VERSION "HNNBNNNYNNNNNNNNNNNNNNNNNNNNNNNNNNNNNNNNNN/4/%%%/4/'%**4NNN///"

NS_ :

BS_:

BU_: AFS Airbag Allrad BAP_Tester BMS_Hybrid Bremse_MK60EC Bremse_MK70MABS Bremse_TRW_EBC450M Bremse_TRW_ESP Daempfer EPB_TRW EPB_TRW_VW411CS FLA Gateway_PQ35 Gateway_Zusatz_EGolf Getriebe_AG6 Getriebe_DQ Getriebe_DQ_Hyb Getriebe_Sele Gurtmikro_PQ35 HCA Ladegeraet_EGolf LEH_Hybrid LH_EPS_APA LH_EPS_ZF_2G LH_EPS_ZF_3G LPG_Interface_Box LWR LWS Magne_Ride Motor_Diesel Motor_EGolf Motor_Hybrid Motor_Otto PDC_PLA Quersperre_VAQ RKA_Plus SAK Waehlhebel Waehlhebel_Sele

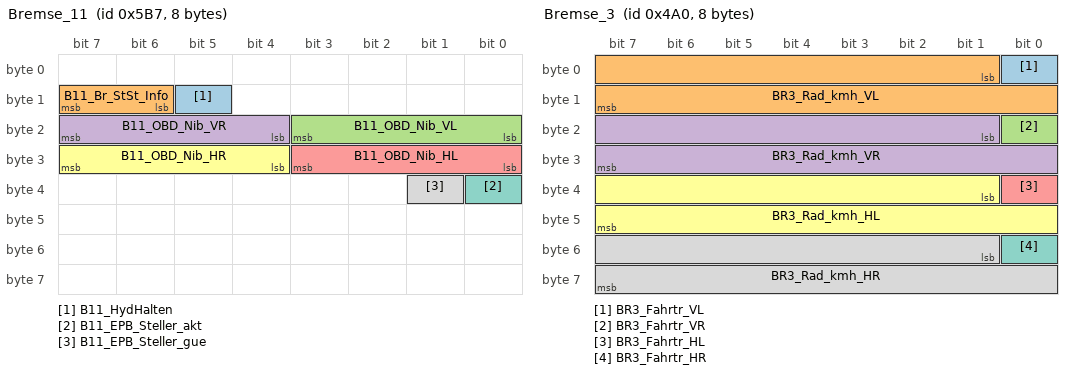
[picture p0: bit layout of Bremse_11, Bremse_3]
BO_ 1463 Bremse_11: 8 Bremse_MK60EC
 SG_ B11_HydHalten : 13|1@1+ (1,0) [0|1] ""  EPB_TRW_VW411CS,Getriebe_DQ,Getriebe_DQ_Hyb,Motor_Diesel,Motor_Otto,PDC_PLA
 SG_ B11_Br_StSt_Info : 14|2@1+ (1,0) [0|3] ""  EPB_TRW_VW411CS,Motor_Diesel,Motor_Otto
 SG_ B11_OBD_Nib_VL : 16|4@1+ (1,0) [0|15] ""  Motor_Diesel,Motor_Otto
 SG_ B11_OBD_Nib_VR : 20|4@1+ (1,0) [0|15] ""  Motor_Diesel,Motor_Otto
 SG_ B11_OBD_Nib_HL : 24|4@1+ (1,0) [0|15] ""  Motor_Diesel,Motor_Otto
 SG_ B11_OBD_Nib_HR : 28|4@1+ (1,0) [0|15] ""  Motor_Diesel,Motor_Otto
 SG_ B11_EPB_Steller_akt : 32|1@1+ (1,0) [0|1] ""  Motor_Diesel,Motor_Otto
 SG_ B11_EPB_Steller_gue : 33|1@1+ (1,0) [0|1] ""  Motor_Diesel,Motor_Otto

BO_ 1440 Bremse_2: 8 Bremse_MK60EC
 SG_ BR2_Querbeschl m0 : 0|8@1+ (0.01,-1.27) [-1.27|1.27] "Unit_ForceOfGravi"  AFS,Allrad,Daempfer,Gateway_PQ35,Getriebe_DQ,Getriebe_DQ_Hyb,Getriebe_Sele,HCA,LWR,Magne_Ride,Motor_Diesel,Motor_Otto,RKA_Plus
 SG_ BR2_Zahnzahl m1 : 0|6@1+ (1,0) [0|63] ""  Gateway_PQ35,Getriebe_DQ,Getriebe_DQ_Hyb,PDC_PLA,RKA_Plus
 SG_ BR2_Querb_Zahn M : 8|1@1+ (1,0) [0|1] ""  AFS,Allrad,Daempfer,Gateway_PQ35,Getriebe_DQ,Getriebe_DQ_Hyb,Getriebe_Sele,HCA,LWR,Magne_Ride,Motor_Diesel,Motor_Otto,PDC_PLA,RKA_Plus
 SG_ BR2_mi_Radgeschw : 9|15@1+ (0.002,0) [0|65.278] "Unit_Hertz"  Gateway_PQ35,Getriebe_DQ,Getriebe_DQ_Hyb
 SG_ BR2_Lampe_ABS : 24|1@1+ (1,0) [0|1] ""  Airbag,Gateway_PQ35
 SG_ BR2_Lampe_ASR : 25|1@1+ (1,0) [0|1] ""  Gateway_PQ35,PDC_PLA
 SG_ BR2_Lampe_BK : 26|1@1+ (1,0) [0|1] ""  Gateway_PQ35
 SG_ BR2_Lampe_RKA : 27|1@1+ (1,0) [0|1] ""  Gateway_PQ35
 SG_ BR2_Zaehler : 28|4@1+ (1,0) [0|15] ""  Daempfer,Gateway_PQ35,HCA,Magne_Ride
 SG_ BR2_Text : 32|4@1+ (1,0) [0|15] ""  Gateway_PQ35
 SG_ BR2_Aku_Warn : 36|2@1+ (1,0) [0|3] ""  Gateway_PQ35
 SG_ BR2_HDC_aktiv : 38|1@1+ (1,0) [0|1] ""  Gateway_PQ35,Getriebe_DQ,Getriebe_DQ_Hyb,Motor_Diesel,Motor_Hybrid,Motor_Otto
 SG_ BR2_Blinkmode : 39|1@1+ (1,0) [0|1] ""  Gateway_PQ35
 SG_ BR2_Wegimpulse : 40|11@1+ (1,0) [0|2047] ""  Gateway_PQ35,Getriebe_DQ,Getriebe_DQ_Hyb
 SG_ BR2_Ueberl_Imp : 51|1@1+ (1,0) [0|1] ""  Gateway_PQ35
 SG_ BR2_Fehlereintr : 52|1@1+ (1,0) [0|1] ""  Gateway_PQ35
 SG_ BR2_LampeHDC : 53|1@1+ (1,0) [0|1] ""  Gateway_PQ35,Getriebe_DQ,Getriebe_DQ_Hyb
 SG_ BR2_QB_Querbeschl m0 : 54|1@1+ (1,0) [0|1] ""  AFS,Allrad,Gateway_PQ35,HCA,LWR,Magne_Ride,Motor_Diesel,Motor_Otto,RKA_Plus
 SG_ BR2_Sta_Imp : 55|1@1+ (1,0) [0|1] ""  Gateway_PQ35
 SG_ BR2_Impulszahl : 56|6@1+ (1,0) [0|63] ""  Gateway_PQ35,Getriebe_DQ,Getriebe_DQ_Hyb
 SG_ BR2_SleepInd : 62|1@1+ (1,0) [0|1] ""  Gateway_PQ35
 SG_ BR2_Sta_Quer : 63|1@1+ (1,0) [0|1] ""  Gateway_PQ35,Getriebe_DQ,Getriebe_DQ_Hyb

BO_ 1184 Bremse_3: 8 Bremse_MK60EC
 SG_ BR3_Fahrtr_VL : 0|1@1+ (1,0) [0|1] ""  AFS,EPB_TRW_VW411CS,Gateway_PQ35,LWR,Magne_Ride
 SG_ BR3_Rad_kmh_VL : 1|15@1+ (0.01,0) [0|326.39] "Unit_KiloMeterPerHour"  AFS,Allrad,EPB_TRW,EPB_TRW_VW411CS,Gateway_PQ35,Getriebe_AG6,Getriebe_DQ,Getriebe_DQ_Hyb,Getriebe_Sele,LH_EPS_APA,LH_EPS_ZF_2G,LH_EPS_ZF_3G,LWR,LWS,Magne_Ride,Motor_Diesel,Motor_EGolf,Motor_Hybrid,Motor_Otto,PDC_PLA
 SG_ BR3_Fahrtr_VR : 16|1@1+ (1,0) [0|1] ""  AFS,EPB_TRW_VW411CS,Gateway_PQ35,LWR,Magne_Ride
 SG_ BR3_Rad_kmh_VR : 17|15@1+ (0.01,0) [0|326.39] "Unit_KiloMeterPerHour"  AFS,Allrad,EPB_TRW,EPB_TRW_VW411CS,Gateway_PQ35,Getriebe_AG6,Getriebe_DQ,Getriebe_DQ_Hyb,Getriebe_Sele,LH_EPS_APA,LH_EPS_ZF_2G,LH_EPS_ZF_3G,LWR,LWS,Magne_Ride,Motor_Diesel,Motor_EGolf,Motor_Hybrid,Motor_Otto,PDC_PLA
 SG_ BR3_Fahrtr_HL : 32|1@1+ (1,0) [0|1] ""  EPB_TRW_VW411CS,Gateway_PQ35,Magne_Ride
 SG_ BR3_Rad_kmh_HL : 33|15@1+ (0.01,0) [0|326.39] "Unit_KiloMeterPerHour"  AFS,Allrad,EPB_TRW,EPB_TRW_VW411CS,Gateway_PQ35,Getriebe_AG6,Getriebe_DQ,Getriebe_DQ_Hyb,Getriebe_Sele,LH_EPS_APA,LH_EPS_ZF_2G,LH_EPS_ZF_3G,LWR,LWS,Magne_Ride,Motor_Diesel,Motor_EGolf,Motor_Hybrid,Motor_Otto,PDC_PLA
 SG_ BR3_Fahrtr_HR : 48|1@1+ (1,0) [0|1] ""  EPB_TRW_VW411CS,Gateway_PQ35,Magne_Ride
 SG_ BR3_Rad_kmh_HR : 49|15@1+ (0.01,0) [0|326.39] "Unit_KiloMeterPerHour"  AFS,Allrad,EPB_TRW,EPB_TRW_VW411CS,Gateway_PQ35,Getriebe_AG6,Getriebe_DQ,Getriebe_DQ_Hyb,Getriebe_Sele,LH_EPS_APA,LH_EPS_ZF_2G,LH_EPS_ZF_3G,LWR,LWS,Magne_Ride,Motor_Diesel,Motor_EGolf,Motor_Hybrid,Motor_Otto,PDC_PLA

BO_ 672 Bremse_4: 8 Bremse_MK60EC
 SG_ BR4_Vorgabe_Mi_ m0 : 0|8@1+ (7,-896) [-896|882] "Unit_NewtoMeter"  Allrad,Gateway_PQ35
 SG_ BR4_Vorgabe_Mi m1 : 0|8@1+ (0.78740157480315,-100) [0|100] "Unit_PerCent"  Gateway_PQ35
 SG_ BR4_Vorgabe_Max m2 : 0|8@1+ (10,0) [0|2540] "Unit_NewtoMeter"  Gateway_PQ35,Quersperre_VAQ
 SG_ BR4_Vorgabe_Hi m1 : 8|8@1+ (0.78740157480315,-100) [0|100] "Unit_PerCent"  Gateway_PQ35
 SG_ BR4_Vorgabe_Min m2 : 8|8@1+ (10,0) [0|2540] "Unit_NewtoMeter"  Gateway_PQ35,Quersperre_VAQ
 SG_ BR4_Einheit M : 16|2@1+ (1,0) [0|3] ""  Allrad,Gateway_PQ35,Quersperre_VAQ
 SG_ BR4_Schwelle : 18|2@1+ (1,0) [0|3] ""  Gateway_PQ35,Getriebe_AG6,Motor_Hybrid,Motor_Otto
 SG_ BR4_Abschaltung_VL : 20|1@1+ (1,0) [0|1] ""  Gateway_PQ35
 SG_ BR4_Abschaltung_VR : 21|1@1+ (1,0) [0|1] ""  Gateway_PQ35
 SG_ BR4_Abschaltung_HL : 22|1@1+ (1,0) [0|1] ""  Gateway_PQ35
 SG_ BR4_Abschaltung_HR : 23|1@1+ (1,0) [0|1] ""  Gateway_PQ35
 SG_ BR4_Lampe_RKA : 24|1@1+ (1,0) [0|1] ""  Gateway_PQ35
 SG_ BR4_Summer_RKA : 25|1@1+ (1,0) [0|1] ""  Gateway_PQ35
 SG_ BR4_Lampentrennung_gue : 26|1@1+ (1,0) [0|1] ""  Gateway_PQ35
 SG_ BR4_Lampe_ASRESP : 27|1@1+ (1,0) [0|1] ""  Gateway_PQ35
 SG_ BR4_ESP_Off : 28|1@1+ (1,0) [0|1] ""  Gateway_PQ35
 SG_ BR1_ASR_ESP : 29|1@1+ (1,0) [0|1] ""  Gateway_PQ35
 SG_ BR4_RKA_Verbau : 30|2@1+ (1,0) [0|3] ""  Gateway_PQ35
 SG_ BR4_Unterdruck : 32|8@1+ (4,0) [0|1016] "Unit_MilliBar"  Gateway_PQ35,Getriebe_AG6,Motor_Hybrid,Motor_Otto
 SG_ BR4_Status_ESP : 40|4@1+ (1,0) [0|15] ""  Gateway_PQ35,Quersperre_VAQ
 SG_ BR4_Zaehler : 52|4@1+ (1,0) [0|15] ""  Gateway_PQ35,Quersperre_VAQ
 SG_ BR4_Checksum : 56|8@1+ (1,0) [0|255] ""  Gateway_PQ35,Quersperre_VAQ

BO_ 1192 Bremse_5: 8 Bremse_MK60EC
 SG_ BR5_Giergeschw : 0|14@1+ (0.01,0) [0|100] "Unit_DegreOfArcPerSecond"  AFS,Allrad,Daempfer,FLA,Gateway_PQ35,HCA,LWR,Magne_Ride,PDC_PLA,RKA_Plus
 SG_ BR5_Sta_Gierrate : 14|1@1+ (1,0) [0|1] ""  AFS,Allrad,Daempfer,FLA,Gateway_PQ35,HCA,LWR,Magne_Ride,PDC_PLA,RKA_Plus
 SG_ BR5_Vorzeichen : 15|1@1+ (1,0) [0|1] ""  AFS,Allrad,Daempfer,FLA,Gateway_PQ35,HCA,LWR,Magne_Ride,PDC_PLA,RKA_Plus
 SG_ BR5_Bremsdruck : 16|12@1+ (0.1,0) [0|409.4] "Unit_Bar"  Daempfer,EPB_TRW,EPB_TRW_VW411CS,Gateway_PQ35,Gateway_Zusatz_EGolf,Getriebe_DQ,Getriebe_DQ_Hyb,HCA,Magne_Ride,Motor_Diesel,Motor_Otto,PDC_PLA
 SG_ BR5_Stillstand : 28|1@1+ (1,0) [0|1] ""  Gateway_PQ35,HCA,Magne_Ride,PDC_PLA
 SG_ BR5_Druckgueltig : 29|1@1+ (1,0) [0|1] ""  Daempfer,EPB_TRW,EPB_TRW_VW411CS,Gateway_PQ35,Getriebe_DQ,Getriebe_DQ_Hyb,HCA,Magne_Ride,Motor_Diesel,Motor_Otto,PDC_PLA
 SG_ BR5_Sta_Druck : 30|1@1+ (1,0) [0|1] ""  EPB_TRW_VW411CS,Gateway_PQ35
 SG_ BR5_Sign_Druck : 31|1@1+ (1,0) [0|1] ""  Daempfer,EPB_TRW_VW411CS,Gateway_PQ35,Getriebe_DQ,Getriebe_DQ_Hyb,HCA,Magne_Ride,Motor_Diesel,Motor_Otto
 SG_ ESP_Anforderung_EPB : 36|2@1+ (1,0) [0|3] ""  EPB_TRW_VW411CS,Gateway_PQ35
 SG_ ESP_Autohold_aktiv : 38|1@1+ (1,0) [0|1] ""  EPB_TRW_VW411CS,Gateway_PQ35
 SG_ ESP_Autohold_Standby : 39|1@1+ (1,0) [0|1] ""  EPB_TRW_VW411CS,Gateway_PQ35
 SG_ BR5_Anhi_Sta : 40|1@1+ (1,0) [0|1] ""  Gateway_PQ35,Getriebe_DQ,Getriebe_DQ_Hyb
 SG_ BR5_Anhi_akt : 41|1@1+ (1,0) [0|1] ""  Gateway_PQ35,Getriebe_DQ,Getriebe_DQ_Hyb
 SG_ BR5_v_Ueberw : 42|1@1+ (1,0) [0|1] ""  Gateway_PQ35
 SG_ BR5_AnhStabAktiv : 43|1@1+ (1,0) [0|1] ""  Gateway_PQ35
 SG_ BR5_Notbremsung : 44|1@1+ (1,0) [0|1] ""  Gateway_PQ35
 SG_ BR5_Fahrer_tritt_ZBR_Schw : 45|1@1+ (1,0) [0|1] ""  Gateway_PQ35
 SG_ BR5_AWV2_Bremsruck : 46|1@1+ (1,0) [0|1] ""  Gateway_PQ35
 SG_ BR5_AWV2_Fehler : 47|1@1+ (1,0) [0|1] ""  Gateway_PQ35
 SG_ BR5_ZT_Rueckk_Umsetz : 48|1@1+ (1,0) [0|1] ""  Gateway_PQ35
 SG_ BR5_ANB_CM_Rueckk_Umsetz : 49|1@1+ (1,0) [0|1] ""  Gateway_PQ35
 SG_ BR5_ECD_Lampe : 51|1@1+ (1,0) [0|1] ""  Gateway_PQ35
 SG_ BR5_Zaehler : 52|4@1+ (1,0) [0|15] ""  Daempfer,EPB_TRW,EPB_TRW_VW411CS,Gateway_PQ35,HCA,Magne_Ride,Motor_Diesel,Motor_Otto,PDC_PLA
 SG_ BR5_Checksumme : 56|8@1+ (1,0) [0|255] ""  Daempfer,EPB_TRW,EPB_TRW_VW411CS,Gateway_PQ35,HCA,Magne_Ride,Motor_Diesel,Motor_Otto

BO_ 428 Bremse_8: 8 Bremse_MK60EC
 SG_ BR8_Checksumme : 0|8@1+ (1,0) [0|255] ""  EPB_TRW,EPB_TRW_VW411CS,Gateway_PQ35,Getriebe_AG6,Getriebe_DQ,Getriebe_DQ_Hyb,Motor_Diesel,Motor_Otto,PDC_PLA
 SG_ BR8_Zaehler : 8|4@1+ (1,0) [0|15] ""  EPB_TRW,EPB_TRW_VW411CS,Gateway_PQ35,Getriebe_AG6,Motor_Diesel,Motor_Otto,PDC_PLA
 SG_ BR8_Sta_ACC_Anf : 12|1@1+ (1,0) [0|1] ""  Gateway_PQ35,Getriebe_DQ,Motor_Diesel,Motor_Otto
 SG_ BR8_Verz_EPB_akt : 13|1@1+ (1,0) [0|1] ""  EPB_TRW,EPB_TRW_VW411CS,Gateway_PQ35,Motor_Diesel,Motor_Otto
 SG_ BR8_Sta_Br_temp : 14|1@1+ (1,0) [0|1] ""  Gateway_PQ35,Motor_Diesel,Motor_Otto
 SG_ BR8_Sta_Br_Druck : 15|1@1+ (1,0) [0|1] ""  Gateway_PQ35,Motor_Diesel,Motor_Otto
 SG_ BR8_Istbeschl : 32|9@1+ (0.02,-7.22) [-7.22|2.98] "Unit_MeterPerSeconSquar"  Gateway_PQ35,Motor_Diesel,Motor_Otto
 SG_ BR8_Sta_HW_BLS : 41|1@1+ (1,0) [0|1] ""  Gateway_PQ35
 SG_ BR8_QB_LBeschl : 42|1@1+ (1,0) [0|1] ""  EPB_TRW_VW411CS,Gateway_PQ35,Getriebe_DQ,Getriebe_DQ_Hyb,Motor_Diesel,Motor_Otto,PDC_PLA
 SG_ BR8_ESC_Mode : 43|2@1+ (1,0) [0|3] ""  Gateway_PQ35
 SG_ BR8_aktBrSyst : 45|1@1+ (1,0) [0|1] ""  Gateway_PQ35,Motor_Diesel,Motor_Otto
 SG_ BR8_Fa_bremst : 46|1@1+ (1,0) [0|1] ""  Gateway_PQ35,Motor_Diesel,Motor_Otto
 SG_ BR8_StaBrSyst : 47|1@1+ (1,0) [0|1] ""  Gateway_PQ35,Motor_Diesel,Motor_Otto
 SG_ BR8_Laengsbeschl : 48|10@1+ (0.03125,-16) [-15.96875|15.9375] "Unit_MeterPerSeconSquar"  EPB_TRW_VW411CS,Gateway_PQ35,Getriebe_AG6,Getriebe_DQ,Getriebe_DQ_Hyb,Motor_Diesel,Motor_Otto,PDC_PLA
 SG_ BR8_Sta_ADR_BR : 58|1@1+ (1,0) [0|1] ""  Gateway_PQ35,Motor_Diesel,Motor_Otto
 SG_ BR8_Quattro : 59|1@1+ (1,0) [0|1] ""  Gateway_PQ35
 SG_ BR8_Sta_VerzReg : 60|1@1+ (1,0) [0|1] ""  Gateway_PQ35,Motor_Diesel,Motor_Otto
 SG_ BR8_Sta_BLS : 61|1@1+ (1,0) [0|1] ""  Gateway_PQ35,Motor_Diesel,Motor_Otto
 SG_ BR8_Verz_EPB : 62|1@1+ (1,0) [0|1] ""  EPB_TRW,EPB_TRW_VW411CS,Gateway_PQ35
 SG_ BR8_Check_EPB : 63|1@1+ (1,0) [0|1] ""  EPB_TRW_VW411CS,Gateway_PQ35

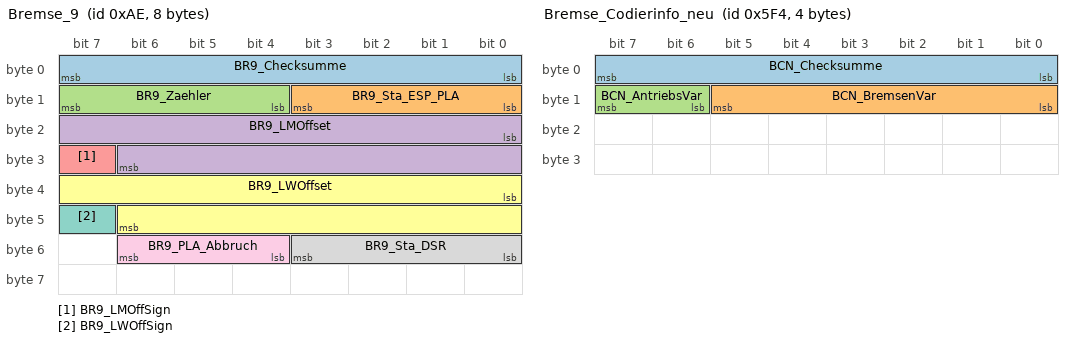
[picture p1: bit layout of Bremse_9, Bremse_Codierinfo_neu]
BO_ 174 Bremse_9: 8 Bremse_MK60EC
 SG_ BR9_Checksumme : 0|8@1+ (1,0) [0|255] ""  LH_EPS_APA,LH_EPS_ZF_2G,LH_EPS_ZF_3G
 SG_ BR9_Sta_ESP_PLA : 8|4@1+ (1,0) [0|15] ""  Getriebe_DQ,Getriebe_DQ_Hyb,PDC_PLA
 SG_ BR9_Zaehler : 12|4@1+ (1,0) [0|15] ""  LH_EPS_APA,LH_EPS_ZF_2G,LH_EPS_ZF_3G
 SG_ BR9_LMOffset : 16|15@1+ (0.0003052,0) [0|10.0004884] "Unit_NewtoMeter"  LH_EPS_APA,LH_EPS_ZF_2G,LH_EPS_ZF_3G
 SG_ BR9_LMOffSign : 31|1@1+ (1,0) [0|1] ""  LH_EPS_APA,LH_EPS_ZF_2G,LH_EPS_ZF_3G
 SG_ BR9_LWOffset : 32|15@1+ (0.04375,0) [0|1433.55625] "Unit_DegreOfArc"  LH_EPS_APA,LH_EPS_ZF_2G,LH_EPS_ZF_3G
 SG_ BR9_LWOffSign : 47|1@1+ (1,0) [0|1] ""  LH_EPS_APA,LH_EPS_ZF_2G,LH_EPS_ZF_3G
 SG_ BR9_Sta_DSR : 48|4@1+ (1,0) [0|15] ""  LH_EPS_APA,LH_EPS_ZF_2G,LH_EPS_ZF_3G
 SG_ BR9_PLA_Abbruch : 52|3@1+ (1,0) [0|7] ""  PDC_PLA

BO_ 1524 Bremse_Codierinfo_neu: 4 Airbag
 SG_ BCN_Checksumme : 0|8@1+ (1,0) [0|255] ""  Bremse_MK60EC
 SG_ BCN_BremsenVar : 8|6@1+ (1,0) [0|63] ""  Bremse_MK60EC
 SG_ BCN_AntriebsVar : 14|2@1+ (1,0) [0|3] ""  Bremse_MK60EC

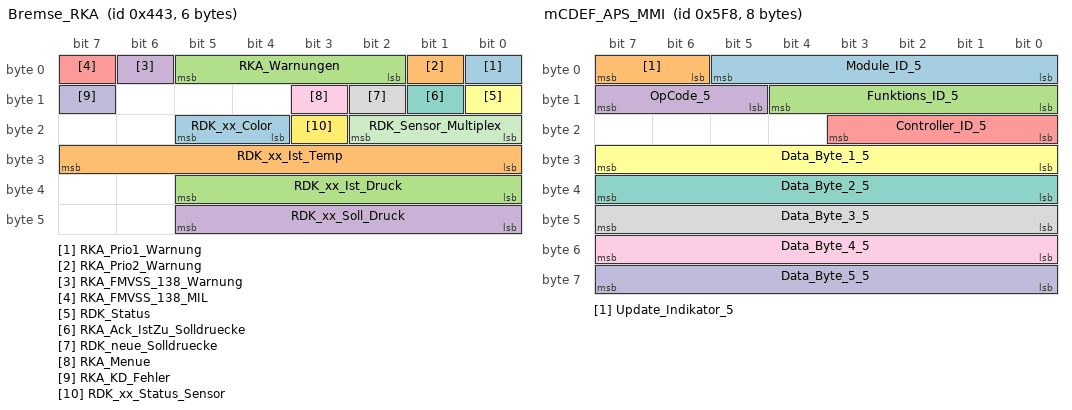
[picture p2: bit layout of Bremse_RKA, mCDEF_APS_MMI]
BO_ 1091 Bremse_RKA: 6 Bremse_MK60EC
 SG_ RKA_Prio1_Warnung : 0|1@1+ (1,0) [0|1] ""  Gateway_PQ35
 SG_ RKA_Prio2_Warnung : 1|1@1+ (1,0) [0|1] ""  Gateway_PQ35
 SG_ RKA_Warnungen : 2|4@1+ (1,0) [0|15] ""  Gateway_PQ35
 SG_ RKA_FMVSS_138_Warnung : 6|1@1+ (1,0) [0|1] ""  Gateway_PQ35
 SG_ RKA_FMVSS_138_MIL : 7|1@1+ (1,0) [0|1] ""  Gateway_PQ35
 SG_ RDK_Status : 8|1@1+ (1,0) [0|1] ""  Gateway_PQ35
 SG_ RKA_Ack_IstZu_Solldruecke : 9|1@1+ (1,0) [0|1] ""  Gateway_PQ35
 SG_ RDK_neue_Solldruecke : 10|1@1+ (1,0) [0|1] ""  Gateway_PQ35
 SG_ RKA_Menue : 11|1@1+ (1,0) [0|1] ""  Gateway_PQ35
 SG_ RKA_KD_Fehler : 15|1@1+ (1,0) [0|1] ""  Gateway_PQ35
 SG_ RDK_Sensor_Multiplex : 16|3@1+ (1,0) [0|7] ""  Gateway_PQ35
 SG_ RDK_xx_Status_Sensor : 19|1@1+ (1,0) [0|1] ""  Gateway_PQ35
 SG_ RDK_xx_Color : 20|2@1+ (1,0) [0|3] ""  Gateway_PQ35
 SG_ RDK_xx_Ist_Temp : 24|8@1+ (1,-60) [-60|194] "Unit_DegreCelsi"  Gateway_PQ35
 SG_ RDK_xx_Ist_Druck : 32|6@1+ (0.1,0) [0|6.3] "Unit_Bar"  Gateway_PQ35
 SG_ RDK_xx_Soll_Druck : 40|6@1+ (0.1,0) [0|6.3] "Unit_Bar"  Gateway_PQ35

BO_ 1392 BSG_Last: 5 Gateway_PQ35
 SG_ BSL_ZAS_Kl_S : 0|1@1+ (1,0) [0|1] ""  EPB_TRW,EPB_TRW_VW411CS,Gurtmikro_PQ35,Ladegeraet_EGolf
 SG_ BSL_ZAS_Kl_15 : 1|1@1+ (1,0) [0|1] ""  BMS_Hybrid,Bremse_MK60EC,Bremse_TRW_EBC450M,Bremse_TRW_ESP,EPB_TRW,EPB_TRW_VW411CS,FLA,Gurtmikro_PQ35,Ladegeraet_EGolf,Motor_EGolf,PDC_PLA
 SG_ BSL_ZAS_Kl_X : 2|1@1+ (1,0) [0|1] ""  AFS,EPB_TRW,EPB_TRW_VW411CS,FLA,HCA,LWR,Motor_Diesel,PDC_PLA
 SG_ BSL_ZAS_Kl_50 : 3|1@1+ (1,0) [0|1] ""  AFS,Bremse_TRW_EBC450M,EPB_TRW,EPB_TRW_VW411CS,LH_EPS_APA,LWR,Magne_Ride,Motor_Diesel,Motor_EGolf
 SG_ BSL_Parklicht : 4|1@1+ (1,0) [0|1] "" Vector__XXX
 SG_ BSL_LL_Anheb2 : 5|1@1+ (1,0) [0|1] ""  Motor_Diesel,Motor_EGolf,Motor_Hybrid,Motor_Otto
 SG_ BSL_Kl_15_Motor : 6|1@1+ (1,0) [0|1] "" Vector__XXX
 SG_ BSL_Kl_L : 7|1@1+ (1,0) [0|1] "" Vector__XXX
 SG_ BSL_LL_Anheb : 8|1@1+ (1,0) [0|1] ""  Motor_Diesel,Motor_EGolf,Motor_Hybrid,Motor_Otto
 SG_ BSL_Sta_UBat : 9|2@1+ (1,0) [0|3] ""  EPB_TRW
 SG_ BSL_Sta_StBat : 11|2@1+ (1,0) [0|3] "" Vector__XXX
 SG_ BSL_Fehlereintr : 13|1@1+ (1,0) [0|1] "" Vector__XXX
 SG_ BSL_Sta_LWR : 14|1@1+ (1,0) [0|1] "" Vector__XXX
 SG_ BSL_Motor_Haube : 15|1@1+ (1,0) [0|1] ""  Motor_Diesel,Motor_EGolf,Motor_Hybrid,Motor_Otto
 SG_ BSL_UBat : 16|8@1+ (0.05,5) [5|17.7] "Unit_Volt"  EPB_TRW
 SG_ BSL_Hecksch : 24|1@1+ (1,0) [0|1] "" Vector__XXX
 SG_ BSL_Frontsch : 25|1@1+ (1,0) [0|1] "" Vector__XXX
 SG_ BSL_Aussensp : 26|1@1+ (1,0) [0|1] "" Vector__XXX
 SG_ BSL_Sitzheiz : 27|1@1+ (1,0) [0|1] "" Vector__XXX
 SG_ BSL_Lenkradheiz : 28|1@1+ (1,0) [0|1] "" Vector__XXX
 SG_ BSL_Wasserheiz : 29|1@1+ (1,0) [0|1] "" Vector__XXX
 SG_ BSL_Sitzbelueft : 30|1@1+ (1,0) [0|1] "" Vector__XXX
 SG_ BSL_Clima : 31|1@1+ (1,0) [0|1] ""  Motor_Diesel,Motor_EGolf,Motor_Hybrid,Motor_Otto
 SG_ BSL_BSG_2_alt : 32|1@1+ (1,0) [0|1] ""  Motor_Diesel,Motor_EGolf,Motor_Hybrid,Motor_Otto
 SG_ BSL_BSG_3_alt : 33|1@1+ (1,0) [0|1] ""  BMS_Hybrid,Bremse_MK60EC,Bremse_TRW_EBC450M,Bremse_TRW_ESP,EPB_TRW_VW411CS,FLA,Gurtmikro_PQ35,HCA,Ladegeraet_EGolf,LH_EPS_APA,Motor_Diesel,Motor_EGolf,Motor_Hybrid,Motor_Otto,PDC_PLA
 SG_ BSL_Kuehlerlueft : 34|1@1+ (1,0) [0|1] ""  LH_EPS_ZF_2G,LH_EPS_ZF_3G,Motor_Diesel,Motor_EGolf,Motor_Hybrid,Motor_Otto
 SG_ BSL_Ab_Batterie : 35|1@1+ (1,0) [0|1] ""  LH_EPS_APA,LH_EPS_ZF_2G,LH_EPS_ZF_3G,Motor_Diesel,Motor_EGolf,Motor_Hybrid,Motor_Otto
 SG_ BSL_Weckursache_ACAN : 36|2@1+ (1,0) [0|3] ""  Motor_EGolf,Motor_Hybrid,Motor_Otto
 SG_ BSL_Wake_Up_ACAN : 38|1@1+ (1,0) [0|1] ""  Motor_EGolf,Motor_Hybrid,Motor_Otto
 SG_ BSL_Starterlaubnis : 39|1@1+ (1,0) [0|1] ""  Bremse_MK60EC,Bremse_TRW_EBC450M,Bremse_TRW_ESP,Motor_Diesel,Motor_Otto

BO_ 1528 mCDEF_APS_MMI: 8 PDC_PLA
 SG_ Module_ID_5 : 0|6@1+ (1,0) [0|63] ""  Gateway_PQ35
 SG_ Update_Indikator_5 : 6|2@1+ (1,0) [0|3] ""  Gateway_PQ35
 SG_ Funktions_ID_5 : 8|5@1+ (1,0) [0|31] ""  Gateway_PQ35
 SG_ OpCode_5 : 13|3@1+ (1,0) [0|7] ""  Gateway_PQ35
 SG_ Controller_ID_5 : 16|4@1+ (1,0) [0|15] ""  Gateway_PQ35
 SG_ Data_Byte_1_5 : 24|8@1+ (1,0) [0|255] ""  Gateway_PQ35
 SG_ Data_Byte_2_5 : 32|8@1+ (1,0) [0|255] ""  Gateway_PQ35
 SG_ Data_Byte_3_5 : 40|8@1+ (1,0) [0|255] ""  Gateway_PQ35
 SG_ Data_Byte_4_5 : 48|8@1+ (1,0) [0|255] ""  Gateway_PQ35
 SG_ Data_Byte_5_5 : 56|8@1+ (1,0) [0|255] ""  Gateway_PQ35

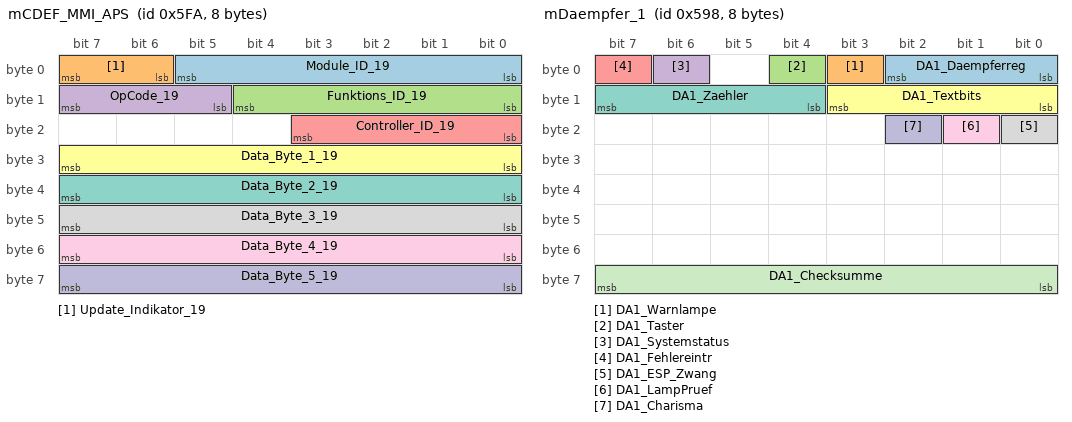
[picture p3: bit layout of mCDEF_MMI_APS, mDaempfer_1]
BO_ 1530 mCDEF_MMI_APS: 8 Gateway_PQ35
 SG_ Module_ID_19 : 0|6@1+ (1,0) [0|63] ""  PDC_PLA
 SG_ Update_Indikator_19 : 6|2@1+ (1,0) [0|3] ""  PDC_PLA
 SG_ Funktions_ID_19 : 8|5@1+ (1,0) [0|31] ""  PDC_PLA
 SG_ OpCode_19 : 13|3@1+ (1,0) [0|7] ""  PDC_PLA
 SG_ Controller_ID_19 : 16|4@1+ (1,0) [0|15] ""  PDC_PLA
 SG_ Data_Byte_1_19 : 24|8@1+ (1,0) [0|255] ""  PDC_PLA
 SG_ Data_Byte_2_19 : 32|8@1+ (1,0) [0|255] ""  PDC_PLA
 SG_ Data_Byte_3_19 : 40|8@1+ (1,0) [0|255] ""  PDC_PLA
 SG_ Data_Byte_4_19 : 48|8@1+ (1,0) [0|255] ""  PDC_PLA
 SG_ Data_Byte_5_19 : 56|8@1+ (1,0) [0|255] ""  PDC_PLA

BO_ 1504 Clima_1: 8 Gateway_PQ35
 SG_ CL1_LL_Dz : 0|1@1+ (1,0) [0|1] ""  Motor_Diesel,Motor_EGolf,Motor_Hybrid,Motor_Otto
 SG_ CL1_Fa_Zuheiz : 1|1@1+ (1,0) [0|1] ""  Motor_Diesel,Motor_EGolf,Motor_Hybrid
 SG_ CL1_Hecksch : 2|1@1+ (1,0) [0|1] "" Vector__XXX
 SG_ CL1_Frontsch : 3|1@1+ (1,0) [0|1] "" Vector__XXX
 SG_ CL1_Kompressor : 4|1@1+ (1,0) [0|1] ""  Motor_Diesel,Motor_EGolf,Motor_Hybrid,Motor_Otto
 SG_ CL1_Heizleist : 5|1@1+ (1,0) [0|1] ""  Motor_Diesel
 SG_ CL1_Sta_Moment : 6|1@1+ (1,0) [0|1] ""  Motor_EGolf,Motor_Hybrid,Motor_Otto
 SG_ CL1_Sta_Druck : 7|1@1+ (1,0) [0|1] ""  Motor_EGolf,Motor_Hybrid,Motor_Otto
 SG_ CL1_Aussentemp : 8|8@1+ (0.5,-50) [-50|77] "Unit_DegreCelsi" Vector__XXX
 SG_ CL1_Druck : 16|8@1+ (0.2,0) [0|50.8] "Unit_Bar"  Motor_Diesel,Motor_EGolf,Motor_Hybrid,Motor_Otto
 SG_ CL1_Kompr_Last : 24|8@1+ (0.25,0) [0|63.5] "Unit_NewtoMeter"  Motor_Diesel,Motor_EGolf,Motor_Hybrid,Motor_Otto
 SG_ CL1_Gebl_last : 32|8@1+ (0.4,0) [0|100] "Unit_PerCent"  BMS_Hybrid,Motor_Otto
 SG_ CL1_Luefter : 40|8@1+ (0.4,0) [0|100] "Unit_PerCent"  Motor_Diesel,Motor_EGolf,Motor_Hybrid,Motor_Otto
 SG_ CL1_Einheit_Temp : 48|1@1+ (1,0) [0|1] "" Vector__XXX
 SG_ CL1_AC_Schalter : 49|1@1+ (1,0) [0|1] ""  Motor_Diesel,Motor_EGolf,Motor_Hybrid,Motor_Otto
 SG_ CL1_WAPU_Zuschaltung : 50|1@1+ (1,0) [0|1] "" Vector__XXX
 SG_ CL1_Restwaerme : 51|1@1+ (1,0) [0|1] "" Vector__XXX
 SG_ CL1_PTC_Hzg : 52|3@1+ (25,0) [0|100] "Unit_PerCent"  Ladegeraet_EGolf
 SG_ CL1_Fehlereintr : 55|1@1+ (1,0) [0|1] "" Vector__XXX
 SG_ KL_Thermomanagement : 56|2@1+ (1,0) [0|3] ""  Motor_Diesel,Motor_EGolf,Motor_Hybrid,Motor_Otto

BO_ 1432 mDaempfer_1: 8 Daempfer
 SG_ DA1_Daempferreg : 0|3@1+ (1,0) [0|7] ""  Gateway_PQ35
 SG_ DA1_Warnlampe : 3|1@1+ (1,0) [0|1] ""  Gateway_PQ35
 SG_ DA1_Taster : 4|1@1+ (1,0) [0|1] ""  Gateway_PQ35
 SG_ DA1_Systemstatus : 6|1@1+ (1,0) [0|1] ""  Gateway_PQ35
 SG_ DA1_Fehlereintr : 7|1@1+ (1,0) [0|1] ""  Gateway_PQ35
 SG_ DA1_Textbits : 8|4@1+ (1,0) [0|15] ""  Gateway_PQ35
 SG_ DA1_Zaehler : 12|4@1+ (1,0) [0|15] ""  Bremse_MK60EC,Gateway_PQ35
 SG_ DA1_ESP_Zwang : 16|1@1+ (1,0) [0|1] ""  Bremse_MK60EC,Gateway_PQ35
 SG_ DA1_LampPruef : 17|1@1+ (1,0) [0|1] ""  Gateway_PQ35
 SG_ DA1_Charisma : 18|1@1+ (1,0) [0|1] ""  Gateway_PQ35
 SG_ DA1_Checksumme : 56|8@1+ (1,0) [0|255] ""  Bremse_MK60EC,Gateway_PQ35

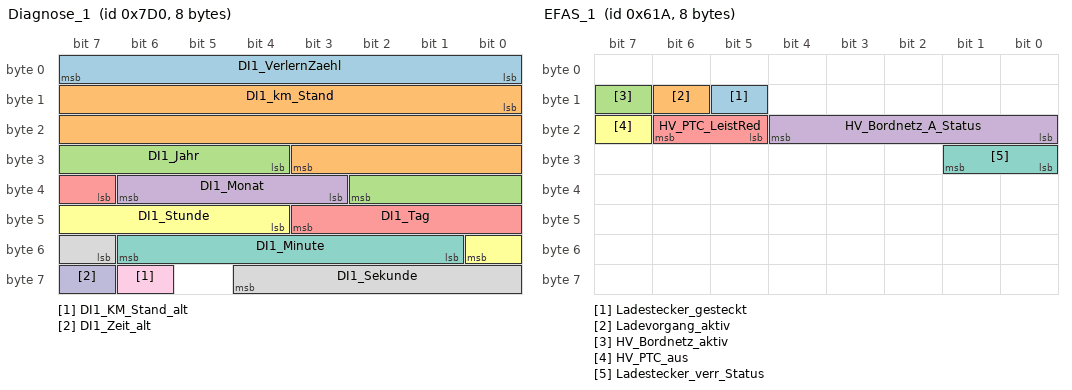
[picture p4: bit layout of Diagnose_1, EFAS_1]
BO_ 2000 Diagnose_1: 8 Gateway_PQ35
 SG_ DI1_VerlernZaehl : 0|8@1+ (1,0) [0|254] ""  AFS,Airbag,Allrad,BMS_Hybrid,Bremse_MK60EC,Bremse_TRW_EBC450M,Bremse_TRW_ESP,Daempfer,EPB_TRW,EPB_TRW_VW411CS,FLA,Getriebe_DQ,Getriebe_DQ_Hyb,Gurtmikro_PQ35,HCA,LEH_Hybrid,LH_EPS_APA,LWR,Magne_Ride,Motor_Diesel,Motor_EGolf,Motor_Hybrid,Motor_Otto,PDC_PLA,Quersperre_VAQ,RKA_Plus
 SG_ DI1_km_Stand : 8|20@1+ (1,0) [0|1048575] "Unit_KiloMeter"  AFS,Airbag,Allrad,BMS_Hybrid,Bremse_TRW_EBC450M,Bremse_TRW_ESP,Daempfer,EPB_TRW,EPB_TRW_VW411CS,FLA,Getriebe_DQ,Getriebe_DQ_Hyb,Gurtmikro_PQ35,HCA,LEH_Hybrid,LH_EPS_APA,LWR,Magne_Ride,Motor_Diesel,Motor_EGolf,Motor_Hybrid,Motor_Otto,PDC_PLA,Quersperre_VAQ,RKA_Plus
 SG_ DI1_Jahr : 28|7@1+ (1,2000) [2000|2127] "Unit_Year"  AFS,Airbag,Allrad,BMS_Hybrid,Bremse_MK60EC,Bremse_MK70MABS,Bremse_TRW_EBC450M,Bremse_TRW_ESP,Daempfer,EPB_TRW,EPB_TRW_VW411CS,FLA,Getriebe_DQ,Getriebe_DQ_Hyb,Gurtmikro_PQ35,HCA,LEH_Hybrid,LH_EPS_APA,LH_EPS_ZF_2G,LH_EPS_ZF_3G,LWR,Magne_Ride,Motor_Diesel,Motor_EGolf,Motor_Hybrid,Motor_Otto,PDC_PLA,Quersperre_VAQ,RKA_Plus
 SG_ DI1_Monat : 35|4@1+ (1,0) [1|12] "Unit_Month"  AFS,Airbag,Allrad,BMS_Hybrid,Bremse_MK60EC,Bremse_MK70MABS,Bremse_TRW_EBC450M,Bremse_TRW_ESP,Daempfer,EPB_TRW,EPB_TRW_VW411CS,FLA,Getriebe_DQ,Getriebe_DQ_Hyb,Gurtmikro_PQ35,HCA,LEH_Hybrid,LH_EPS_APA,LH_EPS_ZF_2G,LH_EPS_ZF_3G,LWR,Magne_Ride,Motor_Diesel,Motor_EGolf,Motor_Hybrid,Motor_Otto,PDC_PLA,Quersperre_VAQ,RKA_Plus
 SG_ DI1_Tag : 39|5@1+ (1,0) [0|31] "Unit_Day"  AFS,Airbag,Allrad,BMS_Hybrid,Bremse_MK60EC,Bremse_MK70MABS,Bremse_TRW_EBC450M,Bremse_TRW_ESP,Daempfer,EPB_TRW,EPB_TRW_VW411CS,FLA,Getriebe_DQ,Getriebe_DQ_Hyb,Gurtmikro_PQ35,HCA,LEH_Hybrid,LH_EPS_APA,LH_EPS_ZF_2G,LH_EPS_ZF_3G,LWR,Magne_Ride,Motor_Diesel,Motor_EGolf,Motor_Hybrid,Motor_Otto,PDC_PLA,Quersperre_VAQ,RKA_Plus
 SG_ DI1_Stunde : 44|5@1+ (1,0) [0|23] "Unit_Hours"  AFS,Airbag,Allrad,BMS_Hybrid,Bremse_MK60EC,Bremse_TRW_EBC450M,Bremse_TRW_ESP,Daempfer,EPB_TRW,EPB_TRW_VW411CS,FLA,Getriebe_DQ,Getriebe_DQ_Hyb,Gurtmikro_PQ35,HCA,LEH_Hybrid,LH_EPS_APA,LH_EPS_ZF_2G,LH_EPS_ZF_3G,LWR,Magne_Ride,Motor_Diesel,Motor_EGolf,Motor_Hybrid,Motor_Otto,PDC_PLA,Quersperre_VAQ,RKA_Plus
 SG_ DI1_Minute : 49|6@1+ (1,0) [0|59] "Unit_Minut"  AFS,Airbag,Allrad,BMS_Hybrid,Bremse_MK60EC,Bremse_TRW_EBC450M,Bremse_TRW_ESP,Daempfer,EPB_TRW,EPB_TRW_VW411CS,FLA,Getriebe_DQ,Getriebe_DQ_Hyb,Gurtmikro_PQ35,HCA,LEH_Hybrid,LH_EPS_APA,LH_EPS_ZF_2G,LH_EPS_ZF_3G,LWR,Magne_Ride,Motor_Diesel,Motor_EGolf,Motor_Hybrid,Motor_Otto,PDC_PLA,Quersperre_VAQ,RKA_Plus
 SG_ DI1_Sekunde : 55|6@1+ (1,0) [0|59] "Unit_Secon"  AFS,Airbag,Allrad,BMS_Hybrid,Bremse_MK60EC,Bremse_TRW_EBC450M,Bremse_TRW_ESP,Daempfer,EPB_TRW,EPB_TRW_VW411CS,FLA,Getriebe_DQ,Getriebe_DQ_Hyb,Gurtmikro_PQ35,HCA,LEH_Hybrid,LH_EPS_APA,LH_EPS_ZF_2G,LH_EPS_ZF_3G,LWR,Magne_Ride,Motor_Diesel,Motor_EGolf,Motor_Hybrid,Motor_Otto,PDC_PLA,Quersperre_VAQ,RKA_Plus
 SG_ DI1_KM_Stand_alt : 62|1@1+ (1,0) [0|1] ""  AFS,Airbag,Allrad,BMS_Hybrid,Daempfer,EPB_TRW_VW411CS,FLA,Gurtmikro_PQ35,HCA,LEH_Hybrid,LH_EPS_APA,LWR,Magne_Ride,Motor_Diesel,Motor_Hybrid,Motor_Otto,PDC_PLA,Quersperre_VAQ,RKA_Plus
 SG_ DI1_Zeit_alt : 63|1@1+ (1,0) [0|1] ""  AFS,Airbag,Allrad,BMS_Hybrid,Bremse_MK60EC,Daempfer,EPB_TRW_VW411CS,FLA,Gurtmikro_PQ35,HCA,LEH_Hybrid,LH_EPS_APA,LH_EPS_ZF_2G,LH_EPS_ZF_3G,LWR,Magne_Ride,Motor_Diesel,Motor_Hybrid,Motor_Otto,PDC_PLA,RKA_Plus

BO_ 1562 EFAS_1: 8 Motor_EGolf
 SG_ Ladestecker_gesteckt : 13|1@1+ (1,0) [0|1] ""  Gateway_Zusatz_EGolf,Ladegeraet_EGolf
 SG_ Ladevorgang_aktiv : 14|1@1+ (1,0) [0|1] ""  Gateway_PQ35,Gateway_Zusatz_EGolf
 SG_ HV_Bordnetz_aktiv : 15|1@1+ (1,0) [0|1] ""  Gateway_Zusatz_EGolf,Ladegeraet_EGolf
 SG_ HV_Bordnetz_A_Status : 16|5@1+ (1,0) [0|31] ""  Gateway_Zusatz_EGolf,Ladegeraet_EGolf
 SG_ HV_PTC_LeistRed : 21|2@1+ (1,0) [0|3] ""  Gateway_Zusatz_EGolf
 SG_ HV_PTC_aus : 23|1@1+ (1,0) [0|1] ""  Gateway_Zusatz_EGolf
 SG_ Ladestecker_verr_Status : 24|2@1+ (1,0) [0|3] ""  Gateway_Zusatz_EGolf,Ladegeraet_EGolf

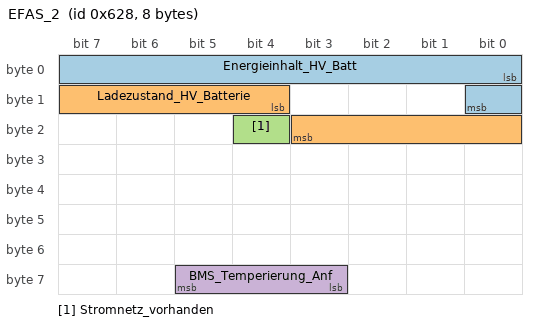
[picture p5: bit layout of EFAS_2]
BO_ 1576 EFAS_2: 8 Motor_EGolf
 SG_ Energieinhalt_HV_Batt : 0|9@1+ (0.1,0) [0|50.9] "Unit_KiloWattHour"  Gateway_Zusatz_EGolf
 SG_ Ladezustand_HV_Batterie : 12|8@1+ (0.5,0) [0|100] "Unit_PerCent"  Gateway_Zusatz_EGolf,Ladegeraet_EGolf
 SG_ Stromnetz_vorhanden : 20|1@1+ (1,0) [0|1] ""  Gateway_Zusatz_EGolf
 SG_ BMS_Temperierung_Anf : 59|3@1+ (1,0) [0|7] ""  Gateway_Zusatz_EGolf

BO_TX_BU_ 1463 : Bremse_MK60EC,Bremse_MK70MABS,Bremse_TRW_EBC450M,Bremse_TRW_ESP;
BO_TX_BU_ 1440 : Bremse_MK60EC,Bremse_MK70MABS,Bremse_TRW_EBC450M,Bremse_TRW_ESP;
BO_TX_BU_ 1184 : Bremse_MK60EC,Bremse_MK70MABS,Bremse_TRW_EBC450M,Bremse_TRW_ESP;
BO_TX_BU_ 672 : Bremse_MK60EC,Bremse_MK70MABS,Bremse_TRW_EBC450M,Bremse_TRW_ESP;
BO_TX_BU_ 1192 : Bremse_MK60EC,Bremse_MK70MABS,Bremse_TRW_EBC450M,Bremse_TRW_ESP;
BO_TX_BU_ 428 : Bremse_MK60EC,Bremse_TRW_EBC450M,Bremse_TRW_ESP;
BO_TX_BU_ 174 : Bremse_MK60EC,Bremse_MK70MABS,Bremse_TRW_EBC450M,Bremse_TRW_ESP;
BO_TX_BU_ 1091 : Bremse_MK60EC,Bremse_TRW_EBC450M,RKA_Plus;
BO_TX_BU_ 1432 : Daempfer,Ladegeraet_EGolf,Magne_Ride;
CM_ SG_ 1463 B11_HydHalten "Das Bit wird gesetzt, wenn das Fahrzeug durch den Berganfahrassistenten (Hill-Hold) oder PLA gehalten wird.
Hydraulisches Halten aktiv (nur in Verbindung mit Autohold)";
CM_ SG_ 1463 B11_Br_StSt_Info "Stopp-Freigabe/Start-Anforderung für den Start-Stopp-Koordinator
(Nicht Start/Stopp-fähige Bremsen-SGs senden die Bremse 11-Botschaft nicht oder konstant den Wert 3 Systemfehler -> Start/Stopp wird durch den Koordinator gesperrt.)";
CM_ SG_ 1463 B11_OBD_Nib_VL "Fehlerstatus des Radsensors vorne links
Da im MSG v-Fhz eine OBD-relevante Größe ist, müssen im Fehlerfall erweiterte Diagnoseinformationen zur Signalquelle mittels GST (Generic Scan Tool) abrufbar sein.
Je nach Schnittstelle Radsensor/Bremsen-SG könne";
CM_ SG_ 1463 B11_OBD_Nib_VR "Fehlerstatus des Radsensors vorne rechts
Da im MSG v-Fhz eine OBD-relevante Größe ist, müssen im Fehlerfall erweiterte Diagnoseinformationen zur Signalquelle mittels GST (Generic Scan Tool) abrufbar sein.
Je nach Schnittstelle Radsensor/Bremsen-SG könn";
CM_ SG_ 1463 B11_OBD_Nib_HL "Fehlerstatus des Radsensors hinten links
Da im MSG v-Fhz eine OBD-relevante Größe ist, müssen im Fehlerfall erweiterte Diagnoseinformationen zur Signalquelle mittels GST (Generic Scan Tool) abrufbar sein.
Je nach Schnittstelle Radsensor/Bremsen-SG könn";
CM_ SG_ 1463 B11_OBD_Nib_HR "Fehlerstatus des Radsensors hinten rechts
Da im MSG v-Fhz eine OBD-relevante Größe ist, müssen im Fehlerfall erweiterte Diagnoseinformationen zur Signalquelle mittels GST (Generic Scan Tool) abrufbar sein.
Je nach Schnittstelle Radsensor/Bremsen-SG kön";
CM_ SG_ 1463 B11_EPB_Steller_akt "Reserviert für Information für Start-Stopp-Koordinator.
Für zukünftige EPB (nach PQ46/VW416) nicht mehr notwendig.
EPB-Steller verfährt";
CM_ SG_ 1463 B11_EPB_Steller_gue "Reserviert für Information für Start-Stopp-Koordinator.
Für zukünftige EPB (nach PQ46/VW416) nicht mehr notwendig.
EPB-Steller-Info gültig";
CM_ SG_ 1440 BR2_Querbeschl "Wenn Byte 2, Bit 0 = 0: errechnete Größe (bei ABS-Systemen) zur Kurvenfahrterkennung für das Getriebe, oder gemessener Sensorwert (siehe Byte 8, Bit 7) (im PQ35 kein Rohwert). Bei Linkskurve positives Vorzeichen.
Achtung: Die Güte bei errechneten Größen ";
CM_ SG_ 1440 BR2_Zahnzahl "Wenn Byte 2, Bit 0 = 1: Zähnezahl des verwendeten Impulsrades";
CM_ SG_ 1440 BR2_Querb_Zahn "Byte 1 hat in der Hochlaufphase (Boschsystem: ca. 2s, Contisystem: ca. 1,7s) eine alternative Bedeutung: Zähnezahl der Impulsräder werden übertragen
Querbeschl./Zähnezahl";
CM_ SG_ 1440 BR2_mi_Radgeschw "Radumdrehungen / Sekunde sind Eingangsgröße für die Geschwindigkeitsberechnung im Kombi; es wird der Mittelwert der permanent angetriebenen Räder (alle außer Audi B6/D3) ausgegeben oder bei Audi B6/D3 die Geschwindigkeit des linken Vorderrades; im Kombi w";
CM_ SG_ 1440 BR2_Lampe_ABS "Sicherheitswarnlampe, siehe Bremse_1 Byte 2, Bit 0 (nicht D1GP/BY61x/MK70 alt)";
CM_ SG_ 1440 BR2_Lampe_ASR "Zustand der Lampe wird auf dem CAN-Bus ausgegeben (auch Blinkinformation)
Fahrzeuge mit ASR/ESP/MABS-Funktionalität bedienen die Sicherheitswarnlampe
Init: 0 (ABS)/1 (ASR/ESP SILA), siehe Bremse_1 Byte 2, Bit 1 (nicht D1GP/BY61x/MK70 alt)";
CM_ SG_ 1440 BR2_Lampe_BK "(Blinktakt wird nur bei Audi wie bisher vom Kombi generiert)
Separate Bremskontroll-Lampe (Audi ab D3/C6) wird als Sicherheitswarnlampe aufgeprüft (Initwert 1)
Kombinierte Bremskontroll-Lampe (VW) wird aufgeprüft, siehe Bremse_1 Byte 2, Bit 2 Zustand de";
CM_ SG_ 1440 BR2_Lampe_RKA "Reifen-Kontroll-Anzeige (indirekt messende Reifendrucküberwachung): siehe Bremse_4 Byte 4, Bit 0 Zustand der Lampe wird auf dem CAN-Bus ausgegeben (auch Blinkinformation)
Fahrzeuge mit ASR/ESP/MABS-Funktionalität bedienen die Sicherheitswarnlampe
Init: ";
CM_ SG_ 1440 BR2_Zaehler "Überlaufender Zähler (nicht D1GP/BY61x/MK70 alt)";
CM_ SG_ 1440 BR2_Text "0 Kein Text
1 'ESP Störung'
2 'ABS Störung'
3 'ESP/ABS Störung'
4 'Werkstatt Bremse'
5 'ASR Störung'
6 'ESP Deaktiviert'
7 'ASR Deaktiviert'
8 'ESP Aktiviert'
9 'Störung Hillholder' (PQ46) 'Anfahrhilfe Fehler Werkstatt' (T5GP)
10 'Keine Bremskra";
CM_ SG_ 1440 BR2_Aku_Warn "1: Bremse steuert den Gong im Kombi ein Mal an (keine Akustik bei VW)
2: Bremse steuert den Gong (Summer bei VW) im Kombi drei Mal an, z. Zt. nur in Kombination mit Text 'Werkstatt Bremse' (Ausfall der EBV)
3: Summeransteuerung ist durch Kombi auf 1 Sek";
CM_ SG_ 1440 BR2_HDC_aktiv "Die Funktion Bergabfahrassistent ist bei gesetztem Bit aktiv oder standby. Das Motor SG nutzt Info zum Umschalten der GRA Funktion. (nur im VW416 und RPU). Das DQ-Getriebe nutzt die Info zur Kupplungsansteuerung.
(nicht D1GP/BY61x/MK70 alt)";
CM_ SG_ 1440 BR2_Blinkmode "Bremskontroll-Lampe soll im Warnfall mit 1Hz blinken, wenn das Bit gesetzt ist (z. Zt. nur bei VW) (nicht D1GP/BY61x/MK70 alt)";
CM_ SG_ 1440 BR2_Wegimpulse "Anzahl der Raddrehzahlimpulse (steigende und fallende Flanke) der Vorderachse (gemittelt) zur Wegstreckenzählung
bei Ausfall eines Drehzahlfühlers wird der funktionsfähige Sensor zur Ausgabe verwendet
Wegimpulse Vorderachse

Im RPU wird die Hinterachs";
CM_ SG_ 1440 BR2_Ueberl_Imp "der Wegimpuls-Zähler ist mindestens einmal übergelaufen (Reset des ABS-Steuergerätes) kann damit erkannt werden
Wegimpulszählerstatus";
CM_ SG_ 1440 BR2_Fehlereintr "Bei gesetztem Bit ist mindestens ein Kundendienstfehler eingetragen";
CM_ SG_ 1440 BR2_LampeHDC "VW416: Funktionslampe Bergabfahrassistent (HDC)
Lampe ist an bei HDC im standby und blinkt mit 3,3 Hz bei aktiver Funktion.
Das DQ-Getriebe nutzt die Info zur Kupplungsansteuerung.

RPU: Funktionslampe Bergabfahrassistent und Offroad-ABS
MK25A-ESP: L";
CM_ SG_ 1440 BR2_QB_Querbeschl "Definition nach CAN-Lastenheft
Hinweis zu CT-ESP: Bit wird auch gesetzt, wenn Querbeschl. bei ESP errechnet statt gemessen wird (nicht Colorado/Colorado GP, nicht D1GP/BY61x)
(ACHTUNG: war Summer Reifendruckwarnung RB im PQ24)";
CM_ SG_ 1440 BR2_Sta_Imp "Fehler wird gesetzt, wenn beide ABS-Drehzahlfühler an der Vorderachse defekt sind
Fehlerstatus Wegimpulse

Im RPU wird die Hinterachse zur Ermittlung der Wegimpulse verwendet!";
CM_ SG_ 1440 BR2_Impulszahl "Zähnezahl des verwendeten Impulsrades
Bei Neuentwicklungen muss die Impulszahl aus Byte 1 (Ausgabe während der Hochlaufphase) verwendet werden";
CM_ SG_ 1440 BR2_SleepInd "Die Sleep-Bereitschaft wird nach Klemme 15 aus durch Setzen dieses Bits signalisiert (nicht VW D1/Colorado, nicht D1GP/BY61x, nicht RB PQ25)
NMHigh-Teilnehmer der PQ35/46 müssen das Signal nach Kl.-15 aus weiterhin bedienen oder dauerhaft auf 1 = 'Sleep ";
CM_ SG_ 1440 BR2_Sta_Quer "Querbeschleunigung in Byte 1 wird errechnet oder beim ESP gemessen";
CM_ SG_ 1184 BR3_Fahrtr_VL "Fahrtrichtungserkennung (im Audi D3/C6 und Colorado)";
CM_ SG_ 1184 BR3_Rad_kmh_VL "Low Byte 1, High Byte 2 (Auflösung 1,28 km/h)
Radgeschwindigkeit bezieht sich auf den 'Kombi 3'  Reifenumfang

Konstanten:
V_INIT = 7FC4H (bzw. FF88H oder FF89H = 1111 1111 1000 100x B in 2-Byte-Schreibweise) (entspricht 327,08 km/h) (nicht Colorado, ";
CM_ SG_ 1184 BR3_Fahrtr_VR "Fahrtrichtungserkennung (im Audi D3/C6 und Colorado)";
CM_ SG_ 1184 BR3_Rad_kmh_VR "Low Byte 3, High Byte 4 (Auflösung 1,28 km/h)
Radgeschwindigkeit bezieht sich auf den 'Kombi 3` Reifenumfang
Konstanten:
V_INIT = 7FC4H (bzw. FF88H oder FF89H = 1111 1111 1000 100x B in 2-Byte-Schreibweise) (entspricht 327,08 km/h) (nicht Colorado, D1G";
CM_ SG_ 1184 BR3_Fahrtr_HL "Fahrtrichtungserkennung (im Audi D3/C6 und Colorado)";
CM_ SG_ 1184 BR3_Rad_kmh_HL "Low Byte 5, High Byte 6 (Auflösung 1,28 km/h)
Radgeschwindigkeit bezieht sich auf den 'Kombi 3` Reifenumfang
Konstanten:
V_INIT = 7FC4H (bzw. FF88H oder FF89H = 1111 1111 1000 100x B in 2-Byte-Schreibweise) (entspricht 327,08 km/h) (nicht Colorado, D1G";
CM_ SG_ 1184 BR3_Fahrtr_HR "Fahrtrichtungserkennung (im Audi D3/C6 und Colorado)";
CM_ SG_ 1184 BR3_Rad_kmh_HR "Low Byte 7, High Byte 8 (Auflösung 1,28 km/h)
Radgeschwindigkeit bezieht sich auf den 'Kombi 3` Reifenumfang
Konstanten:
V_INIT = 7FC4H (bzw. FF88H oder FF89H = 1111 1111 1000 100x B in 2-Byte-Schreibweise) (entspricht 327,08 km/h) (nicht Colorado, D1G";
CM_ SG_ 672 BR4_Vorgabe_Mi_ "Einheit Kupplungswert ist 0.
Vorgabe für das Kupplungsmoment vom Bremsen Steuergerät an die Allradkupplung, 'Kupplung schnell offen` heißt, daß der Befehl ohne Rampe sofort ausgeführt werden muß; der Arbeitsbereich geht von 0 (=80H) Nm (Kupplung gesteuer";
CM_ SG_ 672 BR4_Vorgabe_Mi "Einheit der Kupplungssteifigkeit ist 1 (Prozente) ; nicht PQ35/46
ABS-Vorgabewert für Kupplungssteifigkeit Mitte";
CM_ SG_ 672 BR4_Vorgabe_Max "Einheit Kupplungswert ist 2.
Max. Vorgabegrenzwert des Arbeitsbereiches der Kupplung durch das ESP (nur im PQ35 mit VAQ)
Vorgabewert für Kupplung Max";
CM_ SG_ 672 BR4_Vorgabe_Hi "Einheit der Kupplungssteifigkeit ist 1 (Prozente) ; nur im Colorado/Touareg GP
ABS-Vorgabewert für Kupplungssteifigkeit hinten";
CM_ SG_ 672 BR4_Vorgabe_Min "Einheit Kupplungswert ist 2.
Min. Vorgabegrenzwert des Arbeitsbereiches der Kupplung durch das ESP (nur im PQ35 mit VAQ)
Vorgabewert für Kupplung Min";
CM_ SG_ 672 BR4_Einheit "Die Einheit und der Wertebereich in Byte 1 und 2 wird mit diesem Bit gekennzeichnet (z.B. zur Verbaukontrolle nutzbar):
0: Nm (Haldex)
1: Normierung auf 0..100%
2: Nm (VAQ)
Einheit Kupplungswert (Bremse 4)";
CM_ SG_ 672 BR4_Schwelle "Byte 5 (BKV-Unterdruck) wird nur von speziellem HBV-Regler ausgegeben
Unterdruckschwellwert";
CM_ SG_ 672 BR4_Abschaltung_VL "Temperaturabschaltung ; nicht VW
EDS-Abschaltung VL";
CM_ SG_ 672 BR4_Abschaltung_VR "Temperaturabschaltung ; nicht VW
EDS-Abschaltung VR";
CM_ SG_ 672 BR4_Abschaltung_HL "Temperaturabschaltung ; nicht VW
EDS-Abschaltung HL";
CM_ SG_ 672 BR4_Abschaltung_HR "Temperaturabschaltung ; nicht VW
EDS-Abschaltung HR";
CM_ SG_ 672 BR4_Lampe_RKA "Warnlampe Reifen-Kontroll-Anzeige (Software im Bremsensteuergerät)
z.Zt. nur bei Contiteves PQ35
(zukünftig in Bremse_2)";
CM_ SG_ 672 BR4_Summer_RKA "Summer zur Reifen-Kontroll-Anzeige wird nach Setzen des Bits für eine Sekunde angesteuert
z. Zt. nur bei Contiteves PQ35
(zukünftig in Bremse_2)";
CM_ SG_ 672 BR4_Lampentrennung_gue "Bei gesetztem Bit sind die Informationen in mBremse_4, Byte 4, Bit 3,4,5 gültig. Das Kombiinstrument erkennt daran, ob die Bremse die Bits ESP-Off-Lampe und ESP/ASR-Funktionslampe unterstützt. Falls ungültig, verwendet das Kombi weiterhin das Lampenbit in";
CM_ SG_ 672 BR4_Lampe_ASRESP "Zustand der Fahrdynamikregelungslampe (ASR und/oder ESP)";
CM_ SG_ 672 BR4_ESP_Off "Bit zur Ansteuerung der separaten ESP-Off-Lampe im Kombi (Gesetzesforderung USA)";
CM_ SG_ 672 BR1_ASR_ESP "Kombi kann ggfs. die Lampe ansteuern
ASR/ESP-Steuergerät";
CM_ SG_ 672 BR4_RKA_Verbau "0x0: kein RKA verbaut bzw. Verbauzustand RKA in der Bremse unbekannt (RKA-Signale aus mBremse_2 werden im Kombi ausgegeben, aber keine Timeoutreaktion des Roadmap-Kombis bzgl. RKA)
0x1: RKA-Signale über mBremse_2 mit Timeout-Reaktion des Kombis auf mBrem";
CM_ SG_ 672 BR4_Unterdruck "der maximale Wert wird auf 1016 mbar begrenzt
Es ist der Initwert zu senden, wenn der Unterdruckschwellwert (Byte 3, Bit 3,2) auf 00 (kein Signal) steht, weil das ESP nicht über einen Unterdrucksensor verfügt.
(Nur für HBV-Regler PQ35 und TRW-HBV-Regler";
CM_ SG_ 672 BR4_Status_ESP "Statusmaschine (für VAQ im PQ35)";
CM_ SG_ 672 BR4_Zaehler "Überlaufender Botschaftszähler, zur Lebenderkennung";
CM_ SG_ 672 BR4_Checksum "Prüfsumme mit Endwert 0x0, Definition im CAN Lastenheft (HS-CAN V4.2a, LS-CAN V1.42)";
CM_ SG_ 1192 BR5_Giergeschw "Low Byte 1, High Byte 2
nicht offsetkorrigierte, gemessene Giergeschwindigkeit
tatsächliche Auflösung Bosch ESP: 0,27 Grad/s
Nur bei ABS-Systemen: Die Werte 3FFDH und 3FFEH zur Systemidentifikation kommen nur, wenn Gierrate ungültig (Byte 2, Bit 6) ges";
CM_ SG_ 1192 BR5_Sta_Gierrate "keine Filterung
ungültiger Wert kann z.B. aufgrund einer Unterspannung oder in der Initialisierungsphase ausgegeben werden
Gierrate ungültig";
CM_ SG_ 1192 BR5_Vorzeichen "Linkskurve positiv, Rechtskurve negativ!
Vorzeichen der Giergeschwindigkeit";
CM_ SG_ 1192 BR5_Bremsdruck "Realer Meßbereich 0...170 bar
Low Byte 1, High Byte 2, aktueller nicht offsetkorrigierter Bremsdruck im Hauptbremszylinder (ungefiltert)
Bremsdruck (Bremse 5)";
CM_ SG_ 1192 BR5_Stillstand "Fahrzeug steht (Algorithmus im Bremsensteuergerät)
im PQ35/46 alle 4 Radgeschwindigkeiten 0
Stillstand-Flag";
CM_ SG_ 1192 BR5_Druckgueltig "Bremsdruck ungültig";
CM_ SG_ 1192 BR5_Sta_Druck "Zur Plausibilisierung: Bremsdruck wird vom ESP aufgebaut (z.B. Vorladepumpe). Nachlauf muß vom Empfänger berücksichtigt werden.
Bei RB ESP 5.7, ESP 8, CT Mk60, MK25A XT und TRW EBC440 wird immer 0 ausgegeben, weil Drucksignal am Hauptbremszylinder nicht ";
CM_ SG_ 1192 BR5_Sign_Druck "Vorzeichen Bremsdruck";
CM_ SG_ 1192 ESP_Anforderung_EPB "ESP fordert von der EPB Öffnen bzw. Schliessen an. Notwendig wegen Autohold-Funktion.
Bedienung nur im VW411CS.";
CM_ SG_ 1192 ESP_Autohold_aktiv "Rückmeldung an EPB, dass Autohold aktiv ist.
Bedienung nur im VW411CS.";
CM_ SG_ 1192 ESP_Autohold_Standby "Rückmeldung an EPB, dass der Fahrer die Funktion Autohold mindestens einmal angefordert hat. Im Fall eines ESP-Ausfalles oder einer Übernahmeaufforderung erfolgt die EPB-Zuschaltung nur nach Setzen dieses Bits. Bit wird gesetzt nach Betätigung des Autohol";
CM_ SG_ 1192 BR5_Anhi_Sta "Bei gesetztem Fehler steht die Anfahrhilfe nicht zur Verfügung
(bisher nur Colorado/ Colorado GP/ T5/ T5GP/ RPU/ TTNF/ MK60EC/ RB ESP8.2i)";
CM_ SG_ 1192 BR5_Anhi_akt "Anfahrhilfe wird angesteuert
(bisher nur Colorado/ Colorado GP/ T5/ T5GP/ RPU/ TTNF/ MK60EC/ RB ESP8.2i)";
CM_ SG_ 1192 BR5_v_Ueberw "Funktion Geschwindigkeitsüberwachung ist aktuell verfügbar (Getriebe_1-Bits werden beachtet) (nur im Colorado)";
CM_ SG_ 1192 BR5_AnhStabAktiv "wenn Gespannstabilisierungs-Regelung zu einer Verzögerung führt, wird das Bit gesetzt: im Colorado zusätzlich zum Hardware-ausgang, in PQ35 / PQ46 ohne Hardware-Ausgang (nicht D1GP/BY61x)
Wird im T5GP und RPU umgesetzt für Bremslicht-Ansteuerung.
Gespan";
CM_ SG_ 1192 BR5_Notbremsung "Automatische Aktivierung des Warnblinkers und Bremsflächenvergrößerung bei Notbremsung. Funktion im ESP8 & ILM-Hinten ab Audi C6 erstmalig implementiert. (nicht PQ46) (nicht D1GP/BY61x)
Notbremsanzeige";
CM_ SG_ 1192 BR5_Fahrer_tritt_ZBR_Schw "Signal für AWV
0 = Fahrer übertritt aktuell gültige ZBR-Schwelle nicht
1 = Fahrer übertritt aktuell gültige ZBR-Schwelle";
CM_ SG_ 1192 BR5_AWV2_Bremsruck "Rückmeldung Bremse ans AWV: Von AWV2 angefordeter Bremsruck wird aktuell durchgeführt. (im AU716 und Touareg GP, PQ46 ab 45/08, MK60EC mit Einsatz LidarKamera, nicht D1GP/BY61x)";
CM_ SG_ 1192 BR5_AWV2_Fehler "Meldung an die Funktion AWV2 (z. Z. auf ACC-SG) wenn das ESP-SG einen Kommunikationsfehler oder unplausible Daten feststellt (Touareg GP und PQ46 ab 45/08, MK60EC mit Einsatz LidarKamera, nicht D1GP/BY61x)";
CM_ SG_ 1192 BR5_ZT_Rueckk_Umsetz "Signal für AWV
Das Signal dient als Rückmeldung zum ACC, dass eine angeforderte Zielbremsung/Teilbremsung durchgeführt wird. Die positive Rückmeldung löst u.a. eine entsprechende Fahrerinformation im Kombiinstrument aus";
CM_ SG_ 1192 BR5_ANB_CM_Rueckk_Umsetz "Signal für AWV
Das Signal dient als Rückmeldung zum ACC, dass eine angeforderte ANB-CM durchgeführt wird. Die positive Rückmeldung löst u.a. eine entsprechende Fahrerinformation im Kombiinstrument aus";
CM_ SG_ 1192 BR5_ECD_Lampe "Bremslichtansteuerung durch ECD-Funktion (nicht PQ35/46)";
CM_ SG_ 1192 BR5_Zaehler "Überlaufender Botschaftszähler, zur Lebenderkennung";
CM_ SG_ 1192 BR5_Checksumme "Prüfsumme mit Endwert 0x0, Definition im CAN Lastenheft (HS-CAN V4.2a, LS-CAN V1.42)";
CM_ SG_ 428 BR8_Checksumme "Prüfsumme mit Endwert 0x0, Definition im CAN Lastenheft (HS-CAN V4.2a, LS-CAN V1.42)";
CM_ SG_ 428 BR8_Zaehler "Überlaufender Botschaftszähler, zur Lebenderkennung";
CM_ SG_ 428 BR8_Sta_ACC_Anf "gültige ACC-Anforderung zur Verzögerungsrege-lung ECD / Bremsenregelung wird ausgeführt: Druckaufbau über Standby hinaus (im PQ46 aus Motor_Bremse) (nur bei Audi auch GRA+-Anforderung möglich)
Status Bremse ACC-Anforderung";
CM_ SG_ 428 BR8_Verz_EPB_akt "Bei gesetzten Bit wird Verzögerungswunsch von EPB umgesetzt.
Verzögerung durch EPB aktiviert";
CM_ SG_ 428 BR8_Sta_Br_temp "ECD-Bremsscheibentemperaturmodell ;Reaktion durch ACC, GRA od. EPB
Status Bremse Bremstemperatur";
CM_ SG_ 428 BR8_Sta_Br_Druck "bei gesetztem Bit liegt p > ca. 2 bar an, hervorgerufen durch Fahrer, ASR, FZR, ECD, Bremsenregler...bei Abfall des Bits ist p < X bar, bei aktivem ECD-Eingriff Ende des Eingriffs (für den PQ46 noch in Klärung)
Status Bremsdruck";
CM_ SG_ 428 BR8_Istbeschl "Fahrzeugbeschleunigung als Referenzwert für ACC (abgeleitet aus der Geschwindigkeit, die in Bremse 1 übertragen wird) (nur für Überwachungszwecke)";
CM_ SG_ 428 BR8_Sta_HW_BLS "Endstufe Bremslichtschalter-Ausgang defekt
Status Hardware BLS-Ausgang";
CM_ SG_ 428 BR8_QB_LBeschl "Definition nach CAN-Lastenheft
Qualifizierungsbit Längsbeschleunigung";
CM_ SG_ 428 BR8_ESC_Mode "Anzeige 'ESC Mode' (ESP-Modus) nur im MY10 Bentley-Kombi
(war 'AWV1 Basisparametersatz HBA' Rückmeldung des aktuell codierten Parametersatzes ans ACC nur Audi C6/AU716)";
CM_ SG_ 428 BR8_aktBrSyst "Bremssystem kann aufgrund einer externen Anforderung (z.B. Motor_Bremse) aktiv bremsen
Aktives Bremssystem";
CM_ SG_ 428 BR8_Fa_bremst "Fahrer bremst bzw. bremst stärker als aktives Bremssystem (nur benötigt für aktive Bremssysteme)
Nur im Porsche Cayenne wird das Bit auch bei Gespannstabilisierungseingriff gesetzt.";
CM_ SG_ 428 BR8_StaBrSyst "Aktives Bremssystem setzt Anforderungen von externem System (Andocken/ Standby oder Verzögerung) um
Status aktives Bremssystem";
CM_ SG_ 428 BR8_Laengsbeschl "Längsbeschleunigung (nur im Colorado und PQ35 ausstattungsabhängig (z.B. Allrad)): Sensorwert, im PQ46 Rohwert, im PQ35 kein Rohwert";
CM_ SG_ 428 BR8_Sta_ADR_BR "Rueckmeldung zum ACC bezueglich Pruefung der Checksumme, des Botschaftszaehlers und des langen Timeout der ACC-1 Botschaft. Wird gesetzt bei ACC-Verzoegerungsanforderungen groesser einer applizierbaren Schwelle. (bei Audi GRA+ Rückmeldung zum Motor) (bei ";
CM_ SG_ 428 BR8_Quattro "Information darüber, ob das Fahrzeug Front- oder Allradantrieb (Quattro) hat (nicht bedient im PQ35/46)";
CM_ SG_ 428 BR8_Sta_VerzReg "ESP kann die Verzögerungsregelung / Bremsenregelung nicht ausführen
Status Verzögerungsregler";
CM_ SG_ 428 BR8_Sta_BLS "ESP hat Fehler in der Erfassung des Bremslichtschalters erkannt
Status BLS";
CM_ SG_ 428 BR8_Verz_EPB "Bei gesetzten Bit ist der Verzögerungsregler für EPB verfügbar.";
CM_ SG_ 428 BR8_Check_EPB "Bei nicht gesetztem Bit wird die EPB Botschaft nicht empfangen oder Inhalt ist unplausibel (Checksumme, Botschaftszähler)
EPB Botschaft plausibel";
CM_ SG_ 174 BR9_Checksumme "Prüfsumme mit Endwert 0x0, Definition im CAN Lastenheft (HS-CAN V4.2a, LS-CAN V1.42)";
CM_ SG_ 174 BR9_Sta_ESP_PLA "Zustand der Statusmaschine der Bremse für die korrespondierenden Statusmaschine in dem PLA-SG.";
CM_ SG_ 174 BR9_Zaehler "Freilaufender Botschaftszähler, dient als Quelle des Botschaftsspiegels in Lenkhilfe_3 Botschaft";
CM_ SG_ 174 BR9_LMOffset "reale Auflösung 0,01 Nm
Anforderung Lenkmomenten-Offset";
CM_ SG_ 174 BR9_LMOffSign "Vorzeichen Anforderung Lenkmomenten-Offset";
CM_ SG_ 174 BR9_LWOffset "positiver Lenkradwinkel: nach links
negativer Lenkradwinkel: nach rechts
Anforderung Lenkwinkel-Offset";
CM_ SG_ 174 BR9_LWOffSign "Vorzeichen Anforderung Lenkwinkel-Offset";
CM_ SG_ 174 BR9_Sta_DSR "0 DSR deaktiviert
1 DSR Anforderung nicht ausführbar (ESP Fehlerstatus)
2 Kommunikation zum ESP-SG gestört
3 ESP bzgl. DSR funktionsbereit
4 offen
5 externer Momenteneingriff angefordert
6 externer Lenkwinkeleingriff angefordert
7 externer Momenten";
CM_ SG_ 174 BR9_PLA_Abbruch "Wenn der Bremseingriff abgebrochen wurde, wird in diesem Signal der Grund des Abbruchs dargestellt. Dies ist nur gültig, wenn der Status BR9_Sta_ESP_PLA = '10' ist.";
CM_ SG_ 1524 BCN_Checksumme "Prüfsumme mit Endwert 0x0, Definition im CAN Lastenheft (HS-CAN V4.2a, LS-CAN V1.42)";
CM_ SG_ 1524 BCN_BremsenVar "Bremsenvariante
00H keine Variante hinterlegt";
CM_ SG_ 1524 BCN_AntriebsVar "Ausgegeben wird die Antriebsvariante zur Codierplausibilisierung im ESP-Steuergerät";
CM_ BO_ 1091 "alter Name mRDK_1_D3";
CM_ SG_ 1091 RKA_Prio1_Warnung "1 = Prio 1 Warnung
Prio 1 Warnung fuer Kombi";
CM_ SG_ 1091 RKA_Prio2_Warnung "1 = Prio 2 Warnung
Prio 2 Warnung fuer Kombi";
CM_ SG_ 1091 RKA_Warnungen "Warnmeldungen fuers Kombi";
CM_ SG_ 1091 RKA_FMVSS_138_Warnung "1 = Warnlampe FMVSS 138";
CM_ SG_ 1091 RDK_Status "RDK Status Ein/Aus
0 = System aus
1 = System ein";
CM_ SG_ 1091 RKA_Ack_IstZu_Solldruecke "Bestaetigung fuer MMI/Kombi, dass neue Solldruecke ueberwacht werden
Die aktuellen Istdruecke wurden zu neuen Solldruecken uebernommen";
CM_ SG_ 1091 RDK_neue_Solldruecke "0 = keine neuen Solldruecke
1 = es liegen neue Solldruecke vor
RDK hat neue Solldruecke erkannt";
CM_ SG_ 1091 RKA_Menue "Für den Fall des Verbaus eines RKA-Tasters am ESP kann über dieses Signal das Menue deaktiviert werden.
Z. Zt. unterstützt in TRW-ESP für VW47x und VW416GP";
CM_ SG_ 1091 RKA_KD_Fehler "1 = mindestens ein Kundendienstfehler im Steuergeraet vorhanden";
CM_ SG_ 1091 RDK_Sensor_Multiplex "0x00 = vl
0x01 = vr
0x02 = hl
0x03 = hr
0x04 = RR
Multiplexinformation fuer die Auswahl eines Reifens";
CM_ SG_ 1091 RDK_xx_Status_Sensor "0 = Sensorwert ungueltig
1 = Sensorwert gueltig (xx = vl, vr, hl, hr, RR)
Status des einzelnen Sensors in Abhaengigkeit von Byte 3, Bit 0...2";
CM_ SG_ 1091 RDK_xx_Color "0 = gruen
1 = gelb
2 = rot (xx = vl, vr, hl, hr, RR)
Farbdarstellung der Reifen im Kombi in Abhaengigkeit von Byte 3, Bit 0...2";
CM_ SG_ 1091 RDK_xx_Ist_Temp "Reifentemperatur_xx (xx = vl, vr, hl, hr)
Isttemperatur des Reifens in Abhaengigkeit von Byte 3, Bit 0...2";
CM_ SG_ 1091 RDK_xx_Ist_Druck "Istreifendruck_xx (xx = vl, vr, hl, hr)
Istdruck des Reifens in Abhaengigkeit von Byte 3, Bit 0...2";
CM_ SG_ 1091 RDK_xx_Soll_Druck "Sollreifendruck_xx (xx = vl, vr, hl, hr, RR)
Solldruck des Reifens in Abhaengigkeit von Byte 3, Bit 0...2";
CM_ SG_ 1392 BSL_ZAS_Kl_S "1 = S-Kontakt geschlossen, Schluessel steckt
S-Kontakt (Schluessel steckt)";
CM_ SG_ 1392 BSL_ZAS_Kl_15 "1 = Klemme 15 Innenraum ist eingeschaltet";
CM_ SG_ 1392 BSL_ZAS_Kl_X "1 = Klemme X aktiv
Klemme X öffnet beim Motorstart und ist invers zu Klemme 50.
Bei Fahrzeugen mit Start/Stop-Systemen wird die Klemme X nur beim Erststart ausgeschaltet.";
CM_ SG_ 1392 BSL_ZAS_Kl_50 "1 = Klemme 50 ist eingeschaltet
Klemme 50 geschaltet (Starten)";
CM_ SG_ 1392 BSL_Parklicht "1 = Klemme P ein (Parklicht)";
CM_ SG_ 1392 BSL_LL_Anheb2 "1 = Anforderung der Drehzahlanhebung 2 Stufe
Drehzahlanhebung 2. Stufe (s. BSG_Last)";
CM_ SG_ 1392 BSL_Kl_15_Motor "1 = Klemme 15 Motorraum ist eingeschaltet (Klemme 14)";
CM_ SG_ 1392 BSL_Kl_L "1 = mangelnde Batterieladung
Ladekontrollampe(Klemme L)";
CM_ SG_ 1392 BSL_LL_Anheb "1 = Anforderung der Drehzahlanhebung (bei nur einer Stufe) oder Anhebung auf 1. Stufe (s. Antrieb BSG_Last)";
CM_ SG_ 1392 BSL_Sta_UBat "Zeigt den Zustand der Bordnetzbatterie an (00=i.O., 01=kritisch, 10=entladen, 11=Fehler)";
CM_ SG_ 1392 BSL_Sta_StBat "Zeigt den Zustand der Starterbatterie an (00=i.O., 01=kritisch, 10=entladen, 11=Fehler)";
CM_ SG_ 1392 BSL_Fehlereintr "1 = mindestens ein Fehler ist im Kundendienstfehlerspeicher eingetragen";
CM_ SG_ 1392 BSL_Sta_LWR "1 = Fehler in der Leuchtweitenregulierung
0 = i.O.";
CM_ SG_ 1392 BSL_Motor_Haube "1 = Haube geoeffnet
0 = Haube geschlossen";
CM_ SG_ 1392 BSL_UBat "FF = Fehler
Bordnetz_Batterie_Spannung (s. BSG_Last)";
CM_ SG_ 1392 BSL_Hecksch "1 = Abschalten der Heckscheibenheizung ist gefordert
Heizbare_Heckscheibe abschalten (s. BSG_Last)";
CM_ SG_ 1392 BSL_Frontsch "1 = Abschalten der Frontscheibenheizung ist gefordert
Heizbare_Frontscheibe abschalten (s. BSG_Last)";
CM_ SG_ 1392 BSL_Aussensp "1 = Abschalten der Aussenspiegelheizung ist gefordert
Heizbare_Aussenspiegel abschalten (s. BSG_Last)";
CM_ SG_ 1392 BSL_Sitzheiz "1 = Abschalten der Sitzheizung ist gefordert
Heizbare_Sitze abschalten (s. BSG_Last)";
CM_ SG_ 1392 BSL_Lenkradheiz "1 = Abschalten der Lenkradheizung ist gefordert
Lenkradheizung abschalten (s. BSG_Last)";
CM_ SG_ 1392 BSL_Wasserheiz "1 = Abschalten der Wischwasserheizung ist gefordert
Wischwasserheizung abschalten (s. BSG_Last)";
CM_ SG_ 1392 BSL_Sitzbelueft "1 = Abschalten der Sitzbelueftung ist gefordert";
CM_ SG_ 1392 BSL_Clima "1 = Reduzierung der Klimaleistung ist gefordert
Klimaanlage abschalt. / reduzieren (s. BSG_Last)";
CM_ SG_ 1392 BSL_BSG_2_alt "mBSG_2 Botschaft nicht empfangen (1 Sekunde)
BSG_2 veraltet";
CM_ SG_ 1392 BSL_BSG_3_alt "mBSG_3 Botschaft nicht empfangen (400 msec)
BSG_3 veraltet";
CM_ SG_ 1392 BSL_Kuehlerlueft "1 = Kuehlerluefer einschalten zur Glaettung der Bordnetzspannung bei defekter Batterie
Kuehlerluefter einschalten (s. BSG_Last)";
CM_ SG_ 1392 BSL_Ab_Batterie "1 = Batterie ab erkannt
0 = Batterie am Bordnetz
Batterie ab Erkennung";
CM_ SG_ 1392 BSL_Weckursache_ACAN "00 = kein_EKP_Vorlauf
01 = reserviert
10 = Weckursache Standheizung
11 = Weckursache Türkontakt
abhaengig von der genannten Weckursache wird eine Kraftstoffpumpen-Vorfoerderung angesteuert.
Wake-Up-Anforderung durch das BSG";
CM_ SG_ 1392 BSL_Wake_Up_ACAN "0 = kein Wake-Up (z.B. KL15-Normalbetrieb)
1 = Anforderung zum Wecken des Antriebs-CAN
Das BSG lernt anhand von MO7_Mot_weckfaehig, ob es das Bit setzen muss.
Wake-Up des Antriebs-CAN";
CM_ SG_ 1392 BSL_Starterlaubnis "Bit wird gesetzt, wenn der Start vom Bordnetz-SG bei folgenden Begebenheiten erlaubt wird:
- PN-verriegelt, - Interlock (Kupplung bei Handschalter-Fzg.) betaetigt (Kupplungschalter tief)
Als Reaktion auf deises Bit zeigt das Kessy Texte im Kombi an.
St";
CM_ BO_ 1528 "CAN-Antrieb";
CM_ SG_ 1528 Module_ID_5 "APS";
CM_ SG_ 1528 Data_Byte_1_5 "Festlegung der Datenbytes siehe CAN Data Exchange Function Datenfestlegung
Datenbyte 1";
CM_ SG_ 1528 Data_Byte_2_5 "Festlegung der Datenbytes siehe CAN Data Exchange Function Datenfestlegung
Datenbyte 2";
CM_ SG_ 1528 Data_Byte_3_5 "Festlegung der Datenbytes siehe CAN Data Exchange Function Datenfestlegung
Datenbyte 3";
CM_ SG_ 1528 Data_Byte_4_5 "Festlegung der Datenbytes siehe CAN Data Exchange Function Datenfestlegung
Datenbyte 4";
CM_ SG_ 1528 Data_Byte_5_5 "Festlegung der Datenbytes siehe CAN Data Exchange Function Datenfestlegung
Datenbyte 5";
CM_ BO_ 1530 "CAN-Antrieb";
CM_ SG_ 1530 Module_ID_19 "APS";
CM_ SG_ 1530 Data_Byte_1_19 "Festlegung der Datenbytes siehe CAN Data Exchange Function Datenfestlegung
Datenbyte 1";
CM_ SG_ 1530 Data_Byte_2_19 "Festlegung der Datenbytes siehe CAN Data Exchange Function Datenfestlegung
Datenbyte 2";
CM_ SG_ 1530 Data_Byte_3_19 "Festlegung der Datenbytes siehe CAN Data Exchange Function Datenfestlegung
Datenbyte 3";
CM_ SG_ 1530 Data_Byte_4_19 "Festlegung der Datenbytes siehe CAN Data Exchange Function Datenfestlegung
Datenbyte 4";
CM_ SG_ 1530 Data_Byte_5_19 "Festlegung der Datenbytes siehe CAN Data Exchange Function Datenfestlegung
Datenbyte 5";
CM_ BO_ 1504 "100ms in PQ35/46 CAN-Antrieb";
CM_ SG_ 1504 CL1_LL_Dz "1 = Drehzahlanhebung, Forderung an den Motor bei zu geringer Kälte- / Heizleistung
Signal fuer Drehzahlanhebung";
CM_ SG_ 1504 CL1_Fa_Zuheiz "1 = Zuheizerfreigabe
(im Hybrid Anforderung auf Lauf des VM zur Erhöhung der Abwärme für Heizleistung)
Fahrerwunsch Zuheizer";
CM_ SG_ 1504 CL1_Hecksch "1 = Heckscheibenheizung ein
Hzg Heckscheibe angesteuert (Power)";
CM_ SG_ 1504 CL1_Frontsch "1 = Frontscheibenheizung ein
Hzg Frontscheibe angesteuert (Power)";
CM_ SG_ 1504 CL1_Kompressor "1 = Kompressor ein, Zustand incl. 140ms Vorsteuerung, Info an das MSG: Kompressor EIN, PQ34_lang: Anforderung an das MSG: Kompressor einschalten";
CM_ SG_ 1504 CL1_Heizleist "1, wenn beide Temperaturklappen auf Kaltanschlag stehen, an MSG um hohe Kühlmitteltemp. zu fahren
Keine Heizleistung gewuenscht";
CM_ SG_ 1504 CL1_Sta_Moment "1 = veraltet; Ermittlung des Moments nicht moelich (z.B. keine Drehzahl, kein Kaeltemitteldruck)'
Kompressormoment veraltet";
CM_ SG_ 1504 CL1_Sta_Druck "1 = veraltet; bei Klemme 15 aus
Kaeltemitteldruck veraltet";
CM_ SG_ 1504 CL1_Aussentemp "FF = Fehler
Ansauglufttemperatur fuer die Climaanlage
im PQ25 kein Temperatursensor im Wasserkasten
Aussentemperatur ungefiltert Wasserkasten";
CM_ SG_ 1504 CL1_Druck "FF = Fehler
Kaeltemitteldruck";
CM_ SG_ 1504 CL1_Kompr_Last "Verlustmoment der Klimaanlage in Nm
Lastinfo: Kompressorzustand";
CM_ SG_ 1504 CL1_Gebl_last "Lastinfo: Geblaeseansteuerung";
CM_ SG_ 1504 CL1_Luefter "Ansteuerung des Kuehlerluefters in Prozent";
CM_ SG_ 1504 CL1_Einheit_Temp "1 = Klimaanlage zeigt die Temperatur in Fahrenheit an, Temp auf dem Bus in °C !!";
CM_ SG_ 1504 CL1_AC_Schalter "1 = AC-Schalter gedrueckt
Abbildung des AC-Schalters";
CM_ SG_ 1504 CL1_WAPU_Zuschaltung "1 = Wasserpumpe ist nicht zugeschaltet
Ein/ Ausschalten der Wasserpumpe zwecks CO2 Einsparung";
CM_ SG_ 1504 CL1_Restwaerme "1 = Restwaermefunktion ist aktiviert, Statusinformation, d.h. Geblaeselast ist vorhanden";
CM_ SG_ 1504 CL1_PTC_Hzg "0 = PTC Heizung aus
1 = Leistung PTC Heizung <= 25%
2 = Leistung PTC Heizung <= 50%
3 = Leistung PTC Heizung <= 75%
4 = Leistung PTC Heizung <= 100%
Status der Klima PTC Heizung";
CM_ SG_ 1504 CL1_Fehlereintr "1 = mindestens 1 Kundendienstfehler ist im Fehlerspeicher eingetragen";
CM_ SG_ 1504 KL_Thermomanagement "Stufen des Thermomanagements";
CM_ SG_ 1432 DA1_Daempferreg "Bei Statusänderung wird der Soll-Zustand ausgegeben. Der Status beschreibt einen Parametersatz: Temporäre Änderungen der Dämpfereinstellungen werden hier nicht abgebildet
(nicht Audi D3)
Status Dämpferregelung";
CM_ SG_ 1432 DA1_Warnlampe "Dient der Anzeige von Warnungen im Kombiinstrument
(nicht Colorado)
(nicht Audi D3)
Gelbe Warnlampe";
CM_ SG_ 1432 DA1_Taster "Nach Betätigung des Tasters wird das Fahrwerk-Menü im ZAB (D1) aktiviert
(nicht Audi D3)
Charisma-Taster (PQ35/46)";
CM_ SG_ 1432 DA1_Systemstatus "Bit wird gesetzt, wenn interne Funktionsprüfung i.O. und System generell funktionsfähig ist.
(nicht Audi D3)";
CM_ SG_ 1432 DA1_Fehlereintr "im Fehlerspeicher der Dämpferregelung gibt es einen aktuellen (statischen oder sporadischen) Kundendienst-Fehlerspeichereintrag";
CM_ SG_ 1432 DA1_Textbits "Die Textbits werden verwendet, um im Kombi Texte oder Bilder für die Dämpferregelung darzustellen
(nicht Colorado) (nicht Audi D3)
Text 1: 'CDC Sport 1'
Text 2: 'CDC Sport 2'
Text 3: 'CDC Basis'
Text 4: 'CDC Komfort'";
CM_ SG_ 1432 DA1_Zaehler "Freilaufender Botschaftszähler";
CM_ SG_ 1432 DA1_ESP_Zwang "(nicht Dämpfer PQ35/46)
ESP-Zwangszuschaltung";
CM_ SG_ 1432 DA1_LampPruef "Aufprüfbit Warnlampe";
CM_ SG_ 1432 DA1_Charisma "Gateway erkennt, ob im Dämpfer Charisma aktiv ist und liest ggf. Tasterzustand (Byte 1, Bit 4) ein";
CM_ SG_ 1432 DA1_Checksumme "Prüfsumme mit Endwert 0x0, Definition im CAN Lastenheft (HS-CAN V4.2a, LS-CAN V1.42)";
CM_ BO_ 2000 "CAN-Antrieb";
CM_ SG_ 2000 DI1_VerlernZaehl "FFh = Fehler, ungueltiger Zaehlerstand bzw. kein gueltiger Fahrzyklus
Binaer wrap around";
CM_ SG_ 2000 DI1_km_Stand "Kilometerstand";
CM_ SG_ 2000 DI1_Jahr "0 für Datum unbekannt (z.B. keine Funkuhr)
(bei relativem Datum ist auch der Wert 0 gültig siehe Spezifikation_Tageszähler_Kombi_01.doc)";
CM_ SG_ 2000 DI1_Monat "0 = Monat unbekannt
Dh = ungueltig
Eh = relatives Datum siehe Spezifikation_Tageszähler_Kombi_01.doc
Fh = Keine Funkuhrinformation vorhanden und 12 h Anzeige (Monat, Tag, Jahr fehlen)";
CM_ SG_ 2000 DI1_Tag "0 für Datum unbekannt (z.B. keine Funkuhr)
(bei relativem Datum ist auch der Wert 0 gültig siehe Spezifikation_Tageszähler_Kombi_01.doc)";
CM_ SG_ 2000 DI1_Stunde "18h - 1Fh ungueltig";
CM_ SG_ 2000 DI1_Minute "3Ch - 3Fh ungueltig";
CM_ SG_ 2000 DI1_Sekunde "3Ch - 3Fh ungueltig";
CM_ SG_ 2000 DI1_KM_Stand_alt "0 = Kilometerstand aktuell (vor < als 2 Sec vom Kombi empfangen)
1 = Kilometerstand veraltet";
CM_ SG_ 2000 DI1_Zeit_alt "0 = Zeit aktuell vom Kombi empfangen (< 2 sec)
1 = Zeit veraltet";
CM_ SG_ 1562 Ladestecker_gesteckt "Signalisiert ein gestecktes Ladekabel.";
CM_ SG_ 1562 Ladevorgang_aktiv "Signalisiert einen aktiven Ladevorgang. Ladegeräte und DC/DC-Wandler aktiv.";
CM_ SG_ 1562 HV_Bordnetz_aktiv "Signalisiert ein aktives Hochvoltbordnetz. HV-Schütze geschlossen. Im Fehlerfall wird das Bit nicht gesetzt.(Klemmende Schütze)";
CM_ SG_ 1562 HV_Bordnetz_A_Status "Status Aktivierung HV_Bordnetz. Abbruchursache HV-Bordnetz bei Kl.15 aus.
0 = Kl.15 aus. HV-Bordnetz kann aktiviert werden
1 = Kl.15 ein. Aktivierung nur für Sofortladung oder bei Fahrbereitschaft
2 = Keine Aktivierung: Schlüssel erkannt
3 = Keine Akt";
CM_ SG_ 1562 HV_PTC_LeistRed "Anforderung an die Klimasteuerung, die Leistungsaufnahme des HV-PTC bei schlechtem SOC und in bestimmten Fahrsituationen zu begrenzen.
(Das bereits bestehende Signal 'Klimakompressor aus' Motor5, Byte2, Bit5 als stets umzusetzende Anforderung bleib)";
CM_ SG_ 1562 HV_PTC_aus "MSG schaltet HV-PTC aus";
CM_ SG_ 1562 Ladestecker_verr_Status "Signalisiert einen verriegelten Ladestecker";
CM_ SG_ 1576 Energieinhalt_HV_Batt "Effektiv nutzbarer Energieinhalt der Hochvoltbatterie";
CM_ SG_ 1576 Ladezustand_HV_Batterie "Aktueller Ladezustand der HV-Batterie in %. (SOC)";
CM_ SG_ 1576 Stromnetz_vorhanden "Signalisiert, ob eine Aktivierung des Ladegeräts möglich ist. Das Fahrzeug muss hierzu über den Ladestecker mit dem Stromnetz verbunden sein und Spannung am Ladestecker anliegen.";
CM_ SG_ 1576 BMS_Temperierung_Anf "Temperierungsbedarf der HV-Batterie
";
BA_DEF_ BO_  "GenMsgAutoGenDsp" ENUM  "No","Yes";
BA_DEF_ BO_  "GenMsgAutoGenSnd" ENUM  "No","Yes";
BA_DEF_ BO_  "GenMsgCycleTime" INT 0 65535;
BA_DEF_ BO_  "GenMsgCycleTimeFast" INT 0 65535;
BA_DEF_ BO_  "GenMsgDelayTime" INT 0 100000;
BA_DEF_ BO_  "GenMsgILSupport" ENUM  "No","Yes";
BA_DEF_ BO_  "GenMsgSendType" ENUM  "Cyclic","not_used","not_used","not_used","not_used","not_used","not_used","IfActive","NoMsgSendType";
BA_DEF_ BO_  "GenMsgStartDelayTime" INT 0 100000;
BA_DEF_ BO_  "NmMessage" ENUM  "No","Yes";
BA_DEF_ BO_  "NmhMessage" ENUM  "No","Yes";
BA_DEF_ BO_  "VAGTP20_API" HEX 0 255;
BA_DEF_ BO_  "VAGTP20_DynConnection" ENUM  "No","Yes";
BA_DEF_ BO_  "VAGTP20_DynSetup" ENUM  "No","Yes";
BA_DEF_ BO_  "VAGTP20_StatConnection" ENUM  "No","Yes";
BA_DEF_ BO_  "Timeoutzeit" INT 0 1000000;
BA_DEF_ BO_  "DiagRequest" ENUM  "No","Yes";
BA_DEF_ BO_  "DiagResponse" ENUM  "No","Yes";
BA_DEF_ BO_  "DiagState" ENUM  "No","Yes";
BA_DEF_ BO_  "GenMsgChkConstant" HEX 0 4095;
BA_DEF_ SG_  "GenSigAutoGenDsp" ENUM  "No","Yes";
BA_DEF_ SG_  "GenSigAutoGenSnd" ENUM  "No","Yes";
BA_DEF_ SG_  "GenSigEnvVarType" ENUM  "int","float","undef";
BA_DEF_ SG_  "GenSigInactiveValue" INT -2147483648 2147483647;
BA_DEF_ SG_  "GenSigSendType" ENUM  "Cyclic","OnWrite","OnWriteWithRepetition","OnChange","OnChangeWithRepetition","IfActive","IfActiveWithRepetition","NoSigSendType","OnChangeAndIfActive","OnChangeAndIfActiveWithRepetition";
BA_DEF_ SG_  "GenSigStartValue" INT -2147483648 2147483647;
BA_DEF_ SG_  "NWM-WakeupAllowed" ENUM  "No","Yes";
BA_DEF_ SG_  "GenSigFuncType" ENUM  "NoFunction","MsgCounter","CRC-8","XOR","XOR-2","DatedBit","SW-Kl15","CHK","Constant","Protocol";
BA_DEF_ SG_  "GenSigSwitchedByIgnition" ENUM  "No","Yes";
BA_DEF_ SG_  "Fehlerwert" HEX 0 2147483647;
BA_DEF_ SG_  "GenSigMissingSourceValue" HEX 0 2147483647;
BA_DEF_REL_ BU_SG_REL_  "GenSigTimeoutTime" INT 0 65535;
BA_DEF_DEF_REL_ "GenSigTimeoutTime" 0;
BA_DEF_DEF_  "GenMsgAutoGenDsp" "Yes";
BA_DEF_DEF_  "GenMsgAutoGenSnd" "Yes";
BA_DEF_DEF_  "GenMsgCycleTime" 0;
BA_DEF_DEF_  "GenMsgCycleTimeFast" 0;
BA_DEF_DEF_  "GenMsgDelayTime" 0;
BA_DEF_DEF_  "GenMsgILSupport" "No";
BA_DEF_DEF_  "GenMsgSendType" "NoMsgSendType";
BA_DEF_DEF_  "GenMsgStartDelayTime" 0;
BA_DEF_DEF_  "NmMessage" "No";
BA_DEF_DEF_  "NmhMessage" "No";
BA_DEF_DEF_  "VAGTP20_API" 0;
BA_DEF_DEF_  "VAGTP20_DynConnection" "No";
BA_DEF_DEF_  "VAGTP20_DynSetup" "No";
BA_DEF_DEF_  "VAGTP20_StatConnection" "No";
BA_DEF_DEF_  "Timeoutzeit" 0;
BA_DEF_DEF_  "DiagRequest" "No";
BA_DEF_DEF_  "DiagResponse" "No";
BA_DEF_DEF_  "DiagState" "No";
BA_DEF_DEF_  "GenMsgChkConstant" 0;
BA_DEF_DEF_  "GenSigAutoGenDsp" "No";
BA_DEF_DEF_  "GenSigAutoGenSnd" "No";
BA_DEF_DEF_  "GenSigEnvVarType" "undef";
BA_DEF_DEF_  "GenSigInactiveValue" 0;
BA_DEF_DEF_  "GenSigSendType" "NoSigSendType";
BA_DEF_DEF_  "GenSigStartValue" 0;
BA_DEF_DEF_  "NWM-WakeupAllowed" "No";
BA_DEF_DEF_  "GenSigFuncType" "NoFunction";
BA_DEF_DEF_  "GenSigSwitchedByIgnition" "Yes";
BA_DEF_DEF_  "Fehlerwert" 0;
BA_DEF_DEF_  "GenSigMissingSourceValue" 0;
BA_ "GenMsgSendType" BO_ 1463 0;
BA_ "GenMsgILSupport" BO_ 1463 1;
BA_ "GenMsgDelayTime" BO_ 1463 20;
BA_ "GenMsgCycleTime" BO_ 1463 100;
BA_ "GenMsgSendType" BO_ 1440 0;
BA_ "GenMsgILSupport" BO_ 1440 1;
BA_ "GenMsgCycleTime" BO_ 1440 20;
BA_ "GenMsgSendType" BO_ 1184 0;
BA_ "GenMsgILSupport" BO_ 1184 1;
BA_ "GenMsgCycleTime" BO_ 1184 10;
BA_ "GenMsgSendType" BO_ 672 0;
BA_ "GenMsgILSupport" BO_ 672 1;
BA_ "GenMsgCycleTime" BO_ 672 10;
BA_ "GenMsgSendType" BO_ 1192 0;
BA_ "GenMsgILSupport" BO_ 1192 1;
BA_ "GenMsgCycleTime" BO_ 1192 20;
BA_ "GenMsgSendType" BO_ 428 0;
BA_ "GenMsgILSupport" BO_ 428 1;
BA_ "GenMsgCycleTime" BO_ 428 20;
BA_ "GenMsgSendType" BO_ 174 0;
BA_ "GenMsgILSupport" BO_ 174 1;
BA_ "GenMsgCycleTime" BO_ 174 10;
BA_ "GenMsgSendType" BO_ 1524 0;
BA_ "GenMsgILSupport" BO_ 1524 1;
BA_ "GenMsgCycleTime" BO_ 1524 1000;
BA_ "GenMsgSendType" BO_ 1091 0;
BA_ "GenMsgILSupport" BO_ 1091 1;
BA_ "GenMsgDelayTime" BO_ 1091 100;
BA_ "GenMsgCycleTime" BO_ 1091 500;
BA_ "GenMsgSendType" BO_ 1392 0;
BA_ "GenMsgILSupport" BO_ 1392 1;
BA_ "GenMsgDelayTime" BO_ 1392 10;
BA_ "GenMsgCycleTime" BO_ 1392 100;
BA_ "GenMsgDelayTime" BO_ 1528 50;
BA_ "GenMsgCycleTimeFast" BO_ 1528 50;
BA_ "GenMsgCycleTime" BO_ 1528 50;
BA_ "GenMsgDelayTime" BO_ 1530 50;
BA_ "GenMsgCycleTimeFast" BO_ 1530 50;
BA_ "GenMsgCycleTime" BO_ 1530 50;
BA_ "GenMsgSendType" BO_ 1504 0;
BA_ "GenMsgILSupport" BO_ 1504 1;
BA_ "GenMsgDelayTime" BO_ 1504 10;
BA_ "GenMsgCycleTime" BO_ 1504 100;
BA_ "GenMsgSendType" BO_ 1432 0;
BA_ "GenMsgILSupport" BO_ 1432 1;
BA_ "GenMsgCycleTimeFast" BO_ 1432 30;
BA_ "GenMsgCycleTime" BO_ 1432 100;
BA_ "GenMsgSendType" BO_ 2000 0;
BA_ "GenMsgILSupport" BO_ 2000 1;
BA_ "GenMsgCycleTime" BO_ 2000 1000;
BA_ "GenMsgSendType" BO_ 1562 0;
BA_ "GenMsgILSupport" BO_ 1562 1;
BA_ "GenMsgDelayTime" BO_ 1562 50;
BA_ "GenMsgCycleTime" BO_ 1562 500;
BA_ "GenMsgSendType" BO_ 1576 0;
BA_ "GenMsgCycleTime" BO_ 1576 1000;
BA_ "GenSigSendType" SG_ 1463 B11_HydHalten 0;
BA_ "GenSigAutoGenSnd" SG_ 1463 B11_HydHalten 1;
BA_ "GenSigAutoGenDsp" SG_ 1463 B11_HydHalten 1;
BA_ "GenSigSendType" SG_ 1463 B11_Br_StSt_Info 0;
BA_ "GenSigAutoGenSnd" SG_ 1463 B11_Br_StSt_Info 1;
BA_ "GenSigAutoGenDsp" SG_ 1463 B11_Br_StSt_Info 1;
BA_ "GenSigSendType" SG_ 1463 B11_OBD_Nib_VL 0;
BA_ "GenSigAutoGenSnd" SG_ 1463 B11_OBD_Nib_VL 1;
BA_ "GenSigAutoGenDsp" SG_ 1463 B11_OBD_Nib_VL 1;
BA_ "GenSigSendType" SG_ 1463 B11_OBD_Nib_VR 0;
BA_ "GenSigAutoGenSnd" SG_ 1463 B11_OBD_Nib_VR 1;
BA_ "GenSigAutoGenDsp" SG_ 1463 B11_OBD_Nib_VR 1;
BA_ "GenSigSendType" SG_ 1463 B11_OBD_Nib_HL 0;
BA_ "GenSigAutoGenSnd" SG_ 1463 B11_OBD_Nib_HL 1;
BA_ "GenSigAutoGenDsp" SG_ 1463 B11_OBD_Nib_HL 1;
BA_ "GenSigSendType" SG_ 1463 B11_OBD_Nib_HR 0;
BA_ "GenSigAutoGenSnd" SG_ 1463 B11_OBD_Nib_HR 1;
BA_ "GenSigAutoGenDsp" SG_ 1463 B11_OBD_Nib_HR 1;
BA_ "GenSigSendType" SG_ 1463 B11_EPB_Steller_akt 0;
BA_ "GenSigAutoGenSnd" SG_ 1463 B11_EPB_Steller_akt 1;
BA_ "GenSigAutoGenDsp" SG_ 1463 B11_EPB_Steller_akt 1;
BA_ "GenSigSendType" SG_ 1463 B11_EPB_Steller_gue 0;
BA_ "GenSigAutoGenSnd" SG_ 1463 B11_EPB_Steller_gue 1;
BA_ "GenSigAutoGenDsp" SG_ 1463 B11_EPB_Steller_gue 1;
BA_ "Fehlerwert" SG_ 1440 BR2_Querbeschl 255;
BA_ "GenSigStartValue" SG_ 1440 BR2_Querbeschl 127;
BA_ "GenSigAutoGenSnd" SG_ 1440 BR2_Querbeschl 1;
BA_ "GenSigAutoGenDsp" SG_ 1440 BR2_Querbeschl 1;
BA_ "GenSigFuncType" SG_ 1440 BR2_Zahnzahl 8;
BA_ "GenSigAutoGenSnd" SG_ 1440 BR2_Zahnzahl 1;
BA_ "GenSigAutoGenDsp" SG_ 1440 BR2_Zahnzahl 1;
BA_ "GenSigStartValue" SG_ 1440 BR2_Querb_Zahn 1;
BA_ "GenSigSendType" SG_ 1440 BR2_Querb_Zahn 0;
BA_ "GenSigAutoGenSnd" SG_ 1440 BR2_Querb_Zahn 1;
BA_ "GenSigAutoGenDsp" SG_ 1440 BR2_Querb_Zahn 1;
BA_ "GenSigSwitchedByIgnition" SG_ 1440 BR2_mi_Radgeschw 0;
BA_ "GenSigStartValue" SG_ 1440 BR2_mi_Radgeschw 32708;
BA_ "GenSigSendType" SG_ 1440 BR2_mi_Radgeschw 0;
BA_ "GenSigAutoGenSnd" SG_ 1440 BR2_mi_Radgeschw 1;
BA_ "GenSigAutoGenDsp" SG_ 1440 BR2_mi_Radgeschw 1;
BA_ "GenSigStartValue" SG_ 1440 BR2_Lampe_ABS 1;
BA_ "GenSigSendType" SG_ 1440 BR2_Lampe_ABS 0;
BA_ "GenSigAutoGenSnd" SG_ 1440 BR2_Lampe_ABS 1;
BA_ "GenSigAutoGenDsp" SG_ 1440 BR2_Lampe_ABS 1;
BA_ "GenSigSendType" SG_ 1440 BR2_Lampe_ASR 0;
BA_ "GenSigAutoGenSnd" SG_ 1440 BR2_Lampe_ASR 1;
BA_ "GenSigAutoGenDsp" SG_ 1440 BR2_Lampe_ASR 1;
BA_ "GenSigStartValue" SG_ 1440 BR2_Lampe_BK 1;
BA_ "GenSigSendType" SG_ 1440 BR2_Lampe_BK 0;
BA_ "GenSigAutoGenSnd" SG_ 1440 BR2_Lampe_BK 1;
BA_ "GenSigAutoGenDsp" SG_ 1440 BR2_Lampe_BK 1;
BA_ "GenSigSendType" SG_ 1440 BR2_Lampe_RKA 0;
BA_ "GenSigAutoGenSnd" SG_ 1440 BR2_Lampe_RKA 1;
BA_ "GenSigAutoGenDsp" SG_ 1440 BR2_Lampe_RKA 1;
BA_ "GenSigSwitchedByIgnition" SG_ 1440 BR2_Zaehler 0;
BA_ "GenSigFuncType" SG_ 1440 BR2_Zaehler 1;
BA_ "GenSigSendType" SG_ 1440 BR2_Zaehler 0;
BA_ "GenSigAutoGenSnd" SG_ 1440 BR2_Zaehler 1;
BA_ "GenSigAutoGenDsp" SG_ 1440 BR2_Zaehler 1;
BA_ "GenSigSendType" SG_ 1440 BR2_Text 0;
BA_ "GenSigAutoGenSnd" SG_ 1440 BR2_Text 1;
BA_ "GenSigAutoGenDsp" SG_ 1440 BR2_Text 1;
BA_ "GenSigSendType" SG_ 1440 BR2_Aku_Warn 0;
BA_ "GenSigAutoGenSnd" SG_ 1440 BR2_Aku_Warn 1;
BA_ "GenSigAutoGenDsp" SG_ 1440 BR2_Aku_Warn 1;
BA_ "GenSigSendType" SG_ 1440 BR2_HDC_aktiv 0;
BA_ "GenSigAutoGenSnd" SG_ 1440 BR2_HDC_aktiv 1;
BA_ "GenSigAutoGenDsp" SG_ 1440 BR2_HDC_aktiv 1;
BA_ "GenSigSendType" SG_ 1440 BR2_Blinkmode 0;
BA_ "GenSigAutoGenSnd" SG_ 1440 BR2_Blinkmode 1;
BA_ "GenSigAutoGenDsp" SG_ 1440 BR2_Blinkmode 1;
BA_ "GenSigSwitchedByIgnition" SG_ 1440 BR2_Wegimpulse 0;
BA_ "GenSigSendType" SG_ 1440 BR2_Wegimpulse 0;
BA_ "GenSigAutoGenSnd" SG_ 1440 BR2_Wegimpulse 1;
BA_ "GenSigAutoGenDsp" SG_ 1440 BR2_Wegimpulse 1;
BA_ "GenSigSwitchedByIgnition" SG_ 1440 BR2_Ueberl_Imp 0;
BA_ "GenSigSendType" SG_ 1440 BR2_Ueberl_Imp 0;
BA_ "GenSigAutoGenSnd" SG_ 1440 BR2_Ueberl_Imp 1;
BA_ "GenSigAutoGenDsp" SG_ 1440 BR2_Ueberl_Imp 1;
BA_ "GenSigSwitchedByIgnition" SG_ 1440 BR2_Fehlereintr 0;
BA_ "GenSigSendType" SG_ 1440 BR2_Fehlereintr 0;
BA_ "GenSigAutoGenSnd" SG_ 1440 BR2_Fehlereintr 1;
BA_ "GenSigAutoGenDsp" SG_ 1440 BR2_Fehlereintr 1;
BA_ "GenSigSendType" SG_ 1440 BR2_LampeHDC 0;
BA_ "GenSigAutoGenSnd" SG_ 1440 BR2_LampeHDC 1;
BA_ "GenSigAutoGenDsp" SG_ 1440 BR2_LampeHDC 1;
BA_ "GenSigStartValue" SG_ 1440 BR2_QB_Querbeschl 1;
BA_ "GenSigAutoGenSnd" SG_ 1440 BR2_QB_Querbeschl 1;
BA_ "GenSigAutoGenDsp" SG_ 1440 BR2_QB_Querbeschl 1;
BA_ "Fehlerwert" SG_ 1440 BR2_Sta_Imp 1;
BA_ "GenSigSwitchedByIgnition" SG_ 1440 BR2_Sta_Imp 0;
BA_ "GenSigSendType" SG_ 1440 BR2_Sta_Imp 0;
BA_ "GenSigAutoGenSnd" SG_ 1440 BR2_Sta_Imp 1;
BA_ "GenSigAutoGenDsp" SG_ 1440 BR2_Sta_Imp 1;
BA_ "GenSigFuncType" SG_ 1440 BR2_Impulszahl 8;
BA_ "GenSigSendType" SG_ 1440 BR2_Impulszahl 0;
BA_ "GenSigAutoGenSnd" SG_ 1440 BR2_Impulszahl 1;
BA_ "GenSigAutoGenDsp" SG_ 1440 BR2_Impulszahl 1;
BA_ "GenSigSwitchedByIgnition" SG_ 1440 BR2_SleepInd 0;
BA_ "GenSigSendType" SG_ 1440 BR2_SleepInd 0;
BA_ "GenSigAutoGenSnd" SG_ 1440 BR2_SleepInd 1;
BA_ "GenSigAutoGenDsp" SG_ 1440 BR2_SleepInd 1;
BA_ "GenSigSendType" SG_ 1440 BR2_Sta_Quer 0;
BA_ "GenSigAutoGenSnd" SG_ 1440 BR2_Sta_Quer 1;
BA_ "GenSigAutoGenDsp" SG_ 1440 BR2_Sta_Quer 1;
BA_ "GenSigSendType" SG_ 1184 BR3_Fahrtr_VL 0;
BA_ "GenSigAutoGenSnd" SG_ 1184 BR3_Fahrtr_VL 1;
BA_ "GenSigAutoGenDsp" SG_ 1184 BR3_Fahrtr_VL 1;
BA_ "GenSigSwitchedByIgnition" SG_ 1184 BR3_Rad_kmh_VL 0;
BA_ "GenSigStartValue" SG_ 1184 BR3_Rad_kmh_VL 32708;
BA_ "GenSigSendType" SG_ 1184 BR3_Rad_kmh_VL 0;
BA_ "GenSigAutoGenSnd" SG_ 1184 BR3_Rad_kmh_VL 1;
BA_ "GenSigAutoGenDsp" SG_ 1184 BR3_Rad_kmh_VL 1;
BA_ "GenSigSendType" SG_ 1184 BR3_Fahrtr_VR 0;
BA_ "GenSigAutoGenSnd" SG_ 1184 BR3_Fahrtr_VR 1;
BA_ "GenSigAutoGenDsp" SG_ 1184 BR3_Fahrtr_VR 1;
BA_ "GenSigSwitchedByIgnition" SG_ 1184 BR3_Rad_kmh_VR 0;
BA_ "GenSigStartValue" SG_ 1184 BR3_Rad_kmh_VR 32708;
BA_ "GenSigSendType" SG_ 1184 BR3_Rad_kmh_VR 0;
BA_ "GenSigAutoGenSnd" SG_ 1184 BR3_Rad_kmh_VR 1;
BA_ "GenSigAutoGenDsp" SG_ 1184 BR3_Rad_kmh_VR 1;
BA_ "GenSigSendType" SG_ 1184 BR3_Fahrtr_HL 0;
BA_ "GenSigAutoGenSnd" SG_ 1184 BR3_Fahrtr_HL 1;
BA_ "GenSigAutoGenDsp" SG_ 1184 BR3_Fahrtr_HL 1;
BA_ "GenSigSwitchedByIgnition" SG_ 1184 BR3_Rad_kmh_HL 0;
BA_ "GenSigStartValue" SG_ 1184 BR3_Rad_kmh_HL 32708;
BA_ "GenSigSendType" SG_ 1184 BR3_Rad_kmh_HL 0;
BA_ "GenSigAutoGenSnd" SG_ 1184 BR3_Rad_kmh_HL 1;
BA_ "GenSigAutoGenDsp" SG_ 1184 BR3_Rad_kmh_HL 1;
BA_ "GenSigSendType" SG_ 1184 BR3_Fahrtr_HR 0;
BA_ "GenSigAutoGenSnd" SG_ 1184 BR3_Fahrtr_HR 1;
BA_ "GenSigAutoGenDsp" SG_ 1184 BR3_Fahrtr_HR 1;
BA_ "GenSigSwitchedByIgnition" SG_ 1184 BR3_Rad_kmh_HR 0;
BA_ "GenSigStartValue" SG_ 1184 BR3_Rad_kmh_HR 32708;
BA_ "GenSigSendType" SG_ 1184 BR3_Rad_kmh_HR 0;
BA_ "GenSigAutoGenSnd" SG_ 1184 BR3_Rad_kmh_HR 1;
BA_ "GenSigAutoGenDsp" SG_ 1184 BR3_Rad_kmh_HR 1;
BA_ "Fehlerwert" SG_ 672 BR4_Vorgabe_Mi_ 255;
BA_ "GenSigAutoGenSnd" SG_ 672 BR4_Vorgabe_Mi_ 1;
BA_ "GenSigAutoGenDsp" SG_ 672 BR4_Vorgabe_Mi_ 1;
BA_ "Fehlerwert" SG_ 672 BR4_Vorgabe_Mi 255;
BA_ "GenSigAutoGenSnd" SG_ 672 BR4_Vorgabe_Mi 1;
BA_ "GenSigAutoGenDsp" SG_ 672 BR4_Vorgabe_Mi 1;
BA_ "GenSigAutoGenSnd" SG_ 672 BR4_Vorgabe_Max 1;
BA_ "GenSigAutoGenDsp" SG_ 672 BR4_Vorgabe_Max 1;
BA_ "Fehlerwert" SG_ 672 BR4_Vorgabe_Hi 255;
BA_ "GenSigAutoGenSnd" SG_ 672 BR4_Vorgabe_Hi 1;
BA_ "GenSigAutoGenDsp" SG_ 672 BR4_Vorgabe_Hi 1;
BA_ "GenSigAutoGenSnd" SG_ 672 BR4_Vorgabe_Min 1;
BA_ "GenSigAutoGenDsp" SG_ 672 BR4_Vorgabe_Min 1;
BA_ "GenSigSendType" SG_ 672 BR4_Einheit 0;
BA_ "GenSigAutoGenSnd" SG_ 672 BR4_Einheit 1;
BA_ "GenSigAutoGenDsp" SG_ 672 BR4_Einheit 1;
BA_ "GenSigSendType" SG_ 672 BR4_Schwelle 0;
BA_ "GenSigAutoGenSnd" SG_ 672 BR4_Schwelle 1;
BA_ "GenSigAutoGenDsp" SG_ 672 BR4_Schwelle 1;
BA_ "GenSigSendType" SG_ 672 BR4_Abschaltung_VL 0;
BA_ "GenSigAutoGenSnd" SG_ 672 BR4_Abschaltung_VL 1;
BA_ "GenSigAutoGenDsp" SG_ 672 BR4_Abschaltung_VL 1;
BA_ "GenSigSendType" SG_ 672 BR4_Abschaltung_VR 0;
BA_ "GenSigAutoGenSnd" SG_ 672 BR4_Abschaltung_VR 1;
BA_ "GenSigAutoGenDsp" SG_ 672 BR4_Abschaltung_VR 1;
BA_ "GenSigSendType" SG_ 672 BR4_Abschaltung_HL 0;
BA_ "GenSigAutoGenSnd" SG_ 672 BR4_Abschaltung_HL 1;
BA_ "GenSigAutoGenDsp" SG_ 672 BR4_Abschaltung_HL 1;
BA_ "GenSigSendType" SG_ 672 BR4_Abschaltung_HR 0;
BA_ "GenSigAutoGenSnd" SG_ 672 BR4_Abschaltung_HR 1;
BA_ "GenSigAutoGenDsp" SG_ 672 BR4_Abschaltung_HR 1;
BA_ "GenSigSendType" SG_ 672 BR4_Lampe_RKA 0;
BA_ "GenSigAutoGenSnd" SG_ 672 BR4_Lampe_RKA 1;
BA_ "GenSigAutoGenDsp" SG_ 672 BR4_Lampe_RKA 1;
BA_ "GenSigSendType" SG_ 672 BR4_Summer_RKA 0;
BA_ "GenSigAutoGenSnd" SG_ 672 BR4_Summer_RKA 1;
BA_ "GenSigAutoGenDsp" SG_ 672 BR4_Summer_RKA 1;
BA_ "GenSigSwitchedByIgnition" SG_ 672 BR4_Lampentrennung_gue 0;
BA_ "GenSigSendType" SG_ 672 BR4_Lampentrennung_gue 0;
BA_ "GenSigAutoGenSnd" SG_ 672 BR4_Lampentrennung_gue 1;
BA_ "GenSigAutoGenDsp" SG_ 672 BR4_Lampentrennung_gue 1;
BA_ "GenSigStartValue" SG_ 672 BR4_Lampe_ASRESP 1;
BA_ "GenSigSendType" SG_ 672 BR4_Lampe_ASRESP 0;
BA_ "GenSigAutoGenSnd" SG_ 672 BR4_Lampe_ASRESP 1;
BA_ "GenSigAutoGenDsp" SG_ 672 BR4_Lampe_ASRESP 1;
BA_ "GenSigSendType" SG_ 672 BR4_ESP_Off 0;
BA_ "GenSigAutoGenSnd" SG_ 672 BR4_ESP_Off 1;
BA_ "GenSigAutoGenDsp" SG_ 672 BR4_ESP_Off 1;
BA_ "GenSigSendType" SG_ 672 BR1_ASR_ESP 0;
BA_ "GenSigAutoGenSnd" SG_ 672 BR1_ASR_ESP 1;
BA_ "GenSigAutoGenDsp" SG_ 672 BR1_ASR_ESP 1;
BA_ "GenSigSwitchedByIgnition" SG_ 672 BR4_RKA_Verbau 0;
BA_ "GenSigSendType" SG_ 672 BR4_RKA_Verbau 0;
BA_ "Fehlerwert" SG_ 672 BR4_Unterdruck 255;
BA_ "GenSigSendType" SG_ 672 BR4_Unterdruck 0;
BA_ "GenSigAutoGenSnd" SG_ 672 BR4_Unterdruck 1;
BA_ "GenSigAutoGenDsp" SG_ 672 BR4_Unterdruck 1;
BA_ "GenSigStartValue" SG_ 672 BR4_Status_ESP 1;
BA_ "GenSigSendType" SG_ 672 BR4_Status_ESP 0;
BA_ "GenSigAutoGenSnd" SG_ 672 BR4_Status_ESP 1;
BA_ "GenSigAutoGenDsp" SG_ 672 BR4_Status_ESP 1;
BA_ "GenSigSwitchedByIgnition" SG_ 672 BR4_Zaehler 0;
BA_ "GenSigFuncType" SG_ 672 BR4_Zaehler 1;
BA_ "GenSigSendType" SG_ 672 BR4_Zaehler 0;
BA_ "GenSigAutoGenSnd" SG_ 672 BR4_Zaehler 1;
BA_ "GenSigAutoGenDsp" SG_ 672 BR4_Zaehler 1;
BA_ "GenSigSwitchedByIgnition" SG_ 672 BR4_Checksum 0;
BA_ "GenSigFuncType" SG_ 672 BR4_Checksum 4;
BA_ "GenSigSendType" SG_ 672 BR4_Checksum 0;
BA_ "GenSigAutoGenSnd" SG_ 672 BR4_Checksum 1;
BA_ "GenSigAutoGenDsp" SG_ 672 BR4_Checksum 1;
BA_ "Fehlerwert" SG_ 1192 BR5_Giergeschw 16383;
BA_ "GenSigSendType" SG_ 1192 BR5_Giergeschw 0;
BA_ "GenSigAutoGenSnd" SG_ 1192 BR5_Giergeschw 1;
BA_ "GenSigAutoGenDsp" SG_ 1192 BR5_Giergeschw 1;
BA_ "GenSigStartValue" SG_ 1192 BR5_Sta_Gierrate 1;
BA_ "GenSigSendType" SG_ 1192 BR5_Sta_Gierrate 0;
BA_ "GenSigAutoGenSnd" SG_ 1192 BR5_Sta_Gierrate 1;
BA_ "GenSigAutoGenDsp" SG_ 1192 BR5_Sta_Gierrate 1;
BA_ "GenSigSendType" SG_ 1192 BR5_Vorzeichen 0;
BA_ "GenSigAutoGenSnd" SG_ 1192 BR5_Vorzeichen 1;
BA_ "GenSigAutoGenDsp" SG_ 1192 BR5_Vorzeichen 1;
BA_ "Fehlerwert" SG_ 1192 BR5_Bremsdruck 4095;
BA_ "GenSigSendType" SG_ 1192 BR5_Bremsdruck 0;
BA_ "GenSigAutoGenSnd" SG_ 1192 BR5_Bremsdruck 1;
BA_ "GenSigAutoGenDsp" SG_ 1192 BR5_Bremsdruck 1;
BA_ "GenSigSendType" SG_ 1192 BR5_Stillstand 0;
BA_ "GenSigAutoGenSnd" SG_ 1192 BR5_Stillstand 1;
BA_ "GenSigAutoGenDsp" SG_ 1192 BR5_Stillstand 1;
BA_ "GenSigStartValue" SG_ 1192 BR5_Druckgueltig 1;
BA_ "GenSigSendType" SG_ 1192 BR5_Druckgueltig 0;
BA_ "GenSigAutoGenSnd" SG_ 1192 BR5_Druckgueltig 1;
BA_ "GenSigAutoGenDsp" SG_ 1192 BR5_Druckgueltig 1;
BA_ "GenSigSendType" SG_ 1192 BR5_Sta_Druck 0;
BA_ "GenSigAutoGenSnd" SG_ 1192 BR5_Sta_Druck 1;
BA_ "GenSigAutoGenDsp" SG_ 1192 BR5_Sta_Druck 1;
BA_ "GenSigSendType" SG_ 1192 BR5_Sign_Druck 0;
BA_ "GenSigAutoGenSnd" SG_ 1192 BR5_Sign_Druck 1;
BA_ "GenSigAutoGenDsp" SG_ 1192 BR5_Sign_Druck 1;
BA_ "GenSigSwitchedByIgnition" SG_ 1192 ESP_Anforderung_EPB 0;
BA_ "GenSigSendType" SG_ 1192 ESP_Anforderung_EPB 0;
BA_ "GenSigAutoGenSnd" SG_ 1192 ESP_Anforderung_EPB 1;
BA_ "GenSigAutoGenDsp" SG_ 1192 ESP_Anforderung_EPB 1;
BA_ "GenSigSwitchedByIgnition" SG_ 1192 ESP_Autohold_aktiv 0;
BA_ "GenSigSendType" SG_ 1192 ESP_Autohold_aktiv 0;
BA_ "GenSigAutoGenSnd" SG_ 1192 ESP_Autohold_aktiv 1;
BA_ "GenSigAutoGenDsp" SG_ 1192 ESP_Autohold_aktiv 1;
BA_ "GenSigSwitchedByIgnition" SG_ 1192 ESP_Autohold_Standby 0;
BA_ "GenSigSendType" SG_ 1192 ESP_Autohold_Standby 0;
BA_ "GenSigAutoGenSnd" SG_ 1192 ESP_Autohold_Standby 1;
BA_ "GenSigAutoGenDsp" SG_ 1192 ESP_Autohold_Standby 1;
BA_ "Fehlerwert" SG_ 1192 BR5_Anhi_Sta 1;
BA_ "GenSigSendType" SG_ 1192 BR5_Anhi_Sta 0;
BA_ "GenSigAutoGenSnd" SG_ 1192 BR5_Anhi_Sta 1;
BA_ "GenSigAutoGenDsp" SG_ 1192 BR5_Anhi_Sta 1;
BA_ "GenSigSendType" SG_ 1192 BR5_Anhi_akt 0;
BA_ "GenSigAutoGenSnd" SG_ 1192 BR5_Anhi_akt 1;
BA_ "GenSigAutoGenDsp" SG_ 1192 BR5_Anhi_akt 1;
BA_ "GenSigSendType" SG_ 1192 BR5_v_Ueberw 0;
BA_ "GenSigAutoGenSnd" SG_ 1192 BR5_v_Ueberw 1;
BA_ "GenSigAutoGenDsp" SG_ 1192 BR5_v_Ueberw 1;
BA_ "GenSigSendType" SG_ 1192 BR5_AnhStabAktiv 0;
BA_ "GenSigAutoGenSnd" SG_ 1192 BR5_AnhStabAktiv 1;
BA_ "GenSigAutoGenDsp" SG_ 1192 BR5_AnhStabAktiv 1;
BA_ "GenSigSendType" SG_ 1192 BR5_Notbremsung 0;
BA_ "GenSigAutoGenSnd" SG_ 1192 BR5_Notbremsung 1;
BA_ "GenSigAutoGenDsp" SG_ 1192 BR5_Notbremsung 1;
BA_ "GenSigSwitchedByIgnition" SG_ 1192 BR5_Fahrer_tritt_ZBR_Schw 0;
BA_ "GenSigSendType" SG_ 1192 BR5_Fahrer_tritt_ZBR_Schw 0;
BA_ "GenSigAutoGenSnd" SG_ 1192 BR5_Fahrer_tritt_ZBR_Schw 1;
BA_ "GenSigAutoGenDsp" SG_ 1192 BR5_Fahrer_tritt_ZBR_Schw 1;
BA_ "GenSigSendType" SG_ 1192 BR5_AWV2_Bremsruck 0;
BA_ "GenSigAutoGenSnd" SG_ 1192 BR5_AWV2_Bremsruck 1;
BA_ "GenSigAutoGenDsp" SG_ 1192 BR5_AWV2_Bremsruck 1;
BA_ "Fehlerwert" SG_ 1192 BR5_AWV2_Fehler 1;
BA_ "GenSigSendType" SG_ 1192 BR5_AWV2_Fehler 0;
BA_ "GenSigAutoGenSnd" SG_ 1192 BR5_AWV2_Fehler 1;
BA_ "GenSigAutoGenDsp" SG_ 1192 BR5_AWV2_Fehler 1;
BA_ "GenSigSwitchedByIgnition" SG_ 1192 BR5_ZT_Rueckk_Umsetz 0;
BA_ "GenSigSendType" SG_ 1192 BR5_ZT_Rueckk_Umsetz 0;
BA_ "GenSigAutoGenSnd" SG_ 1192 BR5_ZT_Rueckk_Umsetz 1;
BA_ "GenSigAutoGenDsp" SG_ 1192 BR5_ZT_Rueckk_Umsetz 1;
BA_ "GenSigSwitchedByIgnition" SG_ 1192 BR5_ANB_CM_Rueckk_Umsetz 0;
BA_ "GenSigSendType" SG_ 1192 BR5_ANB_CM_Rueckk_Umsetz 0;
BA_ "GenSigAutoGenSnd" SG_ 1192 BR5_ANB_CM_Rueckk_Umsetz 1;
BA_ "GenSigAutoGenDsp" SG_ 1192 BR5_ANB_CM_Rueckk_Umsetz 1;
BA_ "GenSigSendType" SG_ 1192 BR5_ECD_Lampe 0;
BA_ "GenSigAutoGenSnd" SG_ 1192 BR5_ECD_Lampe 1;
BA_ "GenSigAutoGenDsp" SG_ 1192 BR5_ECD_Lampe 1;
BA_ "GenSigSwitchedByIgnition" SG_ 1192 BR5_Zaehler 0;
BA_ "GenSigFuncType" SG_ 1192 BR5_Zaehler 1;
BA_ "GenSigSendType" SG_ 1192 BR5_Zaehler 0;
BA_ "GenSigAutoGenSnd" SG_ 1192 BR5_Zaehler 1;
BA_ "GenSigAutoGenDsp" SG_ 1192 BR5_Zaehler 1;
BA_ "GenSigSwitchedByIgnition" SG_ 1192 BR5_Checksumme 0;
BA_ "GenSigFuncType" SG_ 1192 BR5_Checksumme 4;
BA_ "GenSigSendType" SG_ 1192 BR5_Checksumme 0;
BA_ "GenSigAutoGenSnd" SG_ 1192 BR5_Checksumme 1;
BA_ "GenSigAutoGenDsp" SG_ 1192 BR5_Checksumme 1;
BA_ "GenSigSwitchedByIgnition" SG_ 428 BR8_Checksumme 0;
BA_ "GenSigFuncType" SG_ 428 BR8_Checksumme 4;
BA_ "GenSigSendType" SG_ 428 BR8_Checksumme 0;
BA_ "GenSigAutoGenSnd" SG_ 428 BR8_Checksumme 1;
BA_ "GenSigAutoGenDsp" SG_ 428 BR8_Checksumme 1;
BA_ "GenSigSwitchedByIgnition" SG_ 428 BR8_Zaehler 0;
BA_ "GenSigFuncType" SG_ 428 BR8_Zaehler 1;
BA_ "GenSigSendType" SG_ 428 BR8_Zaehler 0;
BA_ "GenSigAutoGenSnd" SG_ 428 BR8_Zaehler 1;
BA_ "GenSigAutoGenDsp" SG_ 428 BR8_Zaehler 1;
BA_ "GenSigSendType" SG_ 428 BR8_Sta_ACC_Anf 0;
BA_ "GenSigAutoGenSnd" SG_ 428 BR8_Sta_ACC_Anf 1;
BA_ "GenSigAutoGenDsp" SG_ 428 BR8_Sta_ACC_Anf 1;
BA_ "GenSigSendType" SG_ 428 BR8_Verz_EPB_akt 0;
BA_ "GenSigAutoGenSnd" SG_ 428 BR8_Verz_EPB_akt 1;
BA_ "GenSigAutoGenDsp" SG_ 428 BR8_Verz_EPB_akt 1;
BA_ "GenSigSendType" SG_ 428 BR8_Sta_Br_temp 0;
BA_ "GenSigAutoGenSnd" SG_ 428 BR8_Sta_Br_temp 1;
BA_ "GenSigAutoGenDsp" SG_ 428 BR8_Sta_Br_temp 1;
BA_ "GenSigSendType" SG_ 428 BR8_Sta_Br_Druck 0;
BA_ "GenSigAutoGenSnd" SG_ 428 BR8_Sta_Br_Druck 1;
BA_ "GenSigAutoGenDsp" SG_ 428 BR8_Sta_Br_Druck 1;
BA_ "Fehlerwert" SG_ 428 BR8_Istbeschl 511;
BA_ "GenSigStartValue" SG_ 428 BR8_Istbeschl 361;
BA_ "GenSigSendType" SG_ 428 BR8_Istbeschl 0;
BA_ "GenSigAutoGenSnd" SG_ 428 BR8_Istbeschl 1;
BA_ "GenSigAutoGenDsp" SG_ 428 BR8_Istbeschl 1;
BA_ "GenSigSendType" SG_ 428 BR8_Sta_HW_BLS 0;
BA_ "GenSigAutoGenSnd" SG_ 428 BR8_Sta_HW_BLS 1;
BA_ "GenSigAutoGenDsp" SG_ 428 BR8_Sta_HW_BLS 1;
BA_ "GenSigStartValue" SG_ 428 BR8_QB_LBeschl 1;
BA_ "GenSigSendType" SG_ 428 BR8_QB_LBeschl 0;
BA_ "GenSigAutoGenSnd" SG_ 428 BR8_QB_LBeschl 1;
BA_ "GenSigAutoGenDsp" SG_ 428 BR8_QB_LBeschl 1;
BA_ "GenSigSendType" SG_ 428 BR8_ESC_Mode 0;
BA_ "GenSigAutoGenSnd" SG_ 428 BR8_ESC_Mode 1;
BA_ "GenSigAutoGenDsp" SG_ 428 BR8_ESC_Mode 1;
BA_ "GenSigSendType" SG_ 428 BR8_aktBrSyst 0;
BA_ "GenSigAutoGenSnd" SG_ 428 BR8_aktBrSyst 1;
BA_ "GenSigAutoGenDsp" SG_ 428 BR8_aktBrSyst 1;
BA_ "GenSigSendType" SG_ 428 BR8_Fa_bremst 0;
BA_ "GenSigAutoGenSnd" SG_ 428 BR8_Fa_bremst 1;
BA_ "GenSigAutoGenDsp" SG_ 428 BR8_Fa_bremst 1;
BA_ "GenSigSendType" SG_ 428 BR8_StaBrSyst 0;
BA_ "GenSigAutoGenSnd" SG_ 428 BR8_StaBrSyst 1;
BA_ "GenSigAutoGenDsp" SG_ 428 BR8_StaBrSyst 1;
BA_ "Fehlerwert" SG_ 428 BR8_Laengsbeschl 1023;
BA_ "GenSigSendType" SG_ 428 BR8_Laengsbeschl 0;
BA_ "GenSigAutoGenSnd" SG_ 428 BR8_Laengsbeschl 1;
BA_ "GenSigAutoGenDsp" SG_ 428 BR8_Laengsbeschl 1;
BA_ "GenSigSendType" SG_ 428 BR8_Sta_ADR_BR 0;
BA_ "GenSigAutoGenSnd" SG_ 428 BR8_Sta_ADR_BR 1;
BA_ "GenSigAutoGenDsp" SG_ 428 BR8_Sta_ADR_BR 1;
BA_ "GenSigSendType" SG_ 428 BR8_Quattro 0;
BA_ "GenSigAutoGenSnd" SG_ 428 BR8_Quattro 1;
BA_ "GenSigAutoGenDsp" SG_ 428 BR8_Quattro 1;
BA_ "GenSigStartValue" SG_ 428 BR8_Sta_VerzReg 1;
BA_ "GenSigSendType" SG_ 428 BR8_Sta_VerzReg 0;
BA_ "GenSigAutoGenSnd" SG_ 428 BR8_Sta_VerzReg 1;
BA_ "GenSigAutoGenDsp" SG_ 428 BR8_Sta_VerzReg 1;
BA_ "Fehlerwert" SG_ 428 BR8_Sta_BLS 1;
BA_ "GenSigSendType" SG_ 428 BR8_Sta_BLS 0;
BA_ "GenSigAutoGenSnd" SG_ 428 BR8_Sta_BLS 1;
BA_ "GenSigAutoGenDsp" SG_ 428 BR8_Sta_BLS 1;
BA_ "GenSigSendType" SG_ 428 BR8_Verz_EPB 0;
BA_ "GenSigAutoGenSnd" SG_ 428 BR8_Verz_EPB 1;
BA_ "GenSigAutoGenDsp" SG_ 428 BR8_Verz_EPB 1;
BA_ "GenSigStartValue" SG_ 428 BR8_Check_EPB 1;
BA_ "GenSigSendType" SG_ 428 BR8_Check_EPB 0;
BA_ "GenSigAutoGenSnd" SG_ 428 BR8_Check_EPB 1;
BA_ "GenSigAutoGenDsp" SG_ 428 BR8_Check_EPB 1;
BA_ "GenSigSwitchedByIgnition" SG_ 174 BR9_Checksumme 0;
BA_ "GenSigFuncType" SG_ 174 BR9_Checksumme 4;
BA_ "GenSigSendType" SG_ 174 BR9_Checksumme 0;
BA_ "GenSigAutoGenSnd" SG_ 174 BR9_Checksumme 1;
BA_ "GenSigAutoGenDsp" SG_ 174 BR9_Checksumme 1;
BA_ "Fehlerwert" SG_ 174 BR9_Sta_ESP_PLA 2;
BA_ "GenSigSwitchedByIgnition" SG_ 174 BR9_Sta_ESP_PLA 0;
BA_ "GenSigStartValue" SG_ 174 BR9_Sta_ESP_PLA 1;
BA_ "GenSigSendType" SG_ 174 BR9_Sta_ESP_PLA 0;
BA_ "GenSigSwitchedByIgnition" SG_ 174 BR9_Zaehler 0;
BA_ "GenSigFuncType" SG_ 174 BR9_Zaehler 1;
BA_ "GenSigSendType" SG_ 174 BR9_Zaehler 0;
BA_ "GenSigAutoGenSnd" SG_ 174 BR9_Zaehler 1;
BA_ "GenSigAutoGenDsp" SG_ 174 BR9_Zaehler 1;
BA_ "GenSigSendType" SG_ 174 BR9_LMOffset 0;
BA_ "GenSigAutoGenSnd" SG_ 174 BR9_LMOffset 1;
BA_ "GenSigAutoGenDsp" SG_ 174 BR9_LMOffset 1;
BA_ "GenSigSendType" SG_ 174 BR9_LMOffSign 0;
BA_ "GenSigAutoGenSnd" SG_ 174 BR9_LMOffSign 1;
BA_ "GenSigAutoGenDsp" SG_ 174 BR9_LMOffSign 1;
BA_ "GenSigSendType" SG_ 174 BR9_LWOffset 0;
BA_ "GenSigAutoGenSnd" SG_ 174 BR9_LWOffset 1;
BA_ "GenSigAutoGenDsp" SG_ 174 BR9_LWOffset 1;
BA_ "GenSigSendType" SG_ 174 BR9_LWOffSign 0;
BA_ "GenSigAutoGenSnd" SG_ 174 BR9_LWOffSign 1;
BA_ "GenSigAutoGenDsp" SG_ 174 BR9_LWOffSign 1;
BA_ "GenSigSendType" SG_ 174 BR9_Sta_DSR 0;
BA_ "GenSigAutoGenSnd" SG_ 174 BR9_Sta_DSR 1;
BA_ "GenSigAutoGenDsp" SG_ 174 BR9_Sta_DSR 1;
BA_ "GenSigSwitchedByIgnition" SG_ 174 BR9_PLA_Abbruch 0;
BA_ "GenSigSendType" SG_ 174 BR9_PLA_Abbruch 0;
BA_ "GenSigFuncType" SG_ 1524 BCN_Checksumme 4;
BA_ "GenSigSendType" SG_ 1524 BCN_Checksumme 0;
BA_ "GenSigAutoGenSnd" SG_ 1524 BCN_Checksumme 1;
BA_ "GenSigAutoGenDsp" SG_ 1524 BCN_Checksumme 1;
BA_ "GenSigSendType" SG_ 1524 BCN_BremsenVar 0;
BA_ "GenSigAutoGenSnd" SG_ 1524 BCN_BremsenVar 1;
BA_ "GenSigAutoGenDsp" SG_ 1524 BCN_BremsenVar 1;
BA_ "GenSigSendType" SG_ 1524 BCN_AntriebsVar 0;
BA_ "GenSigAutoGenSnd" SG_ 1524 BCN_AntriebsVar 1;
BA_ "GenSigAutoGenDsp" SG_ 1524 BCN_AntriebsVar 1;
BA_ "GenSigSendType" SG_ 1091 RKA_Prio1_Warnung 3;
BA_ "GenSigAutoGenSnd" SG_ 1091 RKA_Prio1_Warnung 1;
BA_ "GenSigAutoGenDsp" SG_ 1091 RKA_Prio1_Warnung 1;
BA_ "GenSigSendType" SG_ 1091 RKA_Prio2_Warnung 3;
BA_ "GenSigAutoGenSnd" SG_ 1091 RKA_Prio2_Warnung 1;
BA_ "GenSigAutoGenDsp" SG_ 1091 RKA_Prio2_Warnung 1;
BA_ "GenSigSendType" SG_ 1091 RKA_Warnungen 3;
BA_ "GenSigAutoGenSnd" SG_ 1091 RKA_Warnungen 1;
BA_ "GenSigAutoGenDsp" SG_ 1091 RKA_Warnungen 1;
BA_ "GenSigStartValue" SG_ 1091 RKA_FMVSS_138_Warnung 1;
BA_ "GenSigSendType" SG_ 1091 RKA_FMVSS_138_Warnung 3;
BA_ "GenSigAutoGenSnd" SG_ 1091 RKA_FMVSS_138_Warnung 1;
BA_ "GenSigAutoGenDsp" SG_ 1091 RKA_FMVSS_138_Warnung 1;
BA_ "GenSigSendType" SG_ 1091 RKA_FMVSS_138_MIL 3;
BA_ "GenSigAutoGenSnd" SG_ 1091 RKA_FMVSS_138_MIL 1;
BA_ "GenSigAutoGenDsp" SG_ 1091 RKA_FMVSS_138_MIL 1;
BA_ "GenSigSendType" SG_ 1091 RDK_Status 3;
BA_ "GenSigAutoGenSnd" SG_ 1091 RDK_Status 1;
BA_ "GenSigAutoGenDsp" SG_ 1091 RDK_Status 1;
BA_ "GenSigSendType" SG_ 1091 RKA_Ack_IstZu_Solldruecke 3;
BA_ "GenSigAutoGenSnd" SG_ 1091 RKA_Ack_IstZu_Solldruecke 1;
BA_ "GenSigAutoGenDsp" SG_ 1091 RKA_Ack_IstZu_Solldruecke 1;
BA_ "GenSigSendType" SG_ 1091 RDK_neue_Solldruecke 3;
BA_ "GenSigAutoGenSnd" SG_ 1091 RDK_neue_Solldruecke 1;
BA_ "GenSigAutoGenDsp" SG_ 1091 RDK_neue_Solldruecke 1;
BA_ "GenSigSwitchedByIgnition" SG_ 1091 RKA_Menue 0;
BA_ "GenSigSendType" SG_ 1091 RKA_Menue 0;
BA_ "GenSigSendType" SG_ 1091 RKA_KD_Fehler 0;
BA_ "GenSigAutoGenSnd" SG_ 1091 RKA_KD_Fehler 1;
BA_ "GenSigAutoGenDsp" SG_ 1091 RKA_KD_Fehler 1;
BA_ "GenSigSendType" SG_ 1091 RDK_Sensor_Multiplex 0;
BA_ "GenSigAutoGenSnd" SG_ 1091 RDK_Sensor_Multiplex 1;
BA_ "GenSigAutoGenDsp" SG_ 1091 RDK_Sensor_Multiplex 1;
BA_ "GenSigSendType" SG_ 1091 RDK_xx_Status_Sensor 0;
BA_ "GenSigAutoGenSnd" SG_ 1091 RDK_xx_Status_Sensor 1;
BA_ "GenSigAutoGenDsp" SG_ 1091 RDK_xx_Status_Sensor 1;
BA_ "GenSigSendType" SG_ 1091 RDK_xx_Color 0;
BA_ "GenSigAutoGenSnd" SG_ 1091 RDK_xx_Color 1;
BA_ "GenSigAutoGenDsp" SG_ 1091 RDK_xx_Color 1;
BA_ "GenSigSendType" SG_ 1091 RDK_xx_Ist_Temp 0;
BA_ "GenSigAutoGenSnd" SG_ 1091 RDK_xx_Ist_Temp 1;
BA_ "GenSigAutoGenDsp" SG_ 1091 RDK_xx_Ist_Temp 1;
BA_ "GenSigSendType" SG_ 1091 RDK_xx_Ist_Druck 0;
BA_ "GenSigAutoGenSnd" SG_ 1091 RDK_xx_Ist_Druck 1;
BA_ "GenSigAutoGenDsp" SG_ 1091 RDK_xx_Ist_Druck 1;
BA_ "GenSigSendType" SG_ 1091 RDK_xx_Soll_Druck 0;
BA_ "GenSigAutoGenSnd" SG_ 1091 RDK_xx_Soll_Druck 1;
BA_ "GenSigAutoGenDsp" SG_ 1091 RDK_xx_Soll_Druck 1;
BA_ "GenSigSwitchedByIgnition" SG_ 1392 BSL_ZAS_Kl_S 0;
BA_ "GenSigSendType" SG_ 1392 BSL_ZAS_Kl_S 3;
BA_ "GenSigAutoGenSnd" SG_ 1392 BSL_ZAS_Kl_S 1;
BA_ "GenSigAutoGenDsp" SG_ 1392 BSL_ZAS_Kl_S 1;
BA_ "GenSigSwitchedByIgnition" SG_ 1392 BSL_ZAS_Kl_15 0;
BA_ "GenSigFuncType" SG_ 1392 BSL_ZAS_Kl_15 6;
BA_ "GenSigSendType" SG_ 1392 BSL_ZAS_Kl_15 3;
BA_ "GenSigAutoGenSnd" SG_ 1392 BSL_ZAS_Kl_15 1;
BA_ "GenSigAutoGenDsp" SG_ 1392 BSL_ZAS_Kl_15 1;
BA_ "GenSigSwitchedByIgnition" SG_ 1392 BSL_ZAS_Kl_X 0;
BA_ "GenSigSendType" SG_ 1392 BSL_ZAS_Kl_X 3;
BA_ "GenSigAutoGenSnd" SG_ 1392 BSL_ZAS_Kl_X 1;
BA_ "GenSigAutoGenDsp" SG_ 1392 BSL_ZAS_Kl_X 1;
BA_ "GenSigSwitchedByIgnition" SG_ 1392 BSL_ZAS_Kl_50 0;
BA_ "GenSigSendType" SG_ 1392 BSL_ZAS_Kl_50 3;
BA_ "GenSigAutoGenSnd" SG_ 1392 BSL_ZAS_Kl_50 1;
BA_ "GenSigAutoGenDsp" SG_ 1392 BSL_ZAS_Kl_50 1;
BA_ "GenSigSwitchedByIgnition" SG_ 1392 BSL_Parklicht 0;
BA_ "GenSigSendType" SG_ 1392 BSL_Parklicht 3;
BA_ "GenSigAutoGenSnd" SG_ 1392 BSL_Parklicht 1;
BA_ "GenSigAutoGenDsp" SG_ 1392 BSL_Parklicht 1;
BA_ "GenSigSwitchedByIgnition" SG_ 1392 BSL_LL_Anheb2 0;
BA_ "GenSigSendType" SG_ 1392 BSL_LL_Anheb2 3;
BA_ "GenSigAutoGenSnd" SG_ 1392 BSL_LL_Anheb2 1;
BA_ "GenSigAutoGenDsp" SG_ 1392 BSL_LL_Anheb2 1;
BA_ "GenSigSwitchedByIgnition" SG_ 1392 BSL_Kl_15_Motor 0;
BA_ "GenSigSendType" SG_ 1392 BSL_Kl_15_Motor 3;
BA_ "GenSigAutoGenSnd" SG_ 1392 BSL_Kl_15_Motor 1;
BA_ "GenSigAutoGenDsp" SG_ 1392 BSL_Kl_15_Motor 1;
BA_ "GenSigSwitchedByIgnition" SG_ 1392 BSL_Kl_L 0;
BA_ "GenSigSendType" SG_ 1392 BSL_Kl_L 3;
BA_ "GenSigAutoGenSnd" SG_ 1392 BSL_Kl_L 1;
BA_ "GenSigAutoGenDsp" SG_ 1392 BSL_Kl_L 1;
BA_ "GenSigSwitchedByIgnition" SG_ 1392 BSL_LL_Anheb 0;
BA_ "GenSigSendType" SG_ 1392 BSL_LL_Anheb 3;
BA_ "GenSigAutoGenSnd" SG_ 1392 BSL_LL_Anheb 1;
BA_ "GenSigAutoGenDsp" SG_ 1392 BSL_LL_Anheb 1;
BA_ "Fehlerwert" SG_ 1392 BSL_Sta_UBat 3;
BA_ "GenSigSwitchedByIgnition" SG_ 1392 BSL_Sta_UBat 0;
BA_ "GenSigSendType" SG_ 1392 BSL_Sta_UBat 3;
BA_ "GenSigAutoGenSnd" SG_ 1392 BSL_Sta_UBat 1;
BA_ "GenSigAutoGenDsp" SG_ 1392 BSL_Sta_UBat 1;
BA_ "Fehlerwert" SG_ 1392 BSL_Sta_StBat 3;
BA_ "GenSigSwitchedByIgnition" SG_ 1392 BSL_Sta_StBat 0;
BA_ "GenSigSendType" SG_ 1392 BSL_Sta_StBat 3;
BA_ "GenSigAutoGenSnd" SG_ 1392 BSL_Sta_StBat 1;
BA_ "GenSigAutoGenDsp" SG_ 1392 BSL_Sta_StBat 1;
BA_ "Fehlerwert" SG_ 1392 BSL_Fehlereintr 1;
BA_ "GenSigSwitchedByIgnition" SG_ 1392 BSL_Fehlereintr 0;
BA_ "GenSigSendType" SG_ 1392 BSL_Fehlereintr 3;
BA_ "GenSigAutoGenSnd" SG_ 1392 BSL_Fehlereintr 1;
BA_ "GenSigAutoGenDsp" SG_ 1392 BSL_Fehlereintr 1;
BA_ "GenSigSwitchedByIgnition" SG_ 1392 BSL_Sta_LWR 0;
BA_ "GenSigSendType" SG_ 1392 BSL_Sta_LWR 3;
BA_ "GenSigAutoGenSnd" SG_ 1392 BSL_Sta_LWR 1;
BA_ "GenSigAutoGenDsp" SG_ 1392 BSL_Sta_LWR 1;
BA_ "GenSigSwitchedByIgnition" SG_ 1392 BSL_Motor_Haube 0;
BA_ "GenSigSendType" SG_ 1392 BSL_Motor_Haube 3;
BA_ "GenSigAutoGenSnd" SG_ 1392 BSL_Motor_Haube 1;
BA_ "GenSigAutoGenDsp" SG_ 1392 BSL_Motor_Haube 1;
BA_ "Fehlerwert" SG_ 1392 BSL_UBat 255;
BA_ "GenSigSwitchedByIgnition" SG_ 1392 BSL_UBat 0;
BA_ "GenSigSendType" SG_ 1392 BSL_UBat 0;
BA_ "GenSigAutoGenSnd" SG_ 1392 BSL_UBat 1;
BA_ "GenSigAutoGenDsp" SG_ 1392 BSL_UBat 1;
BA_ "GenSigSwitchedByIgnition" SG_ 1392 BSL_Hecksch 0;
BA_ "GenSigSendType" SG_ 1392 BSL_Hecksch 0;
BA_ "GenSigAutoGenSnd" SG_ 1392 BSL_Hecksch 1;
BA_ "GenSigAutoGenDsp" SG_ 1392 BSL_Hecksch 1;
BA_ "GenSigSwitchedByIgnition" SG_ 1392 BSL_Frontsch 0;
BA_ "GenSigSendType" SG_ 1392 BSL_Frontsch 0;
BA_ "GenSigAutoGenSnd" SG_ 1392 BSL_Frontsch 1;
BA_ "GenSigAutoGenDsp" SG_ 1392 BSL_Frontsch 1;
BA_ "GenSigSwitchedByIgnition" SG_ 1392 BSL_Aussensp 0;
BA_ "GenSigSendType" SG_ 1392 BSL_Aussensp 0;
BA_ "GenSigAutoGenSnd" SG_ 1392 BSL_Aussensp 1;
BA_ "GenSigAutoGenDsp" SG_ 1392 BSL_Aussensp 1;
BA_ "GenSigSwitchedByIgnition" SG_ 1392 BSL_Sitzheiz 0;
BA_ "GenSigSendType" SG_ 1392 BSL_Sitzheiz 0;
BA_ "GenSigAutoGenSnd" SG_ 1392 BSL_Sitzheiz 1;
BA_ "GenSigAutoGenDsp" SG_ 1392 BSL_Sitzheiz 1;
BA_ "GenSigSwitchedByIgnition" SG_ 1392 BSL_Lenkradheiz 0;
BA_ "GenSigSendType" SG_ 1392 BSL_Lenkradheiz 0;
BA_ "GenSigAutoGenSnd" SG_ 1392 BSL_Lenkradheiz 1;
BA_ "GenSigAutoGenDsp" SG_ 1392 BSL_Lenkradheiz 1;
BA_ "GenSigSwitchedByIgnition" SG_ 1392 BSL_Wasserheiz 0;
BA_ "GenSigSendType" SG_ 1392 BSL_Wasserheiz 0;
BA_ "GenSigAutoGenSnd" SG_ 1392 BSL_Wasserheiz 1;
BA_ "GenSigAutoGenDsp" SG_ 1392 BSL_Wasserheiz 1;
BA_ "GenSigSwitchedByIgnition" SG_ 1392 BSL_Sitzbelueft 0;
BA_ "GenSigSendType" SG_ 1392 BSL_Sitzbelueft 0;
BA_ "GenSigAutoGenSnd" SG_ 1392 BSL_Sitzbelueft 1;
BA_ "GenSigAutoGenDsp" SG_ 1392 BSL_Sitzbelueft 1;
BA_ "GenSigSwitchedByIgnition" SG_ 1392 BSL_Clima 0;
BA_ "GenSigSendType" SG_ 1392 BSL_Clima 0;
BA_ "GenSigAutoGenSnd" SG_ 1392 BSL_Clima 1;
BA_ "GenSigAutoGenDsp" SG_ 1392 BSL_Clima 1;
BA_ "GenSigSwitchedByIgnition" SG_ 1392 BSL_BSG_2_alt 0;
BA_ "GenSigFuncType" SG_ 1392 BSL_BSG_2_alt 5;
BA_ "GenSigStartValue" SG_ 1392 BSL_BSG_2_alt 1;
BA_ "GenSigSendType" SG_ 1392 BSL_BSG_2_alt 0;
BA_ "GenSigAutoGenSnd" SG_ 1392 BSL_BSG_2_alt 1;
BA_ "GenSigAutoGenDsp" SG_ 1392 BSL_BSG_2_alt 1;
BA_ "GenSigSwitchedByIgnition" SG_ 1392 BSL_BSG_3_alt 0;
BA_ "GenSigFuncType" SG_ 1392 BSL_BSG_3_alt 5;
BA_ "GenSigStartValue" SG_ 1392 BSL_BSG_3_alt 1;
BA_ "GenSigSendType" SG_ 1392 BSL_BSG_3_alt 0;
BA_ "GenSigAutoGenSnd" SG_ 1392 BSL_BSG_3_alt 1;
BA_ "GenSigAutoGenDsp" SG_ 1392 BSL_BSG_3_alt 1;
BA_ "GenSigSwitchedByIgnition" SG_ 1392 BSL_Kuehlerlueft 0;
BA_ "GenSigSendType" SG_ 1392 BSL_Kuehlerlueft 3;
BA_ "GenSigAutoGenSnd" SG_ 1392 BSL_Kuehlerlueft 1;
BA_ "GenSigAutoGenDsp" SG_ 1392 BSL_Kuehlerlueft 1;
BA_ "GenSigSwitchedByIgnition" SG_ 1392 BSL_Ab_Batterie 0;
BA_ "GenSigSendType" SG_ 1392 BSL_Ab_Batterie 3;
BA_ "GenSigAutoGenSnd" SG_ 1392 BSL_Ab_Batterie 1;
BA_ "GenSigAutoGenDsp" SG_ 1392 BSL_Ab_Batterie 1;
BA_ "GenSigSwitchedByIgnition" SG_ 1392 BSL_Weckursache_ACAN 0;
BA_ "GenSigSendType" SG_ 1392 BSL_Weckursache_ACAN 0;
BA_ "GenSigAutoGenSnd" SG_ 1392 BSL_Weckursache_ACAN 1;
BA_ "GenSigAutoGenDsp" SG_ 1392 BSL_Weckursache_ACAN 1;
BA_ "GenSigSwitchedByIgnition" SG_ 1392 BSL_Wake_Up_ACAN 0;
BA_ "GenSigSendType" SG_ 1392 BSL_Wake_Up_ACAN 0;
BA_ "GenSigAutoGenSnd" SG_ 1392 BSL_Wake_Up_ACAN 1;
BA_ "GenSigAutoGenDsp" SG_ 1392 BSL_Wake_Up_ACAN 1;
BA_ "GenSigSwitchedByIgnition" SG_ 1392 BSL_Starterlaubnis 0;
BA_ "GenSigSendType" SG_ 1392 BSL_Starterlaubnis 3;
BA_ "GenSigAutoGenSnd" SG_ 1392 BSL_Starterlaubnis 1;
BA_ "GenSigAutoGenDsp" SG_ 1392 BSL_Starterlaubnis 1;
BA_ "GenSigSwitchedByIgnition" SG_ 1528 Module_ID_5 0;
BA_ "GenSigSendType" SG_ 1528 Module_ID_5 6;
BA_ "GenSigAutoGenSnd" SG_ 1528 Module_ID_5 1;
BA_ "GenSigAutoGenDsp" SG_ 1528 Module_ID_5 1;
BA_ "GenSigSwitchedByIgnition" SG_ 1528 Update_Indikator_5 0;
BA_ "GenSigSendType" SG_ 1528 Update_Indikator_5 6;
BA_ "GenSigAutoGenSnd" SG_ 1528 Update_Indikator_5 1;
BA_ "GenSigAutoGenDsp" SG_ 1528 Update_Indikator_5 1;
BA_ "GenSigSwitchedByIgnition" SG_ 1528 Funktions_ID_5 0;
BA_ "GenSigSendType" SG_ 1528 Funktions_ID_5 6;
BA_ "GenSigAutoGenSnd" SG_ 1528 Funktions_ID_5 1;
BA_ "GenSigAutoGenDsp" SG_ 1528 Funktions_ID_5 1;
BA_ "GenSigSwitchedByIgnition" SG_ 1528 OpCode_5 0;
BA_ "GenSigSendType" SG_ 1528 OpCode_5 6;
BA_ "GenSigAutoGenSnd" SG_ 1528 OpCode_5 1;
BA_ "GenSigAutoGenDsp" SG_ 1528 OpCode_5 1;
BA_ "GenSigSwitchedByIgnition" SG_ 1528 Controller_ID_5 0;
BA_ "GenSigSendType" SG_ 1528 Controller_ID_5 6;
BA_ "GenSigAutoGenSnd" SG_ 1528 Controller_ID_5 1;
BA_ "GenSigAutoGenDsp" SG_ 1528 Controller_ID_5 1;
BA_ "GenSigSwitchedByIgnition" SG_ 1528 Data_Byte_1_5 0;
BA_ "GenSigSendType" SG_ 1528 Data_Byte_1_5 6;
BA_ "GenSigAutoGenSnd" SG_ 1528 Data_Byte_1_5 1;
BA_ "GenSigAutoGenDsp" SG_ 1528 Data_Byte_1_5 1;
BA_ "GenSigSwitchedByIgnition" SG_ 1528 Data_Byte_2_5 0;
BA_ "GenSigSendType" SG_ 1528 Data_Byte_2_5 6;
BA_ "GenSigAutoGenSnd" SG_ 1528 Data_Byte_2_5 1;
BA_ "GenSigAutoGenDsp" SG_ 1528 Data_Byte_2_5 1;
BA_ "GenSigSwitchedByIgnition" SG_ 1528 Data_Byte_3_5 0;
BA_ "GenSigSendType" SG_ 1528 Data_Byte_3_5 6;
BA_ "GenSigAutoGenSnd" SG_ 1528 Data_Byte_3_5 1;
BA_ "GenSigAutoGenDsp" SG_ 1528 Data_Byte_3_5 1;
BA_ "GenSigSwitchedByIgnition" SG_ 1528 Data_Byte_4_5 0;
BA_ "GenSigSendType" SG_ 1528 Data_Byte_4_5 6;
BA_ "GenSigAutoGenSnd" SG_ 1528 Data_Byte_4_5 1;
BA_ "GenSigAutoGenDsp" SG_ 1528 Data_Byte_4_5 1;
BA_ "GenSigSwitchedByIgnition" SG_ 1528 Data_Byte_5_5 0;
BA_ "GenSigSendType" SG_ 1528 Data_Byte_5_5 6;
BA_ "GenSigAutoGenSnd" SG_ 1528 Data_Byte_5_5 1;
BA_ "GenSigAutoGenDsp" SG_ 1528 Data_Byte_5_5 1;
BA_ "GenSigSwitchedByIgnition" SG_ 1530 Module_ID_19 0;
BA_ "GenSigSendType" SG_ 1530 Module_ID_19 6;
BA_ "GenSigAutoGenSnd" SG_ 1530 Module_ID_19 1;
BA_ "GenSigAutoGenDsp" SG_ 1530 Module_ID_19 1;
BA_ "GenSigSwitchedByIgnition" SG_ 1530 Update_Indikator_19 0;
BA_ "GenSigSendType" SG_ 1530 Update_Indikator_19 6;
BA_ "GenSigAutoGenSnd" SG_ 1530 Update_Indikator_19 1;
BA_ "GenSigAutoGenDsp" SG_ 1530 Update_Indikator_19 1;
BA_ "GenSigSwitchedByIgnition" SG_ 1530 Funktions_ID_19 0;
BA_ "GenSigSendType" SG_ 1530 Funktions_ID_19 6;
BA_ "GenSigAutoGenSnd" SG_ 1530 Funktions_ID_19 1;
BA_ "GenSigAutoGenDsp" SG_ 1530 Funktions_ID_19 1;
BA_ "GenSigSwitchedByIgnition" SG_ 1530 OpCode_19 0;
BA_ "GenSigSendType" SG_ 1530 OpCode_19 6;
BA_ "GenSigAutoGenSnd" SG_ 1530 OpCode_19 1;
BA_ "GenSigAutoGenDsp" SG_ 1530 OpCode_19 1;
BA_ "GenSigSwitchedByIgnition" SG_ 1530 Controller_ID_19 0;
BA_ "GenSigSendType" SG_ 1530 Controller_ID_19 6;
BA_ "GenSigAutoGenSnd" SG_ 1530 Controller_ID_19 1;
BA_ "GenSigAutoGenDsp" SG_ 1530 Controller_ID_19 1;
BA_ "GenSigSwitchedByIgnition" SG_ 1530 Data_Byte_1_19 0;
BA_ "GenSigSendType" SG_ 1530 Data_Byte_1_19 6;
BA_ "GenSigAutoGenSnd" SG_ 1530 Data_Byte_1_19 1;
BA_ "GenSigAutoGenDsp" SG_ 1530 Data_Byte_1_19 1;
BA_ "GenSigSwitchedByIgnition" SG_ 1530 Data_Byte_2_19 0;
BA_ "GenSigSendType" SG_ 1530 Data_Byte_2_19 6;
BA_ "GenSigAutoGenSnd" SG_ 1530 Data_Byte_2_19 1;
BA_ "GenSigAutoGenDsp" SG_ 1530 Data_Byte_2_19 1;
BA_ "GenSigSwitchedByIgnition" SG_ 1530 Data_Byte_3_19 0;
BA_ "GenSigSendType" SG_ 1530 Data_Byte_3_19 6;
BA_ "GenSigAutoGenSnd" SG_ 1530 Data_Byte_3_19 1;
BA_ "GenSigAutoGenDsp" SG_ 1530 Data_Byte_3_19 1;
BA_ "GenSigSwitchedByIgnition" SG_ 1530 Data_Byte_4_19 0;
BA_ "GenSigSendType" SG_ 1530 Data_Byte_4_19 6;
BA_ "GenSigAutoGenSnd" SG_ 1530 Data_Byte_4_19 1;
BA_ "GenSigAutoGenDsp" SG_ 1530 Data_Byte_4_19 1;
BA_ "GenSigSwitchedByIgnition" SG_ 1530 Data_Byte_5_19 0;
BA_ "GenSigSendType" SG_ 1530 Data_Byte_5_19 6;
BA_ "GenSigAutoGenSnd" SG_ 1530 Data_Byte_5_19 1;
BA_ "GenSigAutoGenDsp" SG_ 1530 Data_Byte_5_19 1;
BA_ "GenSigSwitchedByIgnition" SG_ 1504 CL1_LL_Dz 0;
BA_ "GenSigSendType" SG_ 1504 CL1_LL_Dz 3;
BA_ "GenSigAutoGenSnd" SG_ 1504 CL1_LL_Dz 1;
BA_ "GenSigAutoGenDsp" SG_ 1504 CL1_LL_Dz 1;
BA_ "GenSigSwitchedByIgnition" SG_ 1504 CL1_Fa_Zuheiz 0;
BA_ "GenSigSendType" SG_ 1504 CL1_Fa_Zuheiz 3;
BA_ "GenSigAutoGenSnd" SG_ 1504 CL1_Fa_Zuheiz 1;
BA_ "GenSigAutoGenDsp" SG_ 1504 CL1_Fa_Zuheiz 1;
BA_ "GenSigSwitchedByIgnition" SG_ 1504 CL1_Hecksch 0;
BA_ "GenSigSendType" SG_ 1504 CL1_Hecksch 3;
BA_ "GenSigAutoGenSnd" SG_ 1504 CL1_Hecksch 1;
BA_ "GenSigAutoGenDsp" SG_ 1504 CL1_Hecksch 1;
BA_ "GenSigSwitchedByIgnition" SG_ 1504 CL1_Frontsch 0;
BA_ "GenSigSendType" SG_ 1504 CL1_Frontsch 3;
BA_ "GenSigAutoGenSnd" SG_ 1504 CL1_Frontsch 1;
BA_ "GenSigAutoGenDsp" SG_ 1504 CL1_Frontsch 1;
BA_ "GenSigSwitchedByIgnition" SG_ 1504 CL1_Kompressor 0;
BA_ "GenSigSendType" SG_ 1504 CL1_Kompressor 3;
BA_ "GenSigAutoGenSnd" SG_ 1504 CL1_Kompressor 1;
BA_ "GenSigAutoGenDsp" SG_ 1504 CL1_Kompressor 1;
BA_ "GenSigSwitchedByIgnition" SG_ 1504 CL1_Heizleist 0;
BA_ "GenSigSendType" SG_ 1504 CL1_Heizleist 3;
BA_ "GenSigAutoGenSnd" SG_ 1504 CL1_Heizleist 1;
BA_ "GenSigAutoGenDsp" SG_ 1504 CL1_Heizleist 1;
BA_ "GenSigSwitchedByIgnition" SG_ 1504 CL1_Sta_Moment 0;
BA_ "GenSigStartValue" SG_ 1504 CL1_Sta_Moment 1;
BA_ "GenSigSendType" SG_ 1504 CL1_Sta_Moment 3;
BA_ "GenSigAutoGenSnd" SG_ 1504 CL1_Sta_Moment 1;
BA_ "GenSigAutoGenDsp" SG_ 1504 CL1_Sta_Moment 1;
BA_ "GenSigSwitchedByIgnition" SG_ 1504 CL1_Sta_Druck 0;
BA_ "GenSigStartValue" SG_ 1504 CL1_Sta_Druck 1;
BA_ "GenSigSendType" SG_ 1504 CL1_Sta_Druck 3;
BA_ "GenSigAutoGenSnd" SG_ 1504 CL1_Sta_Druck 1;
BA_ "GenSigAutoGenDsp" SG_ 1504 CL1_Sta_Druck 1;
BA_ "Fehlerwert" SG_ 1504 CL1_Aussentemp 255;
BA_ "GenSigSwitchedByIgnition" SG_ 1504 CL1_Aussentemp 0;
BA_ "GenSigSendType" SG_ 1504 CL1_Aussentemp 0;
BA_ "GenSigAutoGenSnd" SG_ 1504 CL1_Aussentemp 1;
BA_ "GenSigAutoGenDsp" SG_ 1504 CL1_Aussentemp 1;
BA_ "Fehlerwert" SG_ 1504 CL1_Druck 255;
BA_ "GenSigSwitchedByIgnition" SG_ 1504 CL1_Druck 0;
BA_ "GenSigStartValue" SG_ 1504 CL1_Druck 255;
BA_ "GenSigSendType" SG_ 1504 CL1_Druck 0;
BA_ "GenSigAutoGenSnd" SG_ 1504 CL1_Druck 1;
BA_ "GenSigAutoGenDsp" SG_ 1504 CL1_Druck 1;
BA_ "Fehlerwert" SG_ 1504 CL1_Kompr_Last 255;
BA_ "GenSigSwitchedByIgnition" SG_ 1504 CL1_Kompr_Last 0;
BA_ "GenSigSendType" SG_ 1504 CL1_Kompr_Last 0;
BA_ "GenSigAutoGenSnd" SG_ 1504 CL1_Kompr_Last 1;
BA_ "GenSigAutoGenDsp" SG_ 1504 CL1_Kompr_Last 1;
BA_ "Fehlerwert" SG_ 1504 CL1_Gebl_last 255;
BA_ "GenSigSwitchedByIgnition" SG_ 1504 CL1_Gebl_last 0;
BA_ "GenSigSendType" SG_ 1504 CL1_Gebl_last 0;
BA_ "GenSigAutoGenSnd" SG_ 1504 CL1_Gebl_last 1;
BA_ "GenSigAutoGenDsp" SG_ 1504 CL1_Gebl_last 1;
BA_ "Fehlerwert" SG_ 1504 CL1_Luefter 255;
BA_ "GenSigSwitchedByIgnition" SG_ 1504 CL1_Luefter 0;
BA_ "GenSigSendType" SG_ 1504 CL1_Luefter 0;
BA_ "GenSigAutoGenSnd" SG_ 1504 CL1_Luefter 1;
BA_ "GenSigAutoGenDsp" SG_ 1504 CL1_Luefter 1;
BA_ "GenSigSwitchedByIgnition" SG_ 1504 CL1_Einheit_Temp 0;
BA_ "GenSigSendType" SG_ 1504 CL1_Einheit_Temp 0;
BA_ "GenSigAutoGenSnd" SG_ 1504 CL1_Einheit_Temp 1;
BA_ "GenSigAutoGenDsp" SG_ 1504 CL1_Einheit_Temp 1;
BA_ "GenSigSwitchedByIgnition" SG_ 1504 CL1_AC_Schalter 0;
BA_ "GenSigSendType" SG_ 1504 CL1_AC_Schalter 0;
BA_ "GenSigAutoGenSnd" SG_ 1504 CL1_AC_Schalter 1;
BA_ "GenSigAutoGenDsp" SG_ 1504 CL1_AC_Schalter 1;
BA_ "GenSigSwitchedByIgnition" SG_ 1504 CL1_WAPU_Zuschaltung 0;
BA_ "GenSigSendType" SG_ 1504 CL1_WAPU_Zuschaltung 0;
BA_ "GenSigAutoGenSnd" SG_ 1504 CL1_WAPU_Zuschaltung 1;
BA_ "GenSigAutoGenDsp" SG_ 1504 CL1_WAPU_Zuschaltung 1;
BA_ "GenSigSwitchedByIgnition" SG_ 1504 CL1_Restwaerme 0;
BA_ "GenSigSendType" SG_ 1504 CL1_Restwaerme 0;
BA_ "GenSigAutoGenSnd" SG_ 1504 CL1_Restwaerme 1;
BA_ "GenSigAutoGenDsp" SG_ 1504 CL1_Restwaerme 1;
BA_ "GenSigSwitchedByIgnition" SG_ 1504 CL1_PTC_Hzg 0;
BA_ "GenSigSendType" SG_ 1504 CL1_PTC_Hzg 0;
BA_ "GenSigAutoGenSnd" SG_ 1504 CL1_PTC_Hzg 1;
BA_ "GenSigAutoGenDsp" SG_ 1504 CL1_PTC_Hzg 1;
BA_ "GenSigSwitchedByIgnition" SG_ 1504 CL1_Fehlereintr 0;
BA_ "GenSigSendType" SG_ 1504 CL1_Fehlereintr 0;
BA_ "GenSigAutoGenSnd" SG_ 1504 CL1_Fehlereintr 1;
BA_ "GenSigAutoGenDsp" SG_ 1504 CL1_Fehlereintr 1;
BA_ "GenSigSwitchedByIgnition" SG_ 1504 KL_Thermomanagement 0;
BA_ "GenSigSendType" SG_ 1504 KL_Thermomanagement 0;
BA_ "GenSigAutoGenSnd" SG_ 1504 KL_Thermomanagement 1;
BA_ "GenSigAutoGenDsp" SG_ 1504 KL_Thermomanagement 1;
BA_ "GenSigSendType" SG_ 1432 DA1_Daempferreg 0;
BA_ "GenSigAutoGenSnd" SG_ 1432 DA1_Daempferreg 1;
BA_ "GenSigAutoGenDsp" SG_ 1432 DA1_Daempferreg 1;
BA_ "GenSigSendType" SG_ 1432 DA1_Warnlampe 0;
BA_ "GenSigAutoGenSnd" SG_ 1432 DA1_Warnlampe 1;
BA_ "GenSigAutoGenDsp" SG_ 1432 DA1_Warnlampe 1;
BA_ "GenSigSendType" SG_ 1432 DA1_Taster 0;
BA_ "GenSigAutoGenSnd" SG_ 1432 DA1_Taster 1;
BA_ "GenSigAutoGenDsp" SG_ 1432 DA1_Taster 1;
BA_ "GenSigSendType" SG_ 1432 DA1_Systemstatus 0;
BA_ "GenSigAutoGenSnd" SG_ 1432 DA1_Systemstatus 1;
BA_ "GenSigAutoGenDsp" SG_ 1432 DA1_Systemstatus 1;
BA_ "GenSigSendType" SG_ 1432 DA1_Fehlereintr 0;
BA_ "GenSigAutoGenSnd" SG_ 1432 DA1_Fehlereintr 1;
BA_ "GenSigAutoGenDsp" SG_ 1432 DA1_Fehlereintr 1;
BA_ "GenSigSendType" SG_ 1432 DA1_Textbits 0;
BA_ "GenSigAutoGenSnd" SG_ 1432 DA1_Textbits 1;
BA_ "GenSigAutoGenDsp" SG_ 1432 DA1_Textbits 1;
BA_ "GenSigFuncType" SG_ 1432 DA1_Zaehler 1;
BA_ "GenSigSendType" SG_ 1432 DA1_Zaehler 0;
BA_ "GenSigAutoGenSnd" SG_ 1432 DA1_Zaehler 1;
BA_ "GenSigAutoGenDsp" SG_ 1432 DA1_Zaehler 1;
BA_ "GenSigSendType" SG_ 1432 DA1_ESP_Zwang 0;
BA_ "GenSigAutoGenSnd" SG_ 1432 DA1_ESP_Zwang 1;
BA_ "GenSigAutoGenDsp" SG_ 1432 DA1_ESP_Zwang 1;
BA_ "GenSigSendType" SG_ 1432 DA1_LampPruef 0;
BA_ "GenSigAutoGenSnd" SG_ 1432 DA1_LampPruef 1;
BA_ "GenSigAutoGenDsp" SG_ 1432 DA1_LampPruef 1;
BA_ "GenSigSendType" SG_ 1432 DA1_Charisma 0;
BA_ "GenSigAutoGenSnd" SG_ 1432 DA1_Charisma 1;
BA_ "GenSigAutoGenDsp" SG_ 1432 DA1_Charisma 1;
BA_ "GenSigFuncType" SG_ 1432 DA1_Checksumme 4;
BA_ "GenSigSendType" SG_ 1432 DA1_Checksumme 0;
BA_ "GenSigAutoGenSnd" SG_ 1432 DA1_Checksumme 1;
BA_ "GenSigAutoGenDsp" SG_ 1432 DA1_Checksumme 1;
BA_ "Fehlerwert" SG_ 2000 DI1_VerlernZaehl 255;
BA_ "GenSigSwitchedByIgnition" SG_ 2000 DI1_VerlernZaehl 0;
BA_ "GenSigSendType" SG_ 2000 DI1_VerlernZaehl 0;
BA_ "GenSigAutoGenSnd" SG_ 2000 DI1_VerlernZaehl 1;
BA_ "GenSigAutoGenDsp" SG_ 2000 DI1_VerlernZaehl 1;
BA_ "GenSigSwitchedByIgnition" SG_ 2000 DI1_km_Stand 0;
BA_ "GenSigSendType" SG_ 2000 DI1_km_Stand 0;
BA_ "GenSigAutoGenSnd" SG_ 2000 DI1_km_Stand 1;
BA_ "GenSigAutoGenDsp" SG_ 2000 DI1_km_Stand 1;
BA_ "GenSigSwitchedByIgnition" SG_ 2000 DI1_Jahr 0;
BA_ "GenSigSendType" SG_ 2000 DI1_Jahr 0;
BA_ "GenSigAutoGenSnd" SG_ 2000 DI1_Jahr 1;
BA_ "GenSigAutoGenDsp" SG_ 2000 DI1_Jahr 1;
BA_ "GenSigSwitchedByIgnition" SG_ 2000 DI1_Monat 0;
BA_ "GenSigSendType" SG_ 2000 DI1_Monat 0;
BA_ "GenSigAutoGenSnd" SG_ 2000 DI1_Monat 1;
BA_ "GenSigAutoGenDsp" SG_ 2000 DI1_Monat 1;
BA_ "GenSigSwitchedByIgnition" SG_ 2000 DI1_Tag 0;
BA_ "GenSigSendType" SG_ 2000 DI1_Tag 0;
BA_ "GenSigAutoGenSnd" SG_ 2000 DI1_Tag 1;
BA_ "GenSigAutoGenDsp" SG_ 2000 DI1_Tag 1;
BA_ "GenSigSwitchedByIgnition" SG_ 2000 DI1_Stunde 0;
BA_ "GenSigSendType" SG_ 2000 DI1_Stunde 0;
BA_ "GenSigAutoGenSnd" SG_ 2000 DI1_Stunde 1;
BA_ "GenSigAutoGenDsp" SG_ 2000 DI1_Stunde 1;
BA_ "GenSigSwitchedByIgnition" SG_ 2000 DI1_Minute 0;
BA_ "GenSigSendType" SG_ 2000 DI1_Minute 0;
BA_ "GenSigAutoGenSnd" SG_ 2000 DI1_Minute 1;
BA_ "GenSigAutoGenDsp" SG_ 2000 DI1_Minute 1;
BA_ "GenSigSwitchedByIgnition" SG_ 2000 DI1_Sekunde 0;
BA_ "GenSigSendType" SG_ 2000 DI1_Sekunde 0;
BA_ "GenSigAutoGenSnd" SG_ 2000 DI1_Sekunde 1;
BA_ "GenSigAutoGenDsp" SG_ 2000 DI1_Sekunde 1;
BA_ "GenSigSwitchedByIgnition" SG_ 2000 DI1_KM_Stand_alt 0;
BA_ "GenSigFuncType" SG_ 2000 DI1_KM_Stand_alt 5;
BA_ "GenSigStartValue" SG_ 2000 DI1_KM_Stand_alt 1;
BA_ "GenSigSendType" SG_ 2000 DI1_KM_Stand_alt 0;
BA_ "GenSigAutoGenSnd" SG_ 2000 DI1_KM_Stand_alt 1;
BA_ "GenSigAutoGenDsp" SG_ 2000 DI1_KM_Stand_alt 1;
BA_ "GenSigSwitchedByIgnition" SG_ 2000 DI1_Zeit_alt 0;
BA_ "GenSigFuncType" SG_ 2000 DI1_Zeit_alt 5;
BA_ "GenSigStartValue" SG_ 2000 DI1_Zeit_alt 1;
BA_ "GenSigSendType" SG_ 2000 DI1_Zeit_alt 0;
BA_ "GenSigAutoGenSnd" SG_ 2000 DI1_Zeit_alt 1;
BA_ "GenSigAutoGenDsp" SG_ 2000 DI1_Zeit_alt 1;
BA_ "GenSigSwitchedByIgnition" SG_ 1562 Ladestecker_gesteckt 0;
BA_ "GenSigSendType" SG_ 1562 Ladestecker_gesteckt 0;
BA_ "GenSigSwitchedByIgnition" SG_ 1562 Ladevorgang_aktiv 0;
BA_ "GenSigSendType" SG_ 1562 Ladevorgang_aktiv 3;
BA_ "GenSigSwitchedByIgnition" SG_ 1562 HV_Bordnetz_aktiv 0;
BA_ "GenSigSendType" SG_ 1562 HV_Bordnetz_aktiv 0;
BA_ "GenSigSwitchedByIgnition" SG_ 1562 HV_Bordnetz_A_Status 0;
BA_ "GenSigSendType" SG_ 1562 HV_Bordnetz_A_Status 3;
BA_ "GenSigSwitchedByIgnition" SG_ 1562 HV_PTC_LeistRed 0;
BA_ "GenSigSendType" SG_ 1562 HV_PTC_LeistRed 0;
BA_ "GenSigSwitchedByIgnition" SG_ 1562 HV_PTC_aus 0;
BA_ "GenSigSendType" SG_ 1562 HV_PTC_aus 0;
BA_ "Fehlerwert" SG_ 1562 Ladestecker_verr_Status 3;
BA_ "GenSigSwitchedByIgnition" SG_ 1562 Ladestecker_verr_Status 0;
BA_ "GenSigSendType" SG_ 1562 Ladestecker_verr_Status 0;
BA_ "Fehlerwert" SG_ 1576 Energieinhalt_HV_Batt 511;
BA_ "GenSigSwitchedByIgnition" SG_ 1576 Energieinhalt_HV_Batt 0;
BA_ "GenSigStartValue" SG_ 1576 Energieinhalt_HV_Batt 510;
BA_ "GenSigSendType" SG_ 1576 Energieinhalt_HV_Batt 0;
BA_ "Fehlerwert" SG_ 1576 Ladezustand_HV_Batterie 255;
BA_ "GenSigSwitchedByIgnition" SG_ 1576 Ladezustand_HV_Batterie 0;
BA_ "GenSigSendType" SG_ 1576 Ladezustand_HV_Batterie 0;
BA_ "GenSigSwitchedByIgnition" SG_ 1576 Stromnetz_vorhanden 0;
BA_ "GenSigSendType" SG_ 1576 Stromnetz_vorhanden 0;
BA_ "GenSigSwitchedByIgnition" SG_ 1576 BMS_Temperierung_Anf 0;
BA_ "GenSigStartValue" SG_ 1576 BMS_Temperierung_Anf 3;
BA_ "GenSigSendType" SG_ 1576 BMS_Temperierung_Anf 0;
BA_REL_ "GenSigTimeoutTime" BU_SG_REL_ EPB_TRW_VW411CS SG_ 1463 B11_HydHalten 1000;
BA_REL_ "GenSigTimeoutTime" BU_SG_REL_ Getriebe_DQ SG_ 1463 B11_HydHalten 1000;
BA_REL_ "GenSigTimeoutTime" BU_SG_REL_ Getriebe_DQ_Hyb SG_ 1463 B11_HydHalten 1000;
BA_REL_ "GenSigTimeoutTime" BU_SG_REL_ Motor_Diesel SG_ 1463 B11_HydHalten 1000;
BA_REL_ "GenSigTimeoutTime" BU_SG_REL_ Motor_Diesel SG_ 1463 B11_HydHalten 1000;
BA_REL_ "GenSigTimeoutTime" BU_SG_REL_ Motor_Otto SG_ 1463 B11_HydHalten 1000;
BA_REL_ "GenSigTimeoutTime" BU_SG_REL_ PDC_PLA SG_ 1463 B11_HydHalten 1000;
BA_REL_ "GenSigTimeoutTime" BU_SG_REL_ EPB_TRW_VW411CS SG_ 1463 B11_Br_StSt_Info 1000;
BA_REL_ "GenSigTimeoutTime" BU_SG_REL_ Motor_Diesel SG_ 1463 B11_Br_StSt_Info 1000;
BA_REL_ "GenSigTimeoutTime" BU_SG_REL_ Motor_Diesel SG_ 1463 B11_Br_StSt_Info 1000;
BA_REL_ "GenSigTimeoutTime" BU_SG_REL_ Motor_Otto SG_ 1463 B11_Br_StSt_Info 1000;
BA_REL_ "GenSigTimeoutTime" BU_SG_REL_ Motor_Diesel SG_ 1463 B11_OBD_Nib_VL 1000;
BA_REL_ "GenSigTimeoutTime" BU_SG_REL_ Motor_Otto SG_ 1463 B11_OBD_Nib_VL 1000;
BA_REL_ "GenSigTimeoutTime" BU_SG_REL_ Motor_Diesel SG_ 1463 B11_OBD_Nib_VR 1000;
BA_REL_ "GenSigTimeoutTime" BU_SG_REL_ Motor_Otto SG_ 1463 B11_OBD_Nib_VR 1000;
BA_REL_ "GenSigTimeoutTime" BU_SG_REL_ Motor_Diesel SG_ 1463 B11_OBD_Nib_HL 1000;
BA_REL_ "GenSigTimeoutTime" BU_SG_REL_ Motor_Otto SG_ 1463 B11_OBD_Nib_HL 1000;
BA_REL_ "GenSigTimeoutTime" BU_SG_REL_ Motor_Diesel SG_ 1463 B11_OBD_Nib_HR 1000;
BA_REL_ "GenSigTimeoutTime" BU_SG_REL_ Motor_Otto SG_ 1463 B11_OBD_Nib_HR 1000;
BA_REL_ "GenSigTimeoutTime" BU_SG_REL_ Motor_Diesel SG_ 1463 B11_EPB_Steller_akt 1000;
BA_REL_ "GenSigTimeoutTime" BU_SG_REL_ Motor_Diesel SG_ 1463 B11_EPB_Steller_akt 1000;
BA_REL_ "GenSigTimeoutTime" BU_SG_REL_ Motor_Otto SG_ 1463 B11_EPB_Steller_akt 1000;
BA_REL_ "GenSigTimeoutTime" BU_SG_REL_ Motor_Otto SG_ 1463 B11_EPB_Steller_akt 1000;
BA_REL_ "GenSigTimeoutTime" BU_SG_REL_ Motor_Diesel SG_ 1463 B11_EPB_Steller_gue 1000;
BA_REL_ "GenSigTimeoutTime" BU_SG_REL_ Motor_Diesel SG_ 1463 B11_EPB_Steller_gue 1000;
BA_REL_ "GenSigTimeoutTime" BU_SG_REL_ Motor_Otto SG_ 1463 B11_EPB_Steller_gue 1000;
BA_REL_ "GenSigTimeoutTime" BU_SG_REL_ Motor_Otto SG_ 1463 B11_EPB_Steller_gue 1000;
BA_REL_ "GenSigTimeoutTime" BU_SG_REL_ AFS SG_ 1440 BR2_Querbeschl 500;
BA_REL_ "GenSigTimeoutTime" BU_SG_REL_ Allrad SG_ 1440 BR2_Querbeschl 500;
BA_REL_ "GenSigTimeoutTime" BU_SG_REL_ Daempfer SG_ 1440 BR2_Querbeschl 500;
BA_REL_ "GenSigTimeoutTime" BU_SG_REL_ Gateway_PQ35 SG_ 1440 BR2_Querbeschl 500;
BA_REL_ "GenSigTimeoutTime" BU_SG_REL_ Gateway_PQ35 SG_ 1440 BR2_Querbeschl 500;
BA_REL_ "GenSigTimeoutTime" BU_SG_REL_ Getriebe_DQ SG_ 1440 BR2_Querbeschl 500;
BA_REL_ "GenSigTimeoutTime" BU_SG_REL_ Getriebe_DQ_Hyb SG_ 1440 BR2_Querbeschl 500;
BA_REL_ "GenSigTimeoutTime" BU_SG_REL_ Getriebe_Sele SG_ 1440 BR2_Querbeschl 500;
BA_REL_ "GenSigTimeoutTime" BU_SG_REL_ HCA SG_ 1440 BR2_Querbeschl 500;
BA_REL_ "GenSigTimeoutTime" BU_SG_REL_ LWR SG_ 1440 BR2_Querbeschl 500;
BA_REL_ "GenSigTimeoutTime" BU_SG_REL_ Magne_Ride SG_ 1440 BR2_Querbeschl 500;
BA_REL_ "GenSigTimeoutTime" BU_SG_REL_ Motor_Diesel SG_ 1440 BR2_Querbeschl 500;
BA_REL_ "GenSigTimeoutTime" BU_SG_REL_ Motor_Otto SG_ 1440 BR2_Querbeschl 500;
BA_REL_ "GenSigTimeoutTime" BU_SG_REL_ RKA_Plus SG_ 1440 BR2_Querbeschl 500;
BA_REL_ "GenSigTimeoutTime" BU_SG_REL_ Getriebe_DQ SG_ 1440 BR2_Zahnzahl 500;
BA_REL_ "GenSigTimeoutTime" BU_SG_REL_ Getriebe_DQ_Hyb SG_ 1440 BR2_Zahnzahl 500;
BA_REL_ "GenSigTimeoutTime" BU_SG_REL_ PDC_PLA SG_ 1440 BR2_Zahnzahl 500;
BA_REL_ "GenSigTimeoutTime" BU_SG_REL_ RKA_Plus SG_ 1440 BR2_Zahnzahl 500;
BA_REL_ "GenSigTimeoutTime" BU_SG_REL_ AFS SG_ 1440 BR2_Querb_Zahn 500;
BA_REL_ "GenSigTimeoutTime" BU_SG_REL_ Allrad SG_ 1440 BR2_Querb_Zahn 500;
BA_REL_ "GenSigTimeoutTime" BU_SG_REL_ Daempfer SG_ 1440 BR2_Querb_Zahn 500;
BA_REL_ "GenSigTimeoutTime" BU_SG_REL_ Gateway_PQ35 SG_ 1440 BR2_Querb_Zahn 500;
BA_REL_ "GenSigTimeoutTime" BU_SG_REL_ Gateway_PQ35 SG_ 1440 BR2_Querb_Zahn 500;
BA_REL_ "GenSigTimeoutTime" BU_SG_REL_ Getriebe_DQ SG_ 1440 BR2_Querb_Zahn 500;
BA_REL_ "GenSigTimeoutTime" BU_SG_REL_ Getriebe_DQ_Hyb SG_ 1440 BR2_Querb_Zahn 500;
BA_REL_ "GenSigTimeoutTime" BU_SG_REL_ Getriebe_Sele SG_ 1440 BR2_Querb_Zahn 500;
BA_REL_ "GenSigTimeoutTime" BU_SG_REL_ HCA SG_ 1440 BR2_Querb_Zahn 500;
BA_REL_ "GenSigTimeoutTime" BU_SG_REL_ LWR SG_ 1440 BR2_Querb_Zahn 500;
BA_REL_ "GenSigTimeoutTime" BU_SG_REL_ Magne_Ride SG_ 1440 BR2_Querb_Zahn 500;
BA_REL_ "GenSigTimeoutTime" BU_SG_REL_ Motor_Diesel SG_ 1440 BR2_Querb_Zahn 500;
BA_REL_ "GenSigTimeoutTime" BU_SG_REL_ Motor_Otto SG_ 1440 BR2_Querb_Zahn 500;
BA_REL_ "GenSigTimeoutTime" BU_SG_REL_ PDC_PLA SG_ 1440 BR2_Querb_Zahn 500;
BA_REL_ "GenSigTimeoutTime" BU_SG_REL_ RKA_Plus SG_ 1440 BR2_Querb_Zahn 500;
BA_REL_ "GenSigTimeoutTime" BU_SG_REL_ Getriebe_DQ SG_ 1440 BR2_mi_Radgeschw 500;
BA_REL_ "GenSigTimeoutTime" BU_SG_REL_ Getriebe_DQ_Hyb SG_ 1440 BR2_mi_Radgeschw 500;
BA_REL_ "GenSigTimeoutTime" BU_SG_REL_ Airbag SG_ 1440 BR2_Lampe_ABS 500;
BA_REL_ "GenSigTimeoutTime" BU_SG_REL_ PDC_PLA SG_ 1440 BR2_Lampe_ASR 500;
BA_REL_ "GenSigTimeoutTime" BU_SG_REL_ Daempfer SG_ 1440 BR2_Zaehler 500;
BA_REL_ "GenSigTimeoutTime" BU_SG_REL_ HCA SG_ 1440 BR2_Zaehler 500;
BA_REL_ "GenSigTimeoutTime" BU_SG_REL_ Magne_Ride SG_ 1440 BR2_Zaehler 500;
BA_REL_ "GenSigTimeoutTime" BU_SG_REL_ Getriebe_DQ SG_ 1440 BR2_HDC_aktiv 500;
BA_REL_ "GenSigTimeoutTime" BU_SG_REL_ Getriebe_DQ_Hyb SG_ 1440 BR2_HDC_aktiv 500;
BA_REL_ "GenSigTimeoutTime" BU_SG_REL_ Motor_Diesel SG_ 1440 BR2_HDC_aktiv 500;
BA_REL_ "GenSigTimeoutTime" BU_SG_REL_ Motor_Hybrid SG_ 1440 BR2_HDC_aktiv 500;
BA_REL_ "GenSigTimeoutTime" BU_SG_REL_ Motor_Otto SG_ 1440 BR2_HDC_aktiv 500;
BA_REL_ "GenSigTimeoutTime" BU_SG_REL_ Getriebe_DQ SG_ 1440 BR2_Wegimpulse 500;
BA_REL_ "GenSigTimeoutTime" BU_SG_REL_ Getriebe_DQ_Hyb SG_ 1440 BR2_Wegimpulse 500;
BA_REL_ "GenSigTimeoutTime" BU_SG_REL_ Gateway_PQ35 SG_ 1440 BR2_Fehlereintr 500;
BA_REL_ "GenSigTimeoutTime" BU_SG_REL_ Getriebe_DQ SG_ 1440 BR2_LampeHDC 500;
BA_REL_ "GenSigTimeoutTime" BU_SG_REL_ Getriebe_DQ_Hyb SG_ 1440 BR2_LampeHDC 500;
BA_REL_ "GenSigTimeoutTime" BU_SG_REL_ AFS SG_ 1440 BR2_QB_Querbeschl 500;
BA_REL_ "GenSigTimeoutTime" BU_SG_REL_ Allrad SG_ 1440 BR2_QB_Querbeschl 500;
BA_REL_ "GenSigTimeoutTime" BU_SG_REL_ Gateway_PQ35 SG_ 1440 BR2_QB_Querbeschl 500;
BA_REL_ "GenSigTimeoutTime" BU_SG_REL_ HCA SG_ 1440 BR2_QB_Querbeschl 500;
BA_REL_ "GenSigTimeoutTime" BU_SG_REL_ LWR SG_ 1440 BR2_QB_Querbeschl 500;
BA_REL_ "GenSigTimeoutTime" BU_SG_REL_ Magne_Ride SG_ 1440 BR2_QB_Querbeschl 500;
BA_REL_ "GenSigTimeoutTime" BU_SG_REL_ Motor_Diesel SG_ 1440 BR2_QB_Querbeschl 500;
BA_REL_ "GenSigTimeoutTime" BU_SG_REL_ Motor_Otto SG_ 1440 BR2_QB_Querbeschl 500;
BA_REL_ "GenSigTimeoutTime" BU_SG_REL_ RKA_Plus SG_ 1440 BR2_QB_Querbeschl 500;
BA_REL_ "GenSigTimeoutTime" BU_SG_REL_ Getriebe_DQ SG_ 1440 BR2_Impulszahl 500;
BA_REL_ "GenSigTimeoutTime" BU_SG_REL_ Getriebe_DQ_Hyb SG_ 1440 BR2_Impulszahl 500;
BA_REL_ "GenSigTimeoutTime" BU_SG_REL_ Gateway_PQ35 SG_ 1440 BR2_SleepInd 500;
BA_REL_ "GenSigTimeoutTime" BU_SG_REL_ Getriebe_DQ SG_ 1440 BR2_Sta_Quer 500;
BA_REL_ "GenSigTimeoutTime" BU_SG_REL_ Getriebe_DQ_Hyb SG_ 1440 BR2_Sta_Quer 500;
BA_REL_ "GenSigTimeoutTime" BU_SG_REL_ AFS SG_ 1184 BR3_Fahrtr_VL 500;
BA_REL_ "GenSigTimeoutTime" BU_SG_REL_ EPB_TRW_VW411CS SG_ 1184 BR3_Fahrtr_VL 500;
BA_REL_ "GenSigTimeoutTime" BU_SG_REL_ LWR SG_ 1184 BR3_Fahrtr_VL 500;
BA_REL_ "GenSigTimeoutTime" BU_SG_REL_ Magne_Ride SG_ 1184 BR3_Fahrtr_VL 500;
BA_REL_ "GenSigTimeoutTime" BU_SG_REL_ AFS SG_ 1184 BR3_Rad_kmh_VL 500;
BA_REL_ "GenSigTimeoutTime" BU_SG_REL_ Allrad SG_ 1184 BR3_Rad_kmh_VL 500;
BA_REL_ "GenSigTimeoutTime" BU_SG_REL_ EPB_TRW SG_ 1184 BR3_Rad_kmh_VL 500;
BA_REL_ "GenSigTimeoutTime" BU_SG_REL_ EPB_TRW_VW411CS SG_ 1184 BR3_Rad_kmh_VL 500;
BA_REL_ "GenSigTimeoutTime" BU_SG_REL_ Getriebe_AG6 SG_ 1184 BR3_Rad_kmh_VL 500;
BA_REL_ "GenSigTimeoutTime" BU_SG_REL_ Getriebe_DQ SG_ 1184 BR3_Rad_kmh_VL 500;
BA_REL_ "GenSigTimeoutTime" BU_SG_REL_ Getriebe_DQ_Hyb SG_ 1184 BR3_Rad_kmh_VL 500;
BA_REL_ "GenSigTimeoutTime" BU_SG_REL_ Getriebe_Sele SG_ 1184 BR3_Rad_kmh_VL 500;
BA_REL_ "GenSigTimeoutTime" BU_SG_REL_ LH_EPS_APA SG_ 1184 BR3_Rad_kmh_VL 500;
BA_REL_ "GenSigTimeoutTime" BU_SG_REL_ LH_EPS_ZF_2G SG_ 1184 BR3_Rad_kmh_VL 500;
BA_REL_ "GenSigTimeoutTime" BU_SG_REL_ LH_EPS_ZF_3G SG_ 1184 BR3_Rad_kmh_VL 500;
BA_REL_ "GenSigTimeoutTime" BU_SG_REL_ LWR SG_ 1184 BR3_Rad_kmh_VL 500;
BA_REL_ "GenSigTimeoutTime" BU_SG_REL_ LWS SG_ 1184 BR3_Rad_kmh_VL 500;
BA_REL_ "GenSigTimeoutTime" BU_SG_REL_ Magne_Ride SG_ 1184 BR3_Rad_kmh_VL 500;
BA_REL_ "GenSigTimeoutTime" BU_SG_REL_ Motor_Diesel SG_ 1184 BR3_Rad_kmh_VL 500;
BA_REL_ "GenSigTimeoutTime" BU_SG_REL_ Motor_Hybrid SG_ 1184 BR3_Rad_kmh_VL 500;
BA_REL_ "GenSigTimeoutTime" BU_SG_REL_ Motor_Otto SG_ 1184 BR3_Rad_kmh_VL 500;
BA_REL_ "GenSigTimeoutTime" BU_SG_REL_ PDC_PLA SG_ 1184 BR3_Rad_kmh_VL 500;
BA_REL_ "GenSigTimeoutTime" BU_SG_REL_ AFS SG_ 1184 BR3_Fahrtr_VR 500;
BA_REL_ "GenSigTimeoutTime" BU_SG_REL_ EPB_TRW_VW411CS SG_ 1184 BR3_Fahrtr_VR 500;
BA_REL_ "GenSigTimeoutTime" BU_SG_REL_ LWR SG_ 1184 BR3_Fahrtr_VR 500;
BA_REL_ "GenSigTimeoutTime" BU_SG_REL_ Magne_Ride SG_ 1184 BR3_Fahrtr_VR 500;
BA_REL_ "GenSigTimeoutTime" BU_SG_REL_ AFS SG_ 1184 BR3_Rad_kmh_VR 500;
BA_REL_ "GenSigTimeoutTime" BU_SG_REL_ Allrad SG_ 1184 BR3_Rad_kmh_VR 500;
BA_REL_ "GenSigTimeoutTime" BU_SG_REL_ EPB_TRW SG_ 1184 BR3_Rad_kmh_VR 500;
BA_REL_ "GenSigTimeoutTime" BU_SG_REL_ EPB_TRW_VW411CS SG_ 1184 BR3_Rad_kmh_VR 500;
BA_REL_ "GenSigTimeoutTime" BU_SG_REL_ Getriebe_AG6 SG_ 1184 BR3_Rad_kmh_VR 500;
BA_REL_ "GenSigTimeoutTime" BU_SG_REL_ Getriebe_DQ SG_ 1184 BR3_Rad_kmh_VR 500;
BA_REL_ "GenSigTimeoutTime" BU_SG_REL_ Getriebe_DQ_Hyb SG_ 1184 BR3_Rad_kmh_VR 500;
BA_REL_ "GenSigTimeoutTime" BU_SG_REL_ Getriebe_Sele SG_ 1184 BR3_Rad_kmh_VR 500;
BA_REL_ "GenSigTimeoutTime" BU_SG_REL_ LH_EPS_APA SG_ 1184 BR3_Rad_kmh_VR 500;
BA_REL_ "GenSigTimeoutTime" BU_SG_REL_ LH_EPS_ZF_2G SG_ 1184 BR3_Rad_kmh_VR 500;
BA_REL_ "GenSigTimeoutTime" BU_SG_REL_ LH_EPS_ZF_3G SG_ 1184 BR3_Rad_kmh_VR 500;
BA_REL_ "GenSigTimeoutTime" BU_SG_REL_ LWR SG_ 1184 BR3_Rad_kmh_VR 500;
BA_REL_ "GenSigTimeoutTime" BU_SG_REL_ LWS SG_ 1184 BR3_Rad_kmh_VR 500;
BA_REL_ "GenSigTimeoutTime" BU_SG_REL_ Magne_Ride SG_ 1184 BR3_Rad_kmh_VR 500;
BA_REL_ "GenSigTimeoutTime" BU_SG_REL_ Motor_Diesel SG_ 1184 BR3_Rad_kmh_VR 500;
BA_REL_ "GenSigTimeoutTime" BU_SG_REL_ Motor_Hybrid SG_ 1184 BR3_Rad_kmh_VR 500;
BA_REL_ "GenSigTimeoutTime" BU_SG_REL_ Motor_Otto SG_ 1184 BR3_Rad_kmh_VR 500;
BA_REL_ "GenSigTimeoutTime" BU_SG_REL_ PDC_PLA SG_ 1184 BR3_Rad_kmh_VR 500;
BA_REL_ "GenSigTimeoutTime" BU_SG_REL_ EPB_TRW_VW411CS SG_ 1184 BR3_Fahrtr_HL 500;
BA_REL_ "GenSigTimeoutTime" BU_SG_REL_ Magne_Ride SG_ 1184 BR3_Fahrtr_HL 500;
BA_REL_ "GenSigTimeoutTime" BU_SG_REL_ AFS SG_ 1184 BR3_Rad_kmh_HL 500;
BA_REL_ "GenSigTimeoutTime" BU_SG_REL_ Allrad SG_ 1184 BR3_Rad_kmh_HL 500;
BA_REL_ "GenSigTimeoutTime" BU_SG_REL_ EPB_TRW SG_ 1184 BR3_Rad_kmh_HL 500;
BA_REL_ "GenSigTimeoutTime" BU_SG_REL_ EPB_TRW_VW411CS SG_ 1184 BR3_Rad_kmh_HL 500;
BA_REL_ "GenSigTimeoutTime" BU_SG_REL_ Getriebe_AG6 SG_ 1184 BR3_Rad_kmh_HL 500;
BA_REL_ "GenSigTimeoutTime" BU_SG_REL_ Getriebe_DQ SG_ 1184 BR3_Rad_kmh_HL 500;
BA_REL_ "GenSigTimeoutTime" BU_SG_REL_ Getriebe_DQ_Hyb SG_ 1184 BR3_Rad_kmh_HL 500;
BA_REL_ "GenSigTimeoutTime" BU_SG_REL_ Getriebe_Sele SG_ 1184 BR3_Rad_kmh_HL 500;
BA_REL_ "GenSigTimeoutTime" BU_SG_REL_ LH_EPS_APA SG_ 1184 BR3_Rad_kmh_HL 500;
BA_REL_ "GenSigTimeoutTime" BU_SG_REL_ LH_EPS_ZF_2G SG_ 1184 BR3_Rad_kmh_HL 500;
BA_REL_ "GenSigTimeoutTime" BU_SG_REL_ LH_EPS_ZF_3G SG_ 1184 BR3_Rad_kmh_HL 500;
BA_REL_ "GenSigTimeoutTime" BU_SG_REL_ LWR SG_ 1184 BR3_Rad_kmh_HL 500;
BA_REL_ "GenSigTimeoutTime" BU_SG_REL_ LWS SG_ 1184 BR3_Rad_kmh_HL 500;
BA_REL_ "GenSigTimeoutTime" BU_SG_REL_ Magne_Ride SG_ 1184 BR3_Rad_kmh_HL 500;
BA_REL_ "GenSigTimeoutTime" BU_SG_REL_ Motor_Diesel SG_ 1184 BR3_Rad_kmh_HL 500;
BA_REL_ "GenSigTimeoutTime" BU_SG_REL_ Motor_Hybrid SG_ 1184 BR3_Rad_kmh_HL 500;
BA_REL_ "GenSigTimeoutTime" BU_SG_REL_ Motor_Otto SG_ 1184 BR3_Rad_kmh_HL 500;
BA_REL_ "GenSigTimeoutTime" BU_SG_REL_ PDC_PLA SG_ 1184 BR3_Rad_kmh_HL 500;
BA_REL_ "GenSigTimeoutTime" BU_SG_REL_ EPB_TRW_VW411CS SG_ 1184 BR3_Fahrtr_HR 500;
BA_REL_ "GenSigTimeoutTime" BU_SG_REL_ Magne_Ride SG_ 1184 BR3_Fahrtr_HR 500;
BA_REL_ "GenSigTimeoutTime" BU_SG_REL_ AFS SG_ 1184 BR3_Rad_kmh_HR 500;
BA_REL_ "GenSigTimeoutTime" BU_SG_REL_ Allrad SG_ 1184 BR3_Rad_kmh_HR 500;
BA_REL_ "GenSigTimeoutTime" BU_SG_REL_ EPB_TRW SG_ 1184 BR3_Rad_kmh_HR 500;
BA_REL_ "GenSigTimeoutTime" BU_SG_REL_ EPB_TRW_VW411CS SG_ 1184 BR3_Rad_kmh_HR 500;
BA_REL_ "GenSigTimeoutTime" BU_SG_REL_ Getriebe_AG6 SG_ 1184 BR3_Rad_kmh_HR 500;
BA_REL_ "GenSigTimeoutTime" BU_SG_REL_ Getriebe_DQ SG_ 1184 BR3_Rad_kmh_HR 500;
BA_REL_ "GenSigTimeoutTime" BU_SG_REL_ Getriebe_DQ_Hyb SG_ 1184 BR3_Rad_kmh_HR 500;
BA_REL_ "GenSigTimeoutTime" BU_SG_REL_ Getriebe_Sele SG_ 1184 BR3_Rad_kmh_HR 500;
BA_REL_ "GenSigTimeoutTime" BU_SG_REL_ LH_EPS_APA SG_ 1184 BR3_Rad_kmh_HR 500;
BA_REL_ "GenSigTimeoutTime" BU_SG_REL_ LH_EPS_ZF_2G SG_ 1184 BR3_Rad_kmh_HR 500;
BA_REL_ "GenSigTimeoutTime" BU_SG_REL_ LH_EPS_ZF_3G SG_ 1184 BR3_Rad_kmh_HR 500;
BA_REL_ "GenSigTimeoutTime" BU_SG_REL_ LWR SG_ 1184 BR3_Rad_kmh_HR 500;
BA_REL_ "GenSigTimeoutTime" BU_SG_REL_ LWS SG_ 1184 BR3_Rad_kmh_HR 500;
BA_REL_ "GenSigTimeoutTime" BU_SG_REL_ Magne_Ride SG_ 1184 BR3_Rad_kmh_HR 500;
BA_REL_ "GenSigTimeoutTime" BU_SG_REL_ Motor_Diesel SG_ 1184 BR3_Rad_kmh_HR 500;
BA_REL_ "GenSigTimeoutTime" BU_SG_REL_ Motor_Hybrid SG_ 1184 BR3_Rad_kmh_HR 500;
BA_REL_ "GenSigTimeoutTime" BU_SG_REL_ Motor_Otto SG_ 1184 BR3_Rad_kmh_HR 500;
BA_REL_ "GenSigTimeoutTime" BU_SG_REL_ PDC_PLA SG_ 1184 BR3_Rad_kmh_HR 500;
BA_REL_ "GenSigTimeoutTime" BU_SG_REL_ Allrad SG_ 672 BR4_Vorgabe_Mi_ 500;
BA_REL_ "GenSigTimeoutTime" BU_SG_REL_ Quersperre_VAQ SG_ 672 BR4_Vorgabe_Max 500;
BA_REL_ "GenSigTimeoutTime" BU_SG_REL_ Quersperre_VAQ SG_ 672 BR4_Vorgabe_Min 500;
BA_REL_ "GenSigTimeoutTime" BU_SG_REL_ Allrad SG_ 672 BR4_Einheit 500;
BA_REL_ "GenSigTimeoutTime" BU_SG_REL_ Quersperre_VAQ SG_ 672 BR4_Einheit 500;
BA_REL_ "GenSigTimeoutTime" BU_SG_REL_ Getriebe_AG6 SG_ 672 BR4_Schwelle 500;
BA_REL_ "GenSigTimeoutTime" BU_SG_REL_ Motor_Hybrid SG_ 672 BR4_Schwelle 500;
BA_REL_ "GenSigTimeoutTime" BU_SG_REL_ Motor_Otto SG_ 672 BR4_Schwelle 500;
BA_REL_ "GenSigTimeoutTime" BU_SG_REL_ Getriebe_AG6 SG_ 672 BR4_Unterdruck 500;
BA_REL_ "GenSigTimeoutTime" BU_SG_REL_ Motor_Hybrid SG_ 672 BR4_Unterdruck 500;
BA_REL_ "GenSigTimeoutTime" BU_SG_REL_ Motor_Otto SG_ 672 BR4_Unterdruck 500;
BA_REL_ "GenSigTimeoutTime" BU_SG_REL_ Quersperre_VAQ SG_ 672 BR4_Status_ESP 500;
BA_REL_ "GenSigTimeoutTime" BU_SG_REL_ Quersperre_VAQ SG_ 672 BR4_Zaehler 500;
BA_REL_ "GenSigTimeoutTime" BU_SG_REL_ Quersperre_VAQ SG_ 672 BR4_Checksum 500;
BA_REL_ "GenSigTimeoutTime" BU_SG_REL_ AFS SG_ 1192 BR5_Giergeschw 500;
BA_REL_ "GenSigTimeoutTime" BU_SG_REL_ Allrad SG_ 1192 BR5_Giergeschw 500;
BA_REL_ "GenSigTimeoutTime" BU_SG_REL_ Daempfer SG_ 1192 BR5_Giergeschw 500;
BA_REL_ "GenSigTimeoutTime" BU_SG_REL_ FLA SG_ 1192 BR5_Giergeschw 500;
BA_REL_ "GenSigTimeoutTime" BU_SG_REL_ Gateway_PQ35 SG_ 1192 BR5_Giergeschw 500;
BA_REL_ "GenSigTimeoutTime" BU_SG_REL_ HCA SG_ 1192 BR5_Giergeschw 500;
BA_REL_ "GenSigTimeoutTime" BU_SG_REL_ LWR SG_ 1192 BR5_Giergeschw 500;
BA_REL_ "GenSigTimeoutTime" BU_SG_REL_ Magne_Ride SG_ 1192 BR5_Giergeschw 500;
BA_REL_ "GenSigTimeoutTime" BU_SG_REL_ PDC_PLA SG_ 1192 BR5_Giergeschw 500;
BA_REL_ "GenSigTimeoutTime" BU_SG_REL_ RKA_Plus SG_ 1192 BR5_Giergeschw 500;
BA_REL_ "GenSigTimeoutTime" BU_SG_REL_ AFS SG_ 1192 BR5_Sta_Gierrate 500;
BA_REL_ "GenSigTimeoutTime" BU_SG_REL_ Allrad SG_ 1192 BR5_Sta_Gierrate 500;
BA_REL_ "GenSigTimeoutTime" BU_SG_REL_ Daempfer SG_ 1192 BR5_Sta_Gierrate 500;
BA_REL_ "GenSigTimeoutTime" BU_SG_REL_ FLA SG_ 1192 BR5_Sta_Gierrate 500;
BA_REL_ "GenSigTimeoutTime" BU_SG_REL_ Gateway_PQ35 SG_ 1192 BR5_Sta_Gierrate 500;
BA_REL_ "GenSigTimeoutTime" BU_SG_REL_ HCA SG_ 1192 BR5_Sta_Gierrate 500;
BA_REL_ "GenSigTimeoutTime" BU_SG_REL_ LWR SG_ 1192 BR5_Sta_Gierrate 500;
BA_REL_ "GenSigTimeoutTime" BU_SG_REL_ Magne_Ride SG_ 1192 BR5_Sta_Gierrate 500;
BA_REL_ "GenSigTimeoutTime" BU_SG_REL_ PDC_PLA SG_ 1192 BR5_Sta_Gierrate 500;
BA_REL_ "GenSigTimeoutTime" BU_SG_REL_ RKA_Plus SG_ 1192 BR5_Sta_Gierrate 500;
BA_REL_ "GenSigTimeoutTime" BU_SG_REL_ AFS SG_ 1192 BR5_Vorzeichen 500;
BA_REL_ "GenSigTimeoutTime" BU_SG_REL_ Allrad SG_ 1192 BR5_Vorzeichen 500;
BA_REL_ "GenSigTimeoutTime" BU_SG_REL_ Daempfer SG_ 1192 BR5_Vorzeichen 500;
BA_REL_ "GenSigTimeoutTime" BU_SG_REL_ FLA SG_ 1192 BR5_Vorzeichen 500;
BA_REL_ "GenSigTimeoutTime" BU_SG_REL_ Gateway_PQ35 SG_ 1192 BR5_Vorzeichen 500;
BA_REL_ "GenSigTimeoutTime" BU_SG_REL_ HCA SG_ 1192 BR5_Vorzeichen 500;
BA_REL_ "GenSigTimeoutTime" BU_SG_REL_ LWR SG_ 1192 BR5_Vorzeichen 500;
BA_REL_ "GenSigTimeoutTime" BU_SG_REL_ Magne_Ride SG_ 1192 BR5_Vorzeichen 500;
BA_REL_ "GenSigTimeoutTime" BU_SG_REL_ PDC_PLA SG_ 1192 BR5_Vorzeichen 500;
BA_REL_ "GenSigTimeoutTime" BU_SG_REL_ RKA_Plus SG_ 1192 BR5_Vorzeichen 500;
BA_REL_ "GenSigTimeoutTime" BU_SG_REL_ Daempfer SG_ 1192 BR5_Bremsdruck 500;
BA_REL_ "GenSigTimeoutTime" BU_SG_REL_ EPB_TRW SG_ 1192 BR5_Bremsdruck 500;
BA_REL_ "GenSigTimeoutTime" BU_SG_REL_ EPB_TRW_VW411CS SG_ 1192 BR5_Bremsdruck 500;
BA_REL_ "GenSigTimeoutTime" BU_SG_REL_ Gateway_PQ35 SG_ 1192 BR5_Bremsdruck 500;
BA_REL_ "GenSigTimeoutTime" BU_SG_REL_ Gateway_PQ35 SG_ 1192 BR5_Bremsdruck 500;
BA_REL_ "GenSigTimeoutTime" BU_SG_REL_ Getriebe_DQ SG_ 1192 BR5_Bremsdruck 500;
BA_REL_ "GenSigTimeoutTime" BU_SG_REL_ Getriebe_DQ_Hyb SG_ 1192 BR5_Bremsdruck 500;
BA_REL_ "GenSigTimeoutTime" BU_SG_REL_ HCA SG_ 1192 BR5_Bremsdruck 500;
BA_REL_ "GenSigTimeoutTime" BU_SG_REL_ Magne_Ride SG_ 1192 BR5_Bremsdruck 500;
BA_REL_ "GenSigTimeoutTime" BU_SG_REL_ Motor_Diesel SG_ 1192 BR5_Bremsdruck 500;
BA_REL_ "GenSigTimeoutTime" BU_SG_REL_ Motor_Otto SG_ 1192 BR5_Bremsdruck 500;
BA_REL_ "GenSigTimeoutTime" BU_SG_REL_ PDC_PLA SG_ 1192 BR5_Bremsdruck 500;
BA_REL_ "GenSigTimeoutTime" BU_SG_REL_ HCA SG_ 1192 BR5_Stillstand 500;
BA_REL_ "GenSigTimeoutTime" BU_SG_REL_ Magne_Ride SG_ 1192 BR5_Stillstand 500;
BA_REL_ "GenSigTimeoutTime" BU_SG_REL_ PDC_PLA SG_ 1192 BR5_Stillstand 500;
BA_REL_ "GenSigTimeoutTime" BU_SG_REL_ Daempfer SG_ 1192 BR5_Druckgueltig 500;
BA_REL_ "GenSigTimeoutTime" BU_SG_REL_ EPB_TRW SG_ 1192 BR5_Druckgueltig 500;
BA_REL_ "GenSigTimeoutTime" BU_SG_REL_ EPB_TRW_VW411CS SG_ 1192 BR5_Druckgueltig 500;
BA_REL_ "GenSigTimeoutTime" BU_SG_REL_ Gateway_PQ35 SG_ 1192 BR5_Druckgueltig 500;
BA_REL_ "GenSigTimeoutTime" BU_SG_REL_ Getriebe_DQ SG_ 1192 BR5_Druckgueltig 500;
BA_REL_ "GenSigTimeoutTime" BU_SG_REL_ Getriebe_DQ_Hyb SG_ 1192 BR5_Druckgueltig 500;
BA_REL_ "GenSigTimeoutTime" BU_SG_REL_ HCA SG_ 1192 BR5_Druckgueltig 500;
BA_REL_ "GenSigTimeoutTime" BU_SG_REL_ Magne_Ride SG_ 1192 BR5_Druckgueltig 500;
BA_REL_ "GenSigTimeoutTime" BU_SG_REL_ Motor_Diesel SG_ 1192 BR5_Druckgueltig 500;
BA_REL_ "GenSigTimeoutTime" BU_SG_REL_ Motor_Otto SG_ 1192 BR5_Druckgueltig 500;
BA_REL_ "GenSigTimeoutTime" BU_SG_REL_ PDC_PLA SG_ 1192 BR5_Druckgueltig 500;
BA_REL_ "GenSigTimeoutTime" BU_SG_REL_ EPB_TRW_VW411CS SG_ 1192 BR5_Sta_Druck 500;
BA_REL_ "GenSigTimeoutTime" BU_SG_REL_ Daempfer SG_ 1192 BR5_Sign_Druck 500;
BA_REL_ "GenSigTimeoutTime" BU_SG_REL_ EPB_TRW_VW411CS SG_ 1192 BR5_Sign_Druck 500;
BA_REL_ "GenSigTimeoutTime" BU_SG_REL_ Gateway_PQ35 SG_ 1192 BR5_Sign_Druck 500;
BA_REL_ "GenSigTimeoutTime" BU_SG_REL_ Getriebe_DQ SG_ 1192 BR5_Sign_Druck 500;
BA_REL_ "GenSigTimeoutTime" BU_SG_REL_ Getriebe_DQ_Hyb SG_ 1192 BR5_Sign_Druck 500;
BA_REL_ "GenSigTimeoutTime" BU_SG_REL_ HCA SG_ 1192 BR5_Sign_Druck 500;
BA_REL_ "GenSigTimeoutTime" BU_SG_REL_ Magne_Ride SG_ 1192 BR5_Sign_Druck 500;
BA_REL_ "GenSigTimeoutTime" BU_SG_REL_ Motor_Diesel SG_ 1192 BR5_Sign_Druck 500;
BA_REL_ "GenSigTimeoutTime" BU_SG_REL_ Motor_Otto SG_ 1192 BR5_Sign_Druck 500;
BA_REL_ "GenSigTimeoutTime" BU_SG_REL_ EPB_TRW_VW411CS SG_ 1192 ESP_Anforderung_EPB 500;
BA_REL_ "GenSigTimeoutTime" BU_SG_REL_ EPB_TRW_VW411CS SG_ 1192 ESP_Autohold_aktiv 500;
BA_REL_ "GenSigTimeoutTime" BU_SG_REL_ EPB_TRW_VW411CS SG_ 1192 ESP_Autohold_Standby 500;
BA_REL_ "GenSigTimeoutTime" BU_SG_REL_ Getriebe_DQ SG_ 1192 BR5_Anhi_Sta 500;
BA_REL_ "GenSigTimeoutTime" BU_SG_REL_ Getriebe_DQ_Hyb SG_ 1192 BR5_Anhi_Sta 500;
BA_REL_ "GenSigTimeoutTime" BU_SG_REL_ Getriebe_DQ SG_ 1192 BR5_Anhi_akt 500;
BA_REL_ "GenSigTimeoutTime" BU_SG_REL_ Getriebe_DQ_Hyb SG_ 1192 BR5_Anhi_akt 500;
BA_REL_ "GenSigTimeoutTime" BU_SG_REL_ Daempfer SG_ 1192 BR5_Zaehler 500;
BA_REL_ "GenSigTimeoutTime" BU_SG_REL_ EPB_TRW SG_ 1192 BR5_Zaehler 500;
BA_REL_ "GenSigTimeoutTime" BU_SG_REL_ EPB_TRW_VW411CS SG_ 1192 BR5_Zaehler 500;
BA_REL_ "GenSigTimeoutTime" BU_SG_REL_ HCA SG_ 1192 BR5_Zaehler 500;
BA_REL_ "GenSigTimeoutTime" BU_SG_REL_ Magne_Ride SG_ 1192 BR5_Zaehler 500;
BA_REL_ "GenSigTimeoutTime" BU_SG_REL_ Motor_Diesel SG_ 1192 BR5_Zaehler 500;
BA_REL_ "GenSigTimeoutTime" BU_SG_REL_ Motor_Otto SG_ 1192 BR5_Zaehler 500;
BA_REL_ "GenSigTimeoutTime" BU_SG_REL_ PDC_PLA SG_ 1192 BR5_Zaehler 500;
BA_REL_ "GenSigTimeoutTime" BU_SG_REL_ Daempfer SG_ 1192 BR5_Checksumme 500;
BA_REL_ "GenSigTimeoutTime" BU_SG_REL_ EPB_TRW SG_ 1192 BR5_Checksumme 500;
BA_REL_ "GenSigTimeoutTime" BU_SG_REL_ EPB_TRW_VW411CS SG_ 1192 BR5_Checksumme 500;
BA_REL_ "GenSigTimeoutTime" BU_SG_REL_ HCA SG_ 1192 BR5_Checksumme 500;
BA_REL_ "GenSigTimeoutTime" BU_SG_REL_ Magne_Ride SG_ 1192 BR5_Checksumme 500;
BA_REL_ "GenSigTimeoutTime" BU_SG_REL_ Motor_Diesel SG_ 1192 BR5_Checksumme 500;
BA_REL_ "GenSigTimeoutTime" BU_SG_REL_ Motor_Otto SG_ 1192 BR5_Checksumme 500;
BA_REL_ "GenSigTimeoutTime" BU_SG_REL_ EPB_TRW SG_ 428 BR8_Checksumme 500;
BA_REL_ "GenSigTimeoutTime" BU_SG_REL_ EPB_TRW_VW411CS SG_ 428 BR8_Checksumme 500;
BA_REL_ "GenSigTimeoutTime" BU_SG_REL_ Getriebe_AG6 SG_ 428 BR8_Checksumme 500;
BA_REL_ "GenSigTimeoutTime" BU_SG_REL_ Getriebe_DQ SG_ 428 BR8_Checksumme 500;
BA_REL_ "GenSigTimeoutTime" BU_SG_REL_ Getriebe_DQ_Hyb SG_ 428 BR8_Checksumme 500;
BA_REL_ "GenSigTimeoutTime" BU_SG_REL_ Motor_Diesel SG_ 428 BR8_Checksumme 500;
BA_REL_ "GenSigTimeoutTime" BU_SG_REL_ Motor_Otto SG_ 428 BR8_Checksumme 500;
BA_REL_ "GenSigTimeoutTime" BU_SG_REL_ PDC_PLA SG_ 428 BR8_Checksumme 500;
BA_REL_ "GenSigTimeoutTime" BU_SG_REL_ EPB_TRW SG_ 428 BR8_Zaehler 500;
BA_REL_ "GenSigTimeoutTime" BU_SG_REL_ EPB_TRW_VW411CS SG_ 428 BR8_Zaehler 500;
BA_REL_ "GenSigTimeoutTime" BU_SG_REL_ Getriebe_AG6 SG_ 428 BR8_Zaehler 500;
BA_REL_ "GenSigTimeoutTime" BU_SG_REL_ Motor_Diesel SG_ 428 BR8_Zaehler 500;
BA_REL_ "GenSigTimeoutTime" BU_SG_REL_ Motor_Otto SG_ 428 BR8_Zaehler 500;
BA_REL_ "GenSigTimeoutTime" BU_SG_REL_ PDC_PLA SG_ 428 BR8_Zaehler 500;
BA_REL_ "GenSigTimeoutTime" BU_SG_REL_ Getriebe_DQ SG_ 428 BR8_Sta_ACC_Anf 500;
BA_REL_ "GenSigTimeoutTime" BU_SG_REL_ Motor_Diesel SG_ 428 BR8_Sta_ACC_Anf 500;
BA_REL_ "GenSigTimeoutTime" BU_SG_REL_ Motor_Otto SG_ 428 BR8_Sta_ACC_Anf 500;
BA_REL_ "GenSigTimeoutTime" BU_SG_REL_ EPB_TRW SG_ 428 BR8_Verz_EPB_akt 500;
BA_REL_ "GenSigTimeoutTime" BU_SG_REL_ EPB_TRW_VW411CS SG_ 428 BR8_Verz_EPB_akt 500;
BA_REL_ "GenSigTimeoutTime" BU_SG_REL_ Motor_Diesel SG_ 428 BR8_Verz_EPB_akt 500;
BA_REL_ "GenSigTimeoutTime" BU_SG_REL_ Motor_Otto SG_ 428 BR8_Verz_EPB_akt 500;
BA_REL_ "GenSigTimeoutTime" BU_SG_REL_ Motor_Diesel SG_ 428 BR8_Sta_Br_temp 500;
BA_REL_ "GenSigTimeoutTime" BU_SG_REL_ Motor_Otto SG_ 428 BR8_Sta_Br_temp 500;
BA_REL_ "GenSigTimeoutTime" BU_SG_REL_ Motor_Diesel SG_ 428 BR8_Sta_Br_Druck 500;
BA_REL_ "GenSigTimeoutTime" BU_SG_REL_ Motor_Otto SG_ 428 BR8_Sta_Br_Druck 500;
BA_REL_ "GenSigTimeoutTime" BU_SG_REL_ Motor_Otto SG_ 428 BR8_Sta_Br_Druck 500;
BA_REL_ "GenSigTimeoutTime" BU_SG_REL_ Motor_Diesel SG_ 428 BR8_Istbeschl 500;
BA_REL_ "GenSigTimeoutTime" BU_SG_REL_ Motor_Otto SG_ 428 BR8_Istbeschl 500;
BA_REL_ "GenSigTimeoutTime" BU_SG_REL_ EPB_TRW_VW411CS SG_ 428 BR8_QB_LBeschl 500;
BA_REL_ "GenSigTimeoutTime" BU_SG_REL_ Getriebe_DQ SG_ 428 BR8_QB_LBeschl 500;
BA_REL_ "GenSigTimeoutTime" BU_SG_REL_ Getriebe_DQ_Hyb SG_ 428 BR8_QB_LBeschl 500;
BA_REL_ "GenSigTimeoutTime" BU_SG_REL_ Motor_Diesel SG_ 428 BR8_QB_LBeschl 500;
BA_REL_ "GenSigTimeoutTime" BU_SG_REL_ Motor_Otto SG_ 428 BR8_QB_LBeschl 500;
BA_REL_ "GenSigTimeoutTime" BU_SG_REL_ PDC_PLA SG_ 428 BR8_QB_LBeschl 500;
BA_REL_ "GenSigTimeoutTime" BU_SG_REL_ Motor_Diesel SG_ 428 BR8_aktBrSyst 500;
BA_REL_ "GenSigTimeoutTime" BU_SG_REL_ Motor_Otto SG_ 428 BR8_aktBrSyst 500;
BA_REL_ "GenSigTimeoutTime" BU_SG_REL_ Motor_Diesel SG_ 428 BR8_Fa_bremst 500;
BA_REL_ "GenSigTimeoutTime" BU_SG_REL_ Motor_Otto SG_ 428 BR8_Fa_bremst 500;
BA_REL_ "GenSigTimeoutTime" BU_SG_REL_ Motor_Diesel SG_ 428 BR8_StaBrSyst 500;
BA_REL_ "GenSigTimeoutTime" BU_SG_REL_ Motor_Otto SG_ 428 BR8_StaBrSyst 500;
BA_REL_ "GenSigTimeoutTime" BU_SG_REL_ EPB_TRW_VW411CS SG_ 428 BR8_Laengsbeschl 500;
BA_REL_ "GenSigTimeoutTime" BU_SG_REL_ Getriebe_AG6 SG_ 428 BR8_Laengsbeschl 500;
BA_REL_ "GenSigTimeoutTime" BU_SG_REL_ Getriebe_DQ SG_ 428 BR8_Laengsbeschl 500;
BA_REL_ "GenSigTimeoutTime" BU_SG_REL_ Getriebe_DQ_Hyb SG_ 428 BR8_Laengsbeschl 500;
BA_REL_ "GenSigTimeoutTime" BU_SG_REL_ Motor_Diesel SG_ 428 BR8_Laengsbeschl 500;
BA_REL_ "GenSigTimeoutTime" BU_SG_REL_ Motor_Otto SG_ 428 BR8_Laengsbeschl 500;
BA_REL_ "GenSigTimeoutTime" BU_SG_REL_ PDC_PLA SG_ 428 BR8_Laengsbeschl 500;
BA_REL_ "GenSigTimeoutTime" BU_SG_REL_ Motor_Diesel SG_ 428 BR8_Sta_ADR_BR 500;
BA_REL_ "GenSigTimeoutTime" BU_SG_REL_ Motor_Otto SG_ 428 BR8_Sta_ADR_BR 500;
BA_REL_ "GenSigTimeoutTime" BU_SG_REL_ Motor_Diesel SG_ 428 BR8_Sta_VerzReg 500;
BA_REL_ "GenSigTimeoutTime" BU_SG_REL_ Motor_Otto SG_ 428 BR8_Sta_VerzReg 500;
BA_REL_ "GenSigTimeoutTime" BU_SG_REL_ Motor_Diesel SG_ 428 BR8_Sta_BLS 500;
BA_REL_ "GenSigTimeoutTime" BU_SG_REL_ Motor_Otto SG_ 428 BR8_Sta_BLS 500;
BA_REL_ "GenSigTimeoutTime" BU_SG_REL_ EPB_TRW SG_ 428 BR8_Verz_EPB 500;
BA_REL_ "GenSigTimeoutTime" BU_SG_REL_ EPB_TRW_VW411CS SG_ 428 BR8_Verz_EPB 500;
BA_REL_ "GenSigTimeoutTime" BU_SG_REL_ EPB_TRW_VW411CS SG_ 428 BR8_Check_EPB 500;
BA_REL_ "GenSigTimeoutTime" BU_SG_REL_ LH_EPS_APA SG_ 174 BR9_Checksumme 500;
BA_REL_ "GenSigTimeoutTime" BU_SG_REL_ LH_EPS_ZF_2G SG_ 174 BR9_Checksumme 500;
BA_REL_ "GenSigTimeoutTime" BU_SG_REL_ LH_EPS_ZF_3G SG_ 174 BR9_Checksumme 500;
BA_REL_ "GenSigTimeoutTime" BU_SG_REL_ Getriebe_DQ SG_ 174 BR9_Sta_ESP_PLA 500;
BA_REL_ "GenSigTimeoutTime" BU_SG_REL_ Getriebe_DQ_Hyb SG_ 174 BR9_Sta_ESP_PLA 500;
BA_REL_ "GenSigTimeoutTime" BU_SG_REL_ PDC_PLA SG_ 174 BR9_Sta_ESP_PLA 500;
BA_REL_ "GenSigTimeoutTime" BU_SG_REL_ LH_EPS_APA SG_ 174 BR9_Zaehler 500;
BA_REL_ "GenSigTimeoutTime" BU_SG_REL_ LH_EPS_ZF_2G SG_ 174 BR9_Zaehler 500;
BA_REL_ "GenSigTimeoutTime" BU_SG_REL_ LH_EPS_ZF_3G SG_ 174 BR9_Zaehler 500;
BA_REL_ "GenSigTimeoutTime" BU_SG_REL_ LH_EPS_APA SG_ 174 BR9_LMOffset 500;
BA_REL_ "GenSigTimeoutTime" BU_SG_REL_ LH_EPS_ZF_2G SG_ 174 BR9_LMOffset 500;
BA_REL_ "GenSigTimeoutTime" BU_SG_REL_ LH_EPS_ZF_3G SG_ 174 BR9_LMOffset 500;
BA_REL_ "GenSigTimeoutTime" BU_SG_REL_ LH_EPS_APA SG_ 174 BR9_LMOffSign 500;
BA_REL_ "GenSigTimeoutTime" BU_SG_REL_ LH_EPS_ZF_2G SG_ 174 BR9_LMOffSign 500;
BA_REL_ "GenSigTimeoutTime" BU_SG_REL_ LH_EPS_ZF_3G SG_ 174 BR9_LMOffSign 500;
BA_REL_ "GenSigTimeoutTime" BU_SG_REL_ LH_EPS_APA SG_ 174 BR9_LWOffset 500;
BA_REL_ "GenSigTimeoutTime" BU_SG_REL_ LH_EPS_ZF_2G SG_ 174 BR9_LWOffset 500;
BA_REL_ "GenSigTimeoutTime" BU_SG_REL_ LH_EPS_ZF_3G SG_ 174 BR9_LWOffset 500;
BA_REL_ "GenSigTimeoutTime" BU_SG_REL_ LH_EPS_APA SG_ 174 BR9_LWOffSign 500;
BA_REL_ "GenSigTimeoutTime" BU_SG_REL_ LH_EPS_ZF_2G SG_ 174 BR9_LWOffSign 500;
BA_REL_ "GenSigTimeoutTime" BU_SG_REL_ LH_EPS_ZF_3G SG_ 174 BR9_LWOffSign 500;
BA_REL_ "GenSigTimeoutTime" BU_SG_REL_ LH_EPS_APA SG_ 174 BR9_Sta_DSR 500;
BA_REL_ "GenSigTimeoutTime" BU_SG_REL_ LH_EPS_ZF_2G SG_ 174 BR9_Sta_DSR 500;
BA_REL_ "GenSigTimeoutTime" BU_SG_REL_ LH_EPS_ZF_3G SG_ 174 BR9_Sta_DSR 500;
BA_REL_ "GenSigTimeoutTime" BU_SG_REL_ PDC_PLA SG_ 174 BR9_PLA_Abbruch 500;
BA_REL_ "GenSigTimeoutTime" BU_SG_REL_ Bremse_MK60EC SG_ 1524 BCN_Checksumme 5000;
BA_REL_ "GenSigTimeoutTime" BU_SG_REL_ Bremse_MK60EC SG_ 1524 BCN_BremsenVar 5000;
BA_REL_ "GenSigTimeoutTime" BU_SG_REL_ Bremse_MK60EC SG_ 1524 BCN_AntriebsVar 5000;
BA_REL_ "GenSigTimeoutTime" BU_SG_REL_ Gateway_PQ35 SG_ 1091 RKA_KD_Fehler 5000;
BA_REL_ "GenSigTimeoutTime" BU_SG_REL_ EPB_TRW SG_ 1392 BSL_ZAS_Kl_S 1000;
BA_REL_ "GenSigTimeoutTime" BU_SG_REL_ EPB_TRW_VW411CS SG_ 1392 BSL_ZAS_Kl_S 1000;
BA_REL_ "GenSigTimeoutTime" BU_SG_REL_ Ladegeraet_EGolf SG_ 1392 BSL_ZAS_Kl_S 1000;
BA_REL_ "GenSigTimeoutTime" BU_SG_REL_ BMS_Hybrid SG_ 1392 BSL_ZAS_Kl_15 1000;
BA_REL_ "GenSigTimeoutTime" BU_SG_REL_ Bremse_MK60EC SG_ 1392 BSL_ZAS_Kl_15 1000;
BA_REL_ "GenSigTimeoutTime" BU_SG_REL_ Bremse_TRW_EBC450M SG_ 1392 BSL_ZAS_Kl_15 1000;
BA_REL_ "GenSigTimeoutTime" BU_SG_REL_ Bremse_TRW_ESP SG_ 1392 BSL_ZAS_Kl_15 1000;
BA_REL_ "GenSigTimeoutTime" BU_SG_REL_ EPB_TRW SG_ 1392 BSL_ZAS_Kl_15 1000;
BA_REL_ "GenSigTimeoutTime" BU_SG_REL_ EPB_TRW_VW411CS SG_ 1392 BSL_ZAS_Kl_15 1000;
BA_REL_ "GenSigTimeoutTime" BU_SG_REL_ FLA SG_ 1392 BSL_ZAS_Kl_15 1000;
BA_REL_ "GenSigTimeoutTime" BU_SG_REL_ Ladegeraet_EGolf SG_ 1392 BSL_ZAS_Kl_15 1000;
BA_REL_ "GenSigTimeoutTime" BU_SG_REL_ PDC_PLA SG_ 1392 BSL_ZAS_Kl_15 1000;
BA_REL_ "GenSigTimeoutTime" BU_SG_REL_ AFS SG_ 1392 BSL_ZAS_Kl_X 1000;
BA_REL_ "GenSigTimeoutTime" BU_SG_REL_ EPB_TRW SG_ 1392 BSL_ZAS_Kl_X 1000;
BA_REL_ "GenSigTimeoutTime" BU_SG_REL_ EPB_TRW_VW411CS SG_ 1392 BSL_ZAS_Kl_X 1000;
BA_REL_ "GenSigTimeoutTime" BU_SG_REL_ FLA SG_ 1392 BSL_ZAS_Kl_X 1000;
BA_REL_ "GenSigTimeoutTime" BU_SG_REL_ HCA SG_ 1392 BSL_ZAS_Kl_X 1000;
BA_REL_ "GenSigTimeoutTime" BU_SG_REL_ LWR SG_ 1392 BSL_ZAS_Kl_X 1000;
BA_REL_ "GenSigTimeoutTime" BU_SG_REL_ Motor_Diesel SG_ 1392 BSL_ZAS_Kl_X 1000;
BA_REL_ "GenSigTimeoutTime" BU_SG_REL_ PDC_PLA SG_ 1392 BSL_ZAS_Kl_X 1000;
BA_REL_ "GenSigTimeoutTime" BU_SG_REL_ AFS SG_ 1392 BSL_ZAS_Kl_50 1000;
BA_REL_ "GenSigTimeoutTime" BU_SG_REL_ Bremse_TRW_EBC450M SG_ 1392 BSL_ZAS_Kl_50 1000;
BA_REL_ "GenSigTimeoutTime" BU_SG_REL_ EPB_TRW SG_ 1392 BSL_ZAS_Kl_50 1000;
BA_REL_ "GenSigTimeoutTime" BU_SG_REL_ EPB_TRW_VW411CS SG_ 1392 BSL_ZAS_Kl_50 1000;
BA_REL_ "GenSigTimeoutTime" BU_SG_REL_ LH_EPS_APA SG_ 1392 BSL_ZAS_Kl_50 1000;
BA_REL_ "GenSigTimeoutTime" BU_SG_REL_ LWR SG_ 1392 BSL_ZAS_Kl_50 1000;
BA_REL_ "GenSigTimeoutTime" BU_SG_REL_ Magne_Ride SG_ 1392 BSL_ZAS_Kl_50 1000;
BA_REL_ "GenSigTimeoutTime" BU_SG_REL_ Motor_Diesel SG_ 1392 BSL_ZAS_Kl_50 1000;
BA_REL_ "GenSigTimeoutTime" BU_SG_REL_ Motor_Diesel SG_ 1392 BSL_LL_Anheb2 1000;
BA_REL_ "GenSigTimeoutTime" BU_SG_REL_ Motor_Hybrid SG_ 1392 BSL_LL_Anheb2 1000;
BA_REL_ "GenSigTimeoutTime" BU_SG_REL_ Motor_Otto SG_ 1392 BSL_LL_Anheb2 1000;
BA_REL_ "GenSigTimeoutTime" BU_SG_REL_ Motor_Diesel SG_ 1392 BSL_LL_Anheb 1000;
BA_REL_ "GenSigTimeoutTime" BU_SG_REL_ Motor_Hybrid SG_ 1392 BSL_LL_Anheb 1000;
BA_REL_ "GenSigTimeoutTime" BU_SG_REL_ Motor_Otto SG_ 1392 BSL_LL_Anheb 1000;
BA_REL_ "GenSigTimeoutTime" BU_SG_REL_ EPB_TRW SG_ 1392 BSL_Sta_UBat 1000;
BA_REL_ "GenSigTimeoutTime" BU_SG_REL_ Motor_Diesel SG_ 1392 BSL_Motor_Haube 1000;
BA_REL_ "GenSigTimeoutTime" BU_SG_REL_ Motor_Hybrid SG_ 1392 BSL_Motor_Haube 1000;
BA_REL_ "GenSigTimeoutTime" BU_SG_REL_ Motor_Otto SG_ 1392 BSL_Motor_Haube 1000;
BA_REL_ "GenSigTimeoutTime" BU_SG_REL_ EPB_TRW SG_ 1392 BSL_UBat 1000;
BA_REL_ "GenSigTimeoutTime" BU_SG_REL_ Motor_Diesel SG_ 1392 BSL_Clima 1000;
BA_REL_ "GenSigTimeoutTime" BU_SG_REL_ Motor_Hybrid SG_ 1392 BSL_Clima 1000;
BA_REL_ "GenSigTimeoutTime" BU_SG_REL_ Motor_Otto SG_ 1392 BSL_Clima 1000;
BA_REL_ "GenSigTimeoutTime" BU_SG_REL_ Motor_Diesel SG_ 1392 BSL_BSG_2_alt 1000;
BA_REL_ "GenSigTimeoutTime" BU_SG_REL_ Motor_Hybrid SG_ 1392 BSL_BSG_2_alt 1000;
BA_REL_ "GenSigTimeoutTime" BU_SG_REL_ Motor_Otto SG_ 1392 BSL_BSG_2_alt 1000;
BA_REL_ "GenSigTimeoutTime" BU_SG_REL_ BMS_Hybrid SG_ 1392 BSL_BSG_3_alt 1000;
BA_REL_ "GenSigTimeoutTime" BU_SG_REL_ Bremse_MK60EC SG_ 1392 BSL_BSG_3_alt 1000;
BA_REL_ "GenSigTimeoutTime" BU_SG_REL_ Bremse_MK60EC SG_ 1392 BSL_BSG_3_alt 1000;
BA_REL_ "GenSigTimeoutTime" BU_SG_REL_ Bremse_TRW_EBC450M SG_ 1392 BSL_BSG_3_alt 1000;
BA_REL_ "GenSigTimeoutTime" BU_SG_REL_ Bremse_TRW_ESP SG_ 1392 BSL_BSG_3_alt 1000;
BA_REL_ "GenSigTimeoutTime" BU_SG_REL_ EPB_TRW_VW411CS SG_ 1392 BSL_BSG_3_alt 1000;
BA_REL_ "GenSigTimeoutTime" BU_SG_REL_ FLA SG_ 1392 BSL_BSG_3_alt 1000;
BA_REL_ "GenSigTimeoutTime" BU_SG_REL_ HCA SG_ 1392 BSL_BSG_3_alt 1000;
BA_REL_ "GenSigTimeoutTime" BU_SG_REL_ Ladegeraet_EGolf SG_ 1392 BSL_BSG_3_alt 1000;
BA_REL_ "GenSigTimeoutTime" BU_SG_REL_ LH_EPS_APA SG_ 1392 BSL_BSG_3_alt 1000;
BA_REL_ "GenSigTimeoutTime" BU_SG_REL_ Motor_Diesel SG_ 1392 BSL_BSG_3_alt 1000;
BA_REL_ "GenSigTimeoutTime" BU_SG_REL_ Motor_Hybrid SG_ 1392 BSL_BSG_3_alt 1000;
BA_REL_ "GenSigTimeoutTime" BU_SG_REL_ Motor_Otto SG_ 1392 BSL_BSG_3_alt 1000;
BA_REL_ "GenSigTimeoutTime" BU_SG_REL_ PDC_PLA SG_ 1392 BSL_BSG_3_alt 1000;
BA_REL_ "GenSigTimeoutTime" BU_SG_REL_ LH_EPS_ZF_2G SG_ 1392 BSL_Kuehlerlueft 1000;
BA_REL_ "GenSigTimeoutTime" BU_SG_REL_ LH_EPS_ZF_3G SG_ 1392 BSL_Kuehlerlueft 1000;
BA_REL_ "GenSigTimeoutTime" BU_SG_REL_ Motor_Diesel SG_ 1392 BSL_Kuehlerlueft 1000;
BA_REL_ "GenSigTimeoutTime" BU_SG_REL_ Motor_Hybrid SG_ 1392 BSL_Kuehlerlueft 1000;
BA_REL_ "GenSigTimeoutTime" BU_SG_REL_ Motor_Otto SG_ 1392 BSL_Kuehlerlueft 1000;
BA_REL_ "GenSigTimeoutTime" BU_SG_REL_ LH_EPS_APA SG_ 1392 BSL_Ab_Batterie 1000;
BA_REL_ "GenSigTimeoutTime" BU_SG_REL_ LH_EPS_ZF_2G SG_ 1392 BSL_Ab_Batterie 1000;
BA_REL_ "GenSigTimeoutTime" BU_SG_REL_ LH_EPS_ZF_3G SG_ 1392 BSL_Ab_Batterie 1000;
BA_REL_ "GenSigTimeoutTime" BU_SG_REL_ Motor_Diesel SG_ 1392 BSL_Ab_Batterie 1000;
BA_REL_ "GenSigTimeoutTime" BU_SG_REL_ Motor_Hybrid SG_ 1392 BSL_Ab_Batterie 1000;
BA_REL_ "GenSigTimeoutTime" BU_SG_REL_ Motor_Otto SG_ 1392 BSL_Ab_Batterie 1000;
BA_REL_ "GenSigTimeoutTime" BU_SG_REL_ Motor_Hybrid SG_ 1392 BSL_Weckursache_ACAN 1000;
BA_REL_ "GenSigTimeoutTime" BU_SG_REL_ Motor_Otto SG_ 1392 BSL_Weckursache_ACAN 1000;
BA_REL_ "GenSigTimeoutTime" BU_SG_REL_ Motor_Hybrid SG_ 1392 BSL_Wake_Up_ACAN 1000;
BA_REL_ "GenSigTimeoutTime" BU_SG_REL_ Motor_Otto SG_ 1392 BSL_Wake_Up_ACAN 1000;
BA_REL_ "GenSigTimeoutTime" BU_SG_REL_ Bremse_MK60EC SG_ 1392 BSL_Starterlaubnis 1000;
BA_REL_ "GenSigTimeoutTime" BU_SG_REL_ Bremse_TRW_EBC450M SG_ 1392 BSL_Starterlaubnis 1000;
BA_REL_ "GenSigTimeoutTime" BU_SG_REL_ Bremse_TRW_ESP SG_ 1392 BSL_Starterlaubnis 1000;
BA_REL_ "GenSigTimeoutTime" BU_SG_REL_ Motor_Diesel SG_ 1392 BSL_Starterlaubnis 1000;
BA_REL_ "GenSigTimeoutTime" BU_SG_REL_ Motor_Otto SG_ 1392 BSL_Starterlaubnis 1000;
BA_REL_ "GenSigTimeoutTime" BU_SG_REL_ PDC_PLA SG_ 1530 Module_ID_19 500;
BA_REL_ "GenSigTimeoutTime" BU_SG_REL_ PDC_PLA SG_ 1530 Update_Indikator_19 500;
BA_REL_ "GenSigTimeoutTime" BU_SG_REL_ PDC_PLA SG_ 1530 Funktions_ID_19 500;
BA_REL_ "GenSigTimeoutTime" BU_SG_REL_ PDC_PLA SG_ 1530 OpCode_19 500;
BA_REL_ "GenSigTimeoutTime" BU_SG_REL_ PDC_PLA SG_ 1530 Controller_ID_19 500;
BA_REL_ "GenSigTimeoutTime" BU_SG_REL_ PDC_PLA SG_ 1530 Data_Byte_1_19 500;
BA_REL_ "GenSigTimeoutTime" BU_SG_REL_ PDC_PLA SG_ 1530 Data_Byte_2_19 500;
BA_REL_ "GenSigTimeoutTime" BU_SG_REL_ PDC_PLA SG_ 1530 Data_Byte_3_19 500;
BA_REL_ "GenSigTimeoutTime" BU_SG_REL_ PDC_PLA SG_ 1530 Data_Byte_4_19 500;
BA_REL_ "GenSigTimeoutTime" BU_SG_REL_ PDC_PLA SG_ 1530 Data_Byte_5_19 500;
BA_REL_ "GenSigTimeoutTime" BU_SG_REL_ Motor_Diesel SG_ 1504 CL1_LL_Dz 1000;
BA_REL_ "GenSigTimeoutTime" BU_SG_REL_ Motor_Hybrid SG_ 1504 CL1_LL_Dz 1000;
BA_REL_ "GenSigTimeoutTime" BU_SG_REL_ Motor_Otto SG_ 1504 CL1_LL_Dz 1000;
BA_REL_ "GenSigTimeoutTime" BU_SG_REL_ Motor_Diesel SG_ 1504 CL1_Fa_Zuheiz 1000;
BA_REL_ "GenSigTimeoutTime" BU_SG_REL_ Motor_Hybrid SG_ 1504 CL1_Fa_Zuheiz 1000;
BA_REL_ "GenSigTimeoutTime" BU_SG_REL_ Motor_Diesel SG_ 1504 CL1_Kompressor 1000;
BA_REL_ "GenSigTimeoutTime" BU_SG_REL_ Motor_Hybrid SG_ 1504 CL1_Kompressor 1000;
BA_REL_ "GenSigTimeoutTime" BU_SG_REL_ Motor_Otto SG_ 1504 CL1_Kompressor 1000;
BA_REL_ "GenSigTimeoutTime" BU_SG_REL_ Motor_Diesel SG_ 1504 CL1_Heizleist 1000;
BA_REL_ "GenSigTimeoutTime" BU_SG_REL_ Motor_Hybrid SG_ 1504 CL1_Sta_Moment 1000;
BA_REL_ "GenSigTimeoutTime" BU_SG_REL_ Motor_Otto SG_ 1504 CL1_Sta_Moment 1000;
BA_REL_ "GenSigTimeoutTime" BU_SG_REL_ Motor_Hybrid SG_ 1504 CL1_Sta_Druck 1000;
BA_REL_ "GenSigTimeoutTime" BU_SG_REL_ Motor_Otto SG_ 1504 CL1_Sta_Druck 1000;
BA_REL_ "GenSigTimeoutTime" BU_SG_REL_ Motor_Diesel SG_ 1504 CL1_Druck 1000;
BA_REL_ "GenSigTimeoutTime" BU_SG_REL_ Motor_Hybrid SG_ 1504 CL1_Druck 1000;
BA_REL_ "GenSigTimeoutTime" BU_SG_REL_ Motor_Otto SG_ 1504 CL1_Druck 1000;
BA_REL_ "GenSigTimeoutTime" BU_SG_REL_ Motor_Diesel SG_ 1504 CL1_Kompr_Last 1000;
BA_REL_ "GenSigTimeoutTime" BU_SG_REL_ Motor_Hybrid SG_ 1504 CL1_Kompr_Last 1000;
BA_REL_ "GenSigTimeoutTime" BU_SG_REL_ Motor_Otto SG_ 1504 CL1_Kompr_Last 1000;
BA_REL_ "GenSigTimeoutTime" BU_SG_REL_ BMS_Hybrid SG_ 1504 CL1_Gebl_last 1000;
BA_REL_ "GenSigTimeoutTime" BU_SG_REL_ Motor_Otto SG_ 1504 CL1_Gebl_last 1000;
BA_REL_ "GenSigTimeoutTime" BU_SG_REL_ Motor_Diesel SG_ 1504 CL1_Luefter 1000;
BA_REL_ "GenSigTimeoutTime" BU_SG_REL_ Motor_Hybrid SG_ 1504 CL1_Luefter 1000;
BA_REL_ "GenSigTimeoutTime" BU_SG_REL_ Motor_Otto SG_ 1504 CL1_Luefter 1000;
BA_REL_ "GenSigTimeoutTime" BU_SG_REL_ Motor_Diesel SG_ 1504 CL1_AC_Schalter 1000;
BA_REL_ "GenSigTimeoutTime" BU_SG_REL_ Motor_Hybrid SG_ 1504 CL1_AC_Schalter 1000;
BA_REL_ "GenSigTimeoutTime" BU_SG_REL_ Motor_Otto SG_ 1504 CL1_AC_Schalter 1000;
BA_REL_ "GenSigTimeoutTime" BU_SG_REL_ Ladegeraet_EGolf SG_ 1504 CL1_PTC_Hzg 1000;
BA_REL_ "GenSigTimeoutTime" BU_SG_REL_ Motor_Diesel SG_ 1504 KL_Thermomanagement 1000;
BA_REL_ "GenSigTimeoutTime" BU_SG_REL_ Motor_Hybrid SG_ 1504 KL_Thermomanagement 1000;
BA_REL_ "GenSigTimeoutTime" BU_SG_REL_ Motor_Otto SG_ 1504 KL_Thermomanagement 1000;
BA_REL_ "GenSigTimeoutTime" BU_SG_REL_ Gateway_PQ35 SG_ 1432 DA1_Daempferreg 1000;
BA_REL_ "GenSigTimeoutTime" BU_SG_REL_ Gateway_PQ35 SG_ 1432 DA1_Taster 1000;
BA_REL_ "GenSigTimeoutTime" BU_SG_REL_ Gateway_PQ35 SG_ 1432 DA1_Taster 1000;
BA_REL_ "GenSigTimeoutTime" BU_SG_REL_ Gateway_PQ35 SG_ 1432 DA1_Fehlereintr 1000;
BA_REL_ "GenSigTimeoutTime" BU_SG_REL_ Bremse_MK60EC SG_ 1432 DA1_Zaehler 1000;
BA_REL_ "GenSigTimeoutTime" BU_SG_REL_ Bremse_MK60EC SG_ 1432 DA1_ESP_Zwang 1000;
BA_REL_ "GenSigTimeoutTime" BU_SG_REL_ Gateway_PQ35 SG_ 1432 DA1_Charisma 1000;
BA_REL_ "GenSigTimeoutTime" BU_SG_REL_ Bremse_MK60EC SG_ 1432 DA1_Checksumme 1000;
BA_REL_ "GenSigTimeoutTime" BU_SG_REL_ AFS SG_ 2000 DI1_VerlernZaehl 5000;
BA_REL_ "GenSigTimeoutTime" BU_SG_REL_ Airbag SG_ 2000 DI1_VerlernZaehl 5000;
BA_REL_ "GenSigTimeoutTime" BU_SG_REL_ Allrad SG_ 2000 DI1_VerlernZaehl 5000;
BA_REL_ "GenSigTimeoutTime" BU_SG_REL_ BMS_Hybrid SG_ 2000 DI1_VerlernZaehl 5000;
BA_REL_ "GenSigTimeoutTime" BU_SG_REL_ Bremse_MK60EC SG_ 2000 DI1_VerlernZaehl 5000;
BA_REL_ "GenSigTimeoutTime" BU_SG_REL_ Bremse_TRW_EBC450M SG_ 2000 DI1_VerlernZaehl 5000;
BA_REL_ "GenSigTimeoutTime" BU_SG_REL_ Bremse_TRW_ESP SG_ 2000 DI1_VerlernZaehl 5000;
BA_REL_ "GenSigTimeoutTime" BU_SG_REL_ Daempfer SG_ 2000 DI1_VerlernZaehl 5000;
BA_REL_ "GenSigTimeoutTime" BU_SG_REL_ EPB_TRW SG_ 2000 DI1_VerlernZaehl 5000;
BA_REL_ "GenSigTimeoutTime" BU_SG_REL_ EPB_TRW_VW411CS SG_ 2000 DI1_VerlernZaehl 5000;
BA_REL_ "GenSigTimeoutTime" BU_SG_REL_ FLA SG_ 2000 DI1_VerlernZaehl 5000;
BA_REL_ "GenSigTimeoutTime" BU_SG_REL_ Getriebe_DQ SG_ 2000 DI1_VerlernZaehl 5000;
BA_REL_ "GenSigTimeoutTime" BU_SG_REL_ Getriebe_DQ_Hyb SG_ 2000 DI1_VerlernZaehl 5000;
BA_REL_ "GenSigTimeoutTime" BU_SG_REL_ HCA SG_ 2000 DI1_VerlernZaehl 5000;
BA_REL_ "GenSigTimeoutTime" BU_SG_REL_ LEH_Hybrid SG_ 2000 DI1_VerlernZaehl 5000;
BA_REL_ "GenSigTimeoutTime" BU_SG_REL_ LH_EPS_APA SG_ 2000 DI1_VerlernZaehl 5000;
BA_REL_ "GenSigTimeoutTime" BU_SG_REL_ LWR SG_ 2000 DI1_VerlernZaehl 5000;
BA_REL_ "GenSigTimeoutTime" BU_SG_REL_ Magne_Ride SG_ 2000 DI1_VerlernZaehl 5000;
BA_REL_ "GenSigTimeoutTime" BU_SG_REL_ Motor_Diesel SG_ 2000 DI1_VerlernZaehl 5000;
BA_REL_ "GenSigTimeoutTime" BU_SG_REL_ Motor_Hybrid SG_ 2000 DI1_VerlernZaehl 5000;
BA_REL_ "GenSigTimeoutTime" BU_SG_REL_ Motor_Otto SG_ 2000 DI1_VerlernZaehl 5000;
BA_REL_ "GenSigTimeoutTime" BU_SG_REL_ PDC_PLA SG_ 2000 DI1_VerlernZaehl 5000;
BA_REL_ "GenSigTimeoutTime" BU_SG_REL_ Quersperre_VAQ SG_ 2000 DI1_VerlernZaehl 5000;
BA_REL_ "GenSigTimeoutTime" BU_SG_REL_ RKA_Plus SG_ 2000 DI1_VerlernZaehl 5000;
BA_REL_ "GenSigTimeoutTime" BU_SG_REL_ AFS SG_ 2000 DI1_km_Stand 5000;
BA_REL_ "GenSigTimeoutTime" BU_SG_REL_ Airbag SG_ 2000 DI1_km_Stand 5000;
BA_REL_ "GenSigTimeoutTime" BU_SG_REL_ Allrad SG_ 2000 DI1_km_Stand 5000;
BA_REL_ "GenSigTimeoutTime" BU_SG_REL_ BMS_Hybrid SG_ 2000 DI1_km_Stand 5000;
BA_REL_ "GenSigTimeoutTime" BU_SG_REL_ Bremse_TRW_EBC450M SG_ 2000 DI1_km_Stand 5000;
BA_REL_ "GenSigTimeoutTime" BU_SG_REL_ Bremse_TRW_ESP SG_ 2000 DI1_km_Stand 5000;
BA_REL_ "GenSigTimeoutTime" BU_SG_REL_ Daempfer SG_ 2000 DI1_km_Stand 5000;
BA_REL_ "GenSigTimeoutTime" BU_SG_REL_ EPB_TRW SG_ 2000 DI1_km_Stand 5000;
BA_REL_ "GenSigTimeoutTime" BU_SG_REL_ EPB_TRW_VW411CS SG_ 2000 DI1_km_Stand 5000;
BA_REL_ "GenSigTimeoutTime" BU_SG_REL_ FLA SG_ 2000 DI1_km_Stand 5000;
BA_REL_ "GenSigTimeoutTime" BU_SG_REL_ Getriebe_DQ SG_ 2000 DI1_km_Stand 5000;
BA_REL_ "GenSigTimeoutTime" BU_SG_REL_ Getriebe_DQ_Hyb SG_ 2000 DI1_km_Stand 5000;
BA_REL_ "GenSigTimeoutTime" BU_SG_REL_ HCA SG_ 2000 DI1_km_Stand 5000;
BA_REL_ "GenSigTimeoutTime" BU_SG_REL_ LEH_Hybrid SG_ 2000 DI1_km_Stand 5000;
BA_REL_ "GenSigTimeoutTime" BU_SG_REL_ LH_EPS_APA SG_ 2000 DI1_km_Stand 5000;
BA_REL_ "GenSigTimeoutTime" BU_SG_REL_ LWR SG_ 2000 DI1_km_Stand 5000;
BA_REL_ "GenSigTimeoutTime" BU_SG_REL_ Magne_Ride SG_ 2000 DI1_km_Stand 5000;
BA_REL_ "GenSigTimeoutTime" BU_SG_REL_ Motor_Diesel SG_ 2000 DI1_km_Stand 5000;
BA_REL_ "GenSigTimeoutTime" BU_SG_REL_ Motor_Hybrid SG_ 2000 DI1_km_Stand 5000;
BA_REL_ "GenSigTimeoutTime" BU_SG_REL_ Motor_Otto SG_ 2000 DI1_km_Stand 5000;
BA_REL_ "GenSigTimeoutTime" BU_SG_REL_ PDC_PLA SG_ 2000 DI1_km_Stand 5000;
BA_REL_ "GenSigTimeoutTime" BU_SG_REL_ Quersperre_VAQ SG_ 2000 DI1_km_Stand 5000;
BA_REL_ "GenSigTimeoutTime" BU_SG_REL_ RKA_Plus SG_ 2000 DI1_km_Stand 5000;
BA_REL_ "GenSigTimeoutTime" BU_SG_REL_ AFS SG_ 2000 DI1_Jahr 5000;
BA_REL_ "GenSigTimeoutTime" BU_SG_REL_ Airbag SG_ 2000 DI1_Jahr 5000;
BA_REL_ "GenSigTimeoutTime" BU_SG_REL_ Allrad SG_ 2000 DI1_Jahr 5000;
BA_REL_ "GenSigTimeoutTime" BU_SG_REL_ BMS_Hybrid SG_ 2000 DI1_Jahr 5000;
BA_REL_ "GenSigTimeoutTime" BU_SG_REL_ Bremse_MK60EC SG_ 2000 DI1_Jahr 5000;
BA_REL_ "GenSigTimeoutTime" BU_SG_REL_ Bremse_MK70MABS SG_ 2000 DI1_Jahr 5000;
BA_REL_ "GenSigTimeoutTime" BU_SG_REL_ Bremse_TRW_EBC450M SG_ 2000 DI1_Jahr 5000;
BA_REL_ "GenSigTimeoutTime" BU_SG_REL_ Bremse_TRW_ESP SG_ 2000 DI1_Jahr 5000;
BA_REL_ "GenSigTimeoutTime" BU_SG_REL_ Daempfer SG_ 2000 DI1_Jahr 5000;
BA_REL_ "GenSigTimeoutTime" BU_SG_REL_ EPB_TRW SG_ 2000 DI1_Jahr 5000;
BA_REL_ "GenSigTimeoutTime" BU_SG_REL_ EPB_TRW_VW411CS SG_ 2000 DI1_Jahr 5000;
BA_REL_ "GenSigTimeoutTime" BU_SG_REL_ FLA SG_ 2000 DI1_Jahr 5000;
BA_REL_ "GenSigTimeoutTime" BU_SG_REL_ Getriebe_DQ SG_ 2000 DI1_Jahr 5000;
BA_REL_ "GenSigTimeoutTime" BU_SG_REL_ Getriebe_DQ_Hyb SG_ 2000 DI1_Jahr 5000;
BA_REL_ "GenSigTimeoutTime" BU_SG_REL_ HCA SG_ 2000 DI1_Jahr 5000;
BA_REL_ "GenSigTimeoutTime" BU_SG_REL_ LEH_Hybrid SG_ 2000 DI1_Jahr 5000;
BA_REL_ "GenSigTimeoutTime" BU_SG_REL_ LH_EPS_APA SG_ 2000 DI1_Jahr 5000;
BA_REL_ "GenSigTimeoutTime" BU_SG_REL_ LH_EPS_ZF_2G SG_ 2000 DI1_Jahr 5000;
BA_REL_ "GenSigTimeoutTime" BU_SG_REL_ LH_EPS_ZF_3G SG_ 2000 DI1_Jahr 5000;
BA_REL_ "GenSigTimeoutTime" BU_SG_REL_ LWR SG_ 2000 DI1_Jahr 5000;
BA_REL_ "GenSigTimeoutTime" BU_SG_REL_ Magne_Ride SG_ 2000 DI1_Jahr 5000;
BA_REL_ "GenSigTimeoutTime" BU_SG_REL_ Motor_Diesel SG_ 2000 DI1_Jahr 5000;
BA_REL_ "GenSigTimeoutTime" BU_SG_REL_ Motor_Hybrid SG_ 2000 DI1_Jahr 5000;
BA_REL_ "GenSigTimeoutTime" BU_SG_REL_ Motor_Otto SG_ 2000 DI1_Jahr 5000;
BA_REL_ "GenSigTimeoutTime" BU_SG_REL_ PDC_PLA SG_ 2000 DI1_Jahr 5000;
BA_REL_ "GenSigTimeoutTime" BU_SG_REL_ Quersperre_VAQ SG_ 2000 DI1_Jahr 5000;
BA_REL_ "GenSigTimeoutTime" BU_SG_REL_ RKA_Plus SG_ 2000 DI1_Jahr 5000;
BA_REL_ "GenSigTimeoutTime" BU_SG_REL_ AFS SG_ 2000 DI1_Monat 5000;
BA_REL_ "GenSigTimeoutTime" BU_SG_REL_ Airbag SG_ 2000 DI1_Monat 5000;
BA_REL_ "GenSigTimeoutTime" BU_SG_REL_ Allrad SG_ 2000 DI1_Monat 5000;
BA_REL_ "GenSigTimeoutTime" BU_SG_REL_ BMS_Hybrid SG_ 2000 DI1_Monat 5000;
BA_REL_ "GenSigTimeoutTime" BU_SG_REL_ Bremse_MK60EC SG_ 2000 DI1_Monat 5000;
BA_REL_ "GenSigTimeoutTime" BU_SG_REL_ Bremse_MK70MABS SG_ 2000 DI1_Monat 5000;
BA_REL_ "GenSigTimeoutTime" BU_SG_REL_ Bremse_TRW_EBC450M SG_ 2000 DI1_Monat 5000;
BA_REL_ "GenSigTimeoutTime" BU_SG_REL_ Bremse_TRW_ESP SG_ 2000 DI1_Monat 5000;
BA_REL_ "GenSigTimeoutTime" BU_SG_REL_ Daempfer SG_ 2000 DI1_Monat 5000;
BA_REL_ "GenSigTimeoutTime" BU_SG_REL_ EPB_TRW SG_ 2000 DI1_Monat 5000;
BA_REL_ "GenSigTimeoutTime" BU_SG_REL_ EPB_TRW_VW411CS SG_ 2000 DI1_Monat 5000;
BA_REL_ "GenSigTimeoutTime" BU_SG_REL_ FLA SG_ 2000 DI1_Monat 5000;
BA_REL_ "GenSigTimeoutTime" BU_SG_REL_ Getriebe_DQ SG_ 2000 DI1_Monat 5000;
BA_REL_ "GenSigTimeoutTime" BU_SG_REL_ Getriebe_DQ_Hyb SG_ 2000 DI1_Monat 5000;
BA_REL_ "GenSigTimeoutTime" BU_SG_REL_ HCA SG_ 2000 DI1_Monat 5000;
BA_REL_ "GenSigTimeoutTime" BU_SG_REL_ LEH_Hybrid SG_ 2000 DI1_Monat 5000;
BA_REL_ "GenSigTimeoutTime" BU_SG_REL_ LH_EPS_APA SG_ 2000 DI1_Monat 5000;
BA_REL_ "GenSigTimeoutTime" BU_SG_REL_ LH_EPS_ZF_2G SG_ 2000 DI1_Monat 5000;
BA_REL_ "GenSigTimeoutTime" BU_SG_REL_ LH_EPS_ZF_3G SG_ 2000 DI1_Monat 5000;
BA_REL_ "GenSigTimeoutTime" BU_SG_REL_ LWR SG_ 2000 DI1_Monat 5000;
BA_REL_ "GenSigTimeoutTime" BU_SG_REL_ Magne_Ride SG_ 2000 DI1_Monat 5000;
BA_REL_ "GenSigTimeoutTime" BU_SG_REL_ Motor_Diesel SG_ 2000 DI1_Monat 5000;
BA_REL_ "GenSigTimeoutTime" BU_SG_REL_ Motor_Hybrid SG_ 2000 DI1_Monat 5000;
BA_REL_ "GenSigTimeoutTime" BU_SG_REL_ Motor_Otto SG_ 2000 DI1_Monat 5000;
BA_REL_ "GenSigTimeoutTime" BU_SG_REL_ PDC_PLA SG_ 2000 DI1_Monat 5000;
BA_REL_ "GenSigTimeoutTime" BU_SG_REL_ Quersperre_VAQ SG_ 2000 DI1_Monat 5000;
BA_REL_ "GenSigTimeoutTime" BU_SG_REL_ RKA_Plus SG_ 2000 DI1_Monat 5000;
BA_REL_ "GenSigTimeoutTime" BU_SG_REL_ AFS SG_ 2000 DI1_Tag 5000;
BA_REL_ "GenSigTimeoutTime" BU_SG_REL_ Airbag SG_ 2000 DI1_Tag 5000;
BA_REL_ "GenSigTimeoutTime" BU_SG_REL_ Allrad SG_ 2000 DI1_Tag 5000;
BA_REL_ "GenSigTimeoutTime" BU_SG_REL_ BMS_Hybrid SG_ 2000 DI1_Tag 5000;
BA_REL_ "GenSigTimeoutTime" BU_SG_REL_ Bremse_MK60EC SG_ 2000 DI1_Tag 5000;
BA_REL_ "GenSigTimeoutTime" BU_SG_REL_ Bremse_MK70MABS SG_ 2000 DI1_Tag 5000;
BA_REL_ "GenSigTimeoutTime" BU_SG_REL_ Bremse_TRW_EBC450M SG_ 2000 DI1_Tag 5000;
BA_REL_ "GenSigTimeoutTime" BU_SG_REL_ Bremse_TRW_ESP SG_ 2000 DI1_Tag 5000;
BA_REL_ "GenSigTimeoutTime" BU_SG_REL_ Daempfer SG_ 2000 DI1_Tag 5000;
BA_REL_ "GenSigTimeoutTime" BU_SG_REL_ EPB_TRW SG_ 2000 DI1_Tag 5000;
BA_REL_ "GenSigTimeoutTime" BU_SG_REL_ EPB_TRW_VW411CS SG_ 2000 DI1_Tag 5000;
BA_REL_ "GenSigTimeoutTime" BU_SG_REL_ FLA SG_ 2000 DI1_Tag 5000;
BA_REL_ "GenSigTimeoutTime" BU_SG_REL_ Getriebe_DQ SG_ 2000 DI1_Tag 5000;
BA_REL_ "GenSigTimeoutTime" BU_SG_REL_ Getriebe_DQ_Hyb SG_ 2000 DI1_Tag 5000;
BA_REL_ "GenSigTimeoutTime" BU_SG_REL_ HCA SG_ 2000 DI1_Tag 5000;
BA_REL_ "GenSigTimeoutTime" BU_SG_REL_ LEH_Hybrid SG_ 2000 DI1_Tag 5000;
BA_REL_ "GenSigTimeoutTime" BU_SG_REL_ LH_EPS_APA SG_ 2000 DI1_Tag 5000;
BA_REL_ "GenSigTimeoutTime" BU_SG_REL_ LH_EPS_ZF_2G SG_ 2000 DI1_Tag 5000;
BA_REL_ "GenSigTimeoutTime" BU_SG_REL_ LH_EPS_ZF_3G SG_ 2000 DI1_Tag 5000;
BA_REL_ "GenSigTimeoutTime" BU_SG_REL_ LWR SG_ 2000 DI1_Tag 5000;
BA_REL_ "GenSigTimeoutTime" BU_SG_REL_ Magne_Ride SG_ 2000 DI1_Tag 5000;
BA_REL_ "GenSigTimeoutTime" BU_SG_REL_ Motor_Diesel SG_ 2000 DI1_Tag 5000;
BA_REL_ "GenSigTimeoutTime" BU_SG_REL_ Motor_Hybrid SG_ 2000 DI1_Tag 5000;
BA_REL_ "GenSigTimeoutTime" BU_SG_REL_ Motor_Otto SG_ 2000 DI1_Tag 5000;
BA_REL_ "GenSigTimeoutTime" BU_SG_REL_ PDC_PLA SG_ 2000 DI1_Tag 5000;
BA_REL_ "GenSigTimeoutTime" BU_SG_REL_ Quersperre_VAQ SG_ 2000 DI1_Tag 5000;
BA_REL_ "GenSigTimeoutTime" BU_SG_REL_ RKA_Plus SG_ 2000 DI1_Tag 5000;
BA_REL_ "GenSigTimeoutTime" BU_SG_REL_ AFS SG_ 2000 DI1_Stunde 5000;
BA_REL_ "GenSigTimeoutTime" BU_SG_REL_ Airbag SG_ 2000 DI1_Stunde 5000;
BA_REL_ "GenSigTimeoutTime" BU_SG_REL_ Allrad SG_ 2000 DI1_Stunde 5000;
BA_REL_ "GenSigTimeoutTime" BU_SG_REL_ BMS_Hybrid SG_ 2000 DI1_Stunde 5000;
BA_REL_ "GenSigTimeoutTime" BU_SG_REL_ Bremse_MK60EC SG_ 2000 DI1_Stunde 5000;
BA_REL_ "GenSigTimeoutTime" BU_SG_REL_ Bremse_TRW_EBC450M SG_ 2000 DI1_Stunde 5000;
BA_REL_ "GenSigTimeoutTime" BU_SG_REL_ Bremse_TRW_ESP SG_ 2000 DI1_Stunde 5000;
BA_REL_ "GenSigTimeoutTime" BU_SG_REL_ Daempfer SG_ 2000 DI1_Stunde 5000;
BA_REL_ "GenSigTimeoutTime" BU_SG_REL_ EPB_TRW SG_ 2000 DI1_Stunde 5000;
BA_REL_ "GenSigTimeoutTime" BU_SG_REL_ EPB_TRW_VW411CS SG_ 2000 DI1_Stunde 5000;
BA_REL_ "GenSigTimeoutTime" BU_SG_REL_ FLA SG_ 2000 DI1_Stunde 5000;
BA_REL_ "GenSigTimeoutTime" BU_SG_REL_ Getriebe_DQ SG_ 2000 DI1_Stunde 5000;
BA_REL_ "GenSigTimeoutTime" BU_SG_REL_ Getriebe_DQ_Hyb SG_ 2000 DI1_Stunde 5000;
BA_REL_ "GenSigTimeoutTime" BU_SG_REL_ HCA SG_ 2000 DI1_Stunde 5000;
BA_REL_ "GenSigTimeoutTime" BU_SG_REL_ LEH_Hybrid SG_ 2000 DI1_Stunde 5000;
BA_REL_ "GenSigTimeoutTime" BU_SG_REL_ LH_EPS_APA SG_ 2000 DI1_Stunde 5000;
BA_REL_ "GenSigTimeoutTime" BU_SG_REL_ LH_EPS_ZF_2G SG_ 2000 DI1_Stunde 5000;
BA_REL_ "GenSigTimeoutTime" BU_SG_REL_ LH_EPS_ZF_3G SG_ 2000 DI1_Stunde 5000;
BA_REL_ "GenSigTimeoutTime" BU_SG_REL_ LWR SG_ 2000 DI1_Stunde 5000;
BA_REL_ "GenSigTimeoutTime" BU_SG_REL_ Magne_Ride SG_ 2000 DI1_Stunde 5000;
BA_REL_ "GenSigTimeoutTime" BU_SG_REL_ Motor_Diesel SG_ 2000 DI1_Stunde 5000;
BA_REL_ "GenSigTimeoutTime" BU_SG_REL_ Motor_Hybrid SG_ 2000 DI1_Stunde 5000;
BA_REL_ "GenSigTimeoutTime" BU_SG_REL_ Motor_Otto SG_ 2000 DI1_Stunde 5000;
BA_REL_ "GenSigTimeoutTime" BU_SG_REL_ PDC_PLA SG_ 2000 DI1_Stunde 5000;
BA_REL_ "GenSigTimeoutTime" BU_SG_REL_ Quersperre_VAQ SG_ 2000 DI1_Stunde 5000;
BA_REL_ "GenSigTimeoutTime" BU_SG_REL_ RKA_Plus SG_ 2000 DI1_Stunde 5000;
BA_REL_ "GenSigTimeoutTime" BU_SG_REL_ AFS SG_ 2000 DI1_Minute 5000;
BA_REL_ "GenSigTimeoutTime" BU_SG_REL_ Airbag SG_ 2000 DI1_Minute 5000;
BA_REL_ "GenSigTimeoutTime" BU_SG_REL_ Allrad SG_ 2000 DI1_Minute 5000;
BA_REL_ "GenSigTimeoutTime" BU_SG_REL_ BMS_Hybrid SG_ 2000 DI1_Minute 5000;
BA_REL_ "GenSigTimeoutTime" BU_SG_REL_ Bremse_MK60EC SG_ 2000 DI1_Minute 5000;
BA_REL_ "GenSigTimeoutTime" BU_SG_REL_ Bremse_TRW_EBC450M SG_ 2000 DI1_Minute 5000;
BA_REL_ "GenSigTimeoutTime" BU_SG_REL_ Bremse_TRW_ESP SG_ 2000 DI1_Minute 5000;
BA_REL_ "GenSigTimeoutTime" BU_SG_REL_ Daempfer SG_ 2000 DI1_Minute 5000;
BA_REL_ "GenSigTimeoutTime" BU_SG_REL_ EPB_TRW SG_ 2000 DI1_Minute 5000;
BA_REL_ "GenSigTimeoutTime" BU_SG_REL_ EPB_TRW_VW411CS SG_ 2000 DI1_Minute 5000;
BA_REL_ "GenSigTimeoutTime" BU_SG_REL_ FLA SG_ 2000 DI1_Minute 5000;
BA_REL_ "GenSigTimeoutTime" BU_SG_REL_ Getriebe_DQ SG_ 2000 DI1_Minute 5000;
BA_REL_ "GenSigTimeoutTime" BU_SG_REL_ Getriebe_DQ_Hyb SG_ 2000 DI1_Minute 5000;
BA_REL_ "GenSigTimeoutTime" BU_SG_REL_ HCA SG_ 2000 DI1_Minute 5000;
BA_REL_ "GenSigTimeoutTime" BU_SG_REL_ LEH_Hybrid SG_ 2000 DI1_Minute 5000;
BA_REL_ "GenSigTimeoutTime" BU_SG_REL_ LH_EPS_APA SG_ 2000 DI1_Minute 5000;
BA_REL_ "GenSigTimeoutTime" BU_SG_REL_ LH_EPS_ZF_2G SG_ 2000 DI1_Minute 5000;
BA_REL_ "GenSigTimeoutTime" BU_SG_REL_ LH_EPS_ZF_3G SG_ 2000 DI1_Minute 5000;
BA_REL_ "GenSigTimeoutTime" BU_SG_REL_ LWR SG_ 2000 DI1_Minute 5000;
BA_REL_ "GenSigTimeoutTime" BU_SG_REL_ Magne_Ride SG_ 2000 DI1_Minute 5000;
BA_REL_ "GenSigTimeoutTime" BU_SG_REL_ Motor_Diesel SG_ 2000 DI1_Minute 5000;
BA_REL_ "GenSigTimeoutTime" BU_SG_REL_ Motor_Hybrid SG_ 2000 DI1_Minute 5000;
BA_REL_ "GenSigTimeoutTime" BU_SG_REL_ Motor_Otto SG_ 2000 DI1_Minute 5000;
BA_REL_ "GenSigTimeoutTime" BU_SG_REL_ PDC_PLA SG_ 2000 DI1_Minute 5000;
BA_REL_ "GenSigTimeoutTime" BU_SG_REL_ Quersperre_VAQ SG_ 2000 DI1_Minute 5000;
BA_REL_ "GenSigTimeoutTime" BU_SG_REL_ RKA_Plus SG_ 2000 DI1_Minute 5000;
BA_REL_ "GenSigTimeoutTime" BU_SG_REL_ AFS SG_ 2000 DI1_Sekunde 5000;
BA_REL_ "GenSigTimeoutTime" BU_SG_REL_ Airbag SG_ 2000 DI1_Sekunde 5000;
BA_REL_ "GenSigTimeoutTime" BU_SG_REL_ Allrad SG_ 2000 DI1_Sekunde 5000;
BA_REL_ "GenSigTimeoutTime" BU_SG_REL_ BMS_Hybrid SG_ 2000 DI1_Sekunde 5000;
BA_REL_ "GenSigTimeoutTime" BU_SG_REL_ Bremse_MK60EC SG_ 2000 DI1_Sekunde 5000;
BA_REL_ "GenSigTimeoutTime" BU_SG_REL_ Bremse_TRW_EBC450M SG_ 2000 DI1_Sekunde 5000;
BA_REL_ "GenSigTimeoutTime" BU_SG_REL_ Bremse_TRW_ESP SG_ 2000 DI1_Sekunde 5000;
BA_REL_ "GenSigTimeoutTime" BU_SG_REL_ Daempfer SG_ 2000 DI1_Sekunde 5000;
BA_REL_ "GenSigTimeoutTime" BU_SG_REL_ EPB_TRW SG_ 2000 DI1_Sekunde 5000;
BA_REL_ "GenSigTimeoutTime" BU_SG_REL_ EPB_TRW_VW411CS SG_ 2000 DI1_Sekunde 5000;
BA_REL_ "GenSigTimeoutTime" BU_SG_REL_ FLA SG_ 2000 DI1_Sekunde 5000;
BA_REL_ "GenSigTimeoutTime" BU_SG_REL_ Getriebe_DQ SG_ 2000 DI1_Sekunde 5000;
BA_REL_ "GenSigTimeoutTime" BU_SG_REL_ Getriebe_DQ_Hyb SG_ 2000 DI1_Sekunde 5000;
BA_REL_ "GenSigTimeoutTime" BU_SG_REL_ HCA SG_ 2000 DI1_Sekunde 5000;
BA_REL_ "GenSigTimeoutTime" BU_SG_REL_ LEH_Hybrid SG_ 2000 DI1_Sekunde 5000;
BA_REL_ "GenSigTimeoutTime" BU_SG_REL_ LH_EPS_APA SG_ 2000 DI1_Sekunde 5000;
BA_REL_ "GenSigTimeoutTime" BU_SG_REL_ LH_EPS_ZF_2G SG_ 2000 DI1_Sekunde 5000;
BA_REL_ "GenSigTimeoutTime" BU_SG_REL_ LH_EPS_ZF_3G SG_ 2000 DI1_Sekunde 5000;
BA_REL_ "GenSigTimeoutTime" BU_SG_REL_ LWR SG_ 2000 DI1_Sekunde 5000;
BA_REL_ "GenSigTimeoutTime" BU_SG_REL_ Magne_Ride SG_ 2000 DI1_Sekunde 5000;
BA_REL_ "GenSigTimeoutTime" BU_SG_REL_ Motor_Diesel SG_ 2000 DI1_Sekunde 5000;
BA_REL_ "GenSigTimeoutTime" BU_SG_REL_ Motor_Hybrid SG_ 2000 DI1_Sekunde 5000;
BA_REL_ "GenSigTimeoutTime" BU_SG_REL_ Motor_Otto SG_ 2000 DI1_Sekunde 5000;
BA_REL_ "GenSigTimeoutTime" BU_SG_REL_ PDC_PLA SG_ 2000 DI1_Sekunde 5000;
BA_REL_ "GenSigTimeoutTime" BU_SG_REL_ Quersperre_VAQ SG_ 2000 DI1_Sekunde 5000;
BA_REL_ "GenSigTimeoutTime" BU_SG_REL_ RKA_Plus SG_ 2000 DI1_Sekunde 5000;
BA_REL_ "GenSigTimeoutTime" BU_SG_REL_ AFS SG_ 2000 DI1_KM_Stand_alt 5000;
BA_REL_ "GenSigTimeoutTime" BU_SG_REL_ Airbag SG_ 2000 DI1_KM_Stand_alt 5000;
BA_REL_ "GenSigTimeoutTime" BU_SG_REL_ Allrad SG_ 2000 DI1_KM_Stand_alt 5000;
BA_REL_ "GenSigTimeoutTime" BU_SG_REL_ BMS_Hybrid SG_ 2000 DI1_KM_Stand_alt 5000;
BA_REL_ "GenSigTimeoutTime" BU_SG_REL_ Daempfer SG_ 2000 DI1_KM_Stand_alt 5000;
BA_REL_ "GenSigTimeoutTime" BU_SG_REL_ EPB_TRW_VW411CS SG_ 2000 DI1_KM_Stand_alt 5000;
BA_REL_ "GenSigTimeoutTime" BU_SG_REL_ FLA SG_ 2000 DI1_KM_Stand_alt 5000;
BA_REL_ "GenSigTimeoutTime" BU_SG_REL_ HCA SG_ 2000 DI1_KM_Stand_alt 5000;
BA_REL_ "GenSigTimeoutTime" BU_SG_REL_ LEH_Hybrid SG_ 2000 DI1_KM_Stand_alt 5000;
BA_REL_ "GenSigTimeoutTime" BU_SG_REL_ LH_EPS_APA SG_ 2000 DI1_KM_Stand_alt 5000;
BA_REL_ "GenSigTimeoutTime" BU_SG_REL_ LWR SG_ 2000 DI1_KM_Stand_alt 5000;
BA_REL_ "GenSigTimeoutTime" BU_SG_REL_ Magne_Ride SG_ 2000 DI1_KM_Stand_alt 5000;
BA_REL_ "GenSigTimeoutTime" BU_SG_REL_ Motor_Diesel SG_ 2000 DI1_KM_Stand_alt 5000;
BA_REL_ "GenSigTimeoutTime" BU_SG_REL_ Motor_Hybrid SG_ 2000 DI1_KM_Stand_alt 5000;
BA_REL_ "GenSigTimeoutTime" BU_SG_REL_ Motor_Otto SG_ 2000 DI1_KM_Stand_alt 5000;
BA_REL_ "GenSigTimeoutTime" BU_SG_REL_ PDC_PLA SG_ 2000 DI1_KM_Stand_alt 5000;
BA_REL_ "GenSigTimeoutTime" BU_SG_REL_ Quersperre_VAQ SG_ 2000 DI1_KM_Stand_alt 5000;
BA_REL_ "GenSigTimeoutTime" BU_SG_REL_ RKA_Plus SG_ 2000 DI1_KM_Stand_alt 5000;
BA_REL_ "GenSigTimeoutTime" BU_SG_REL_ AFS SG_ 2000 DI1_Zeit_alt 5000;
BA_REL_ "GenSigTimeoutTime" BU_SG_REL_ Airbag SG_ 2000 DI1_Zeit_alt 5000;
BA_REL_ "GenSigTimeoutTime" BU_SG_REL_ Allrad SG_ 2000 DI1_Zeit_alt 5000;
BA_REL_ "GenSigTimeoutTime" BU_SG_REL_ BMS_Hybrid SG_ 2000 DI1_Zeit_alt 5000;
BA_REL_ "GenSigTimeoutTime" BU_SG_REL_ Bremse_MK60EC SG_ 2000 DI1_Zeit_alt 5000;
BA_REL_ "GenSigTimeoutTime" BU_SG_REL_ Daempfer SG_ 2000 DI1_Zeit_alt 5000;
BA_REL_ "GenSigTimeoutTime" BU_SG_REL_ EPB_TRW_VW411CS SG_ 2000 DI1_Zeit_alt 5000;
BA_REL_ "GenSigTimeoutTime" BU_SG_REL_ FLA SG_ 2000 DI1_Zeit_alt 5000;
BA_REL_ "GenSigTimeoutTime" BU_SG_REL_ HCA SG_ 2000 DI1_Zeit_alt 5000;
BA_REL_ "GenSigTimeoutTime" BU_SG_REL_ LEH_Hybrid SG_ 2000 DI1_Zeit_alt 5000;
BA_REL_ "GenSigTimeoutTime" BU_SG_REL_ LH_EPS_APA SG_ 2000 DI1_Zeit_alt 5000;
BA_REL_ "GenSigTimeoutTime" BU_SG_REL_ LH_EPS_ZF_2G SG_ 2000 DI1_Zeit_alt 5000;
BA_REL_ "GenSigTimeoutTime" BU_SG_REL_ LH_EPS_ZF_3G SG_ 2000 DI1_Zeit_alt 5000;
BA_REL_ "GenSigTimeoutTime" BU_SG_REL_ LWR SG_ 2000 DI1_Zeit_alt 5000;
BA_REL_ "GenSigTimeoutTime" BU_SG_REL_ Magne_Ride SG_ 2000 DI1_Zeit_alt 5000;
BA_REL_ "GenSigTimeoutTime" BU_SG_REL_ Motor_Diesel SG_ 2000 DI1_Zeit_alt 5000;
BA_REL_ "GenSigTimeoutTime" BU_SG_REL_ Motor_Hybrid SG_ 2000 DI1_Zeit_alt 5000;
BA_REL_ "GenSigTimeoutTime" BU_SG_REL_ Motor_Otto SG_ 2000 DI1_Zeit_alt 5000;
BA_REL_ "GenSigTimeoutTime" BU_SG_REL_ PDC_PLA SG_ 2000 DI1_Zeit_alt 5000;
BA_REL_ "GenSigTimeoutTime" BU_SG_REL_ RKA_Plus SG_ 2000 DI1_Zeit_alt 5000;
BA_REL_ "GenSigTimeoutTime" BU_SG_REL_ Ladegeraet_EGolf SG_ 1562 Ladestecker_gesteckt 5000;
BA_REL_ "GenSigTimeoutTime" BU_SG_REL_ Gateway_PQ35 SG_ 1562 Ladevorgang_aktiv 5000;
BA_REL_ "GenSigTimeoutTime" BU_SG_REL_ Ladegeraet_EGolf SG_ 1562 HV_Bordnetz_aktiv 5000;
BA_REL_ "GenSigTimeoutTime" BU_SG_REL_ Ladegeraet_EGolf SG_ 1562 HV_Bordnetz_A_Status 5000;
BA_REL_ "GenSigTimeoutTime" BU_SG_REL_ Ladegeraet_EGolf SG_ 1562 Ladestecker_verr_Status 5000;
BA_REL_ "GenSigTimeoutTime" BU_SG_REL_ Ladegeraet_EGolf SG_ 1576 Ladezustand_HV_Batterie 5000;
VAL_ 1463 B11_HydHalten 0 "Fzg_wird_nicht_hydr_gehalten" 1 "Fzg_wird_hydr_gehalten" ;
VAL_ 1463 B11_Br_StSt_Info 0 "Motorlauf_nicht_notwendig_(Stoppfreigabe)" 1 "Motoranlauf_nicht_zwingend_notwendig_(Stoppverbot,keine_Startanforderung)" 2 "Motoranlauf_zwingend_notwendig_(Startanforderung)" 3 "Systemfehler" ;
VAL_ 1463 B11_OBD_Nib_VL 0 "kein_Fehler" 1 "KS_M" 2 "KS_P" 3 "OC" 4 "OOR_P" 5 "OOR_M" 6 "RC_P" 7 "RC_M" 8 "KS_P_OC" 9 "KS_M_OC" 10 "KS_MP" 11 "KS_MP_OC" 12 "frei" 13 "frei" 14 "frei" 15 "frei" ;
VAL_ 1463 B11_OBD_Nib_VR 0 "kein_Fehler" 1 "KS_M" 2 "KS_P" 3 "OC" 4 "OOR_P" 5 "OOR_M" 6 "RC_P" 7 "RC_M" 8 "KS_P_OC" 9 "KS_M_OC" 10 "KS_MP" 11 "KS_MP_OC" 12 "frei" 13 "frei" 14 "frei" 15 "frei" ;
VAL_ 1463 B11_OBD_Nib_HL 0 "kein_Fehler" 1 "KS_M" 2 "KS_P" 3 "OC" 4 "OOR_P" 5 "OOR_M" 6 "RC_P" 7 "RC_M" 8 "KS_P_OC" 9 "KS_M_OC" 10 "KS_MP" 11 "KS_MP_OC" 12 "frei" 13 "frei" 14 "frei" 15 "frei" ;
VAL_ 1463 B11_OBD_Nib_HR 0 "kein_Fehler" 1 "KS_M" 2 "KS_P" 3 "OC" 4 "OOR_P" 5 "OOR_M" 6 "RC_P" 7 "RC_M" 8 "KS_P_OC" 9 "KS_M_OC" 10 "KS_MP" 11 "KS_MP_OC" 12 "frei" 13 "frei" 14 "frei" 15 "frei" ;
VAL_ 1463 B11_EPB_Steller_akt 0 "EPB_Steller_verfaehrt_nicht" 1 "EPB_Steller_verfaehrt" ;
VAL_ 1463 B11_EPB_Steller_gue 0 "EPB_Steller_Info_ungueltig" 1 "EPB_Steller_Info_gueltig" ;
VAL_ 1440 BR2_Querbeschl 255 "Fehler" ;
VAL_ 1440 BR2_Querb_Zahn 0 "Querbeschl_In_Byte1" 1 "Zaehnezahl_in_Byte_1" ;
VAL_ 1440 BR2_mi_Radgeschw 32708 "Init_PQ25_35_46" 32725 "Unterspannung" 32742 "Sensorfehler" ;
VAL_ 1440 BR2_Lampe_ABS 0 "Lampe_aus" 1 "Lampe_ein" ;
VAL_ 1440 BR2_Lampe_ASR 0 "Lampe_aus" 1 "Lampe_ein" ;
VAL_ 1440 BR2_Lampe_BK 0 "Lampe_aus" 1 "Lampe_ein" ;
VAL_ 1440 BR2_Lampe_RKA 0 "Lampe_aus" 1 "Lampe_ein" ;
VAL_ 1440 BR2_Text 0 "Kein_Text" 1 "ESP_Stoerung" 2 "ABS_Stoerung" 3 "ESP_ABS_Stoerung" 4 "Werkstatt_Bremse" 5 "ASR_Stoerung" 6 "ESP_deaktiv" 7 "ASR_deaktiv" 8 "ESP_aktiv" 9 "Stoerung_Hillholder" 10 "Keine_BKVerstaerkung" 11 "ASR_aktiviert" 12 "ABS_ASR_Stoerung" 13 "Reifen_pruefen" ;
VAL_ 1440 BR2_Aku_Warn 0 "Kein_Gong_bzw_Summer" 1 "ein_Mal_Gong" 2 "drei_Mal_Gong_Summer" 3 "ein_Mal_Summer_2kHz" ;
VAL_ 1440 BR2_HDC_aktiv 0 "HDC_inaktiv" 1 "HDC_aktiv_oder_standby" ;
VAL_ 1440 BR2_Blinkmode 0 "Aus" 1 "Ein" ;
VAL_ 1440 BR2_Ueberl_Imp 0 "Reset_und_kein_Ueberlauf" 1 "mind_1mal_Ueberlauf" ;
VAL_ 1440 BR2_Fehlereintr 0 "kein_Fehlerspeichereintrag" 1 "Fehlerspeichereintrag" ;
VAL_ 1440 BR2_LampeHDC 0 "Lampe_aus" 1 "Lampe_ein" ;
VAL_ 1440 BR2_QB_Querbeschl 0 "gueltiger_Wert" 1 "Ersatz_Init_oder_Fehlerwert" ;
VAL_ 1440 BR2_Sta_Imp 0 "Wegimpulse_i_O" 1 "Fehler" ;
VAL_ 1440 BR2_SleepInd 0 "CAN_wird_benoetigt" 1 "Sleep_bereit" ;
VAL_ 1440 BR2_Sta_Quer 0 "errechnet" 1 "gemessen" ;
VAL_ 1184 BR3_Fahrtr_VL 0 "Vorwaerts" 1 "Rueckwaerts" ;
VAL_ 1184 BR3_Rad_kmh_VL 32708 "Init_PQ25_35_46" 32725 "Unterspannung" 32742 "Sensorfehler" ;
VAL_ 1184 BR3_Fahrtr_VR 0 "Vorwaerts" 1 "Rueckwaerts" ;
VAL_ 1184 BR3_Rad_kmh_VR 32708 "Init_PQ25_35_46" 32725 "Unterspannung" 32742 "Sensorfehler" ;
VAL_ 1184 BR3_Fahrtr_HL 0 "Vorwaerts" 1 "Rueckwaerts" ;
VAL_ 1184 BR3_Rad_kmh_HL 32708 "Init_PQ25_35_46" 32725 "Unterspannung" 32742 "Sensorfehler" ;
VAL_ 1184 BR3_Fahrtr_HR 0 "Vorwaerts" 1 "Rueckwaerts" ;
VAL_ 1184 BR3_Rad_kmh_HR 32708 "Init_PQ25_35_46" 32725 "Unterspannung" 32742 "Sensorfehler" ;
VAL_ 672 BR4_Vorgabe_Mi_ 0 "keine_Vorgabe" 127 "Kupplung_schnell_offen" 254 "Kupplung_ganz_schl" 255 "Fehler" ;
VAL_ 672 BR4_Vorgabe_Mi 127 "Kupplung_schnell_offen" 128 "Kupplung_oeffnen_0_Prozent" 254 "Kupplung_schliessen_100_Prozent" 255 "Fehler" ;
VAL_ 672 BR4_Vorgabe_Hi 127 "Kupplung_schnell_offen" 128 "Kupplung_oeffnen_0_Prozent" 254 "Kupplung_schliessen_100_Prozent" 255 "Fehler" ;
VAL_ 672 BR4_Einheit 0 "Nm_Haldex" 1 "Prozente" 2 "Nm_VAQ" ;
VAL_ 672 BR4_Schwelle 0 "kein_Signal" 1 "Unterdruck_klgl_450mbar" 2 "Unterdruck_gr_450mbar" 3 "U_Signal_temp_n_verf" ;
VAL_ 672 BR4_Abschaltung_VL 0 "EDS_VL_i_O" 1 "EDS_VL_Temp_Absch" ;
VAL_ 672 BR4_Abschaltung_VR 0 "EDS_VR_i_O" 1 "EDS_VR_Temp_Absch" ;
VAL_ 672 BR4_Abschaltung_HL 0 "EDS_HL_i_O" 1 "EDS_HL_Temp_Absch" ;
VAL_ 672 BR4_Abschaltung_HR 0 "EDS_HR_i_O" 1 "EDS_HR_Temp_Absch" ;
VAL_ 672 BR4_Lampe_RKA 0 "Lampe_aus" 1 "Lampe_ein" ;
VAL_ 672 BR4_Summer_RKA 0 "Summer_aus" 1 "Summer_ein" ;
VAL_ 672 BR4_Lampentrennung_gue 0 "ungueltig" 1 "gueltig" ;
VAL_ 672 BR4_Lampe_ASRESP 0 "Lampe_aus" 1 "Lampe_ein" ;
VAL_ 672 BR4_ESP_Off 0 "Lampe_aus" 1 "Lampe_ein" ;
VAL_ 672 BR1_ASR_ESP 0 "ABS_ABS_EDS" 1 "ASR_ESP_MABS" ;
VAL_ 672 BR4_RKA_Verbau 0 "kein_RKA_verbaut_oder_unbekannt" 1 "RKA_Signale_in_mBremse_2" 2 "RKA_Signale_in_mBremse_RKA" ;
VAL_ 672 BR4_Unterdruck 255 "Fehler" ;
VAL_ 672 BR4_Status_ESP 0 "VAQ_deaktiviert" 1 "ESP_Fehlerstatus" 2 "Kom_VAQ_gestoert" 3 "ESP_bereit" 4 "ESP_Anf_VAQ" 5 "AYC_Unterst_mo_regl_aktiv" ;
VAL_ 1192 BR5_Giergeschw 16381 "MABS_System" 16382 "ABS_only_System" 16383 "Fehler" ;
VAL_ 1192 BR5_Sta_Gierrate 0 "gueltig" 1 "ungueltig" ;
VAL_ 1192 BR5_Vorzeichen 0 "positives_Vorzeichen" 1 "negatives_Vorzeichen" ;
VAL_ 1192 BR5_Bremsdruck 4095 "Fehler" ;
VAL_ 1192 BR5_Stillstand 0 "kein_Stillstand_erkannt" 1 "Stillstand_erkannt" ;
VAL_ 1192 BR5_Druckgueltig 0 "gueltig" 1 "ungueltig" ;
VAL_ 1192 BR5_Sta_Druck 0 "kein_aktiver_Druckaufbau" 1 "aktiver_Druckaufbau" ;
VAL_ 1192 BR5_Sign_Druck 0 "positives_Vorzeichen" 1 "negatives_Vorzeichen" ;
VAL_ 1192 ESP_Anforderung_EPB 0 "keine_Anforderung" 1 "Anforderung_Oeffnen" 2 "Anforderung_Schliessen" 3 "Anforderung_Schliessen_mit_verminderter_Spannkraft" ;
VAL_ 1192 ESP_Autohold_aktiv 0 "Autohold_inaktiv" 1 "Autohold_aktiv" ;
VAL_ 1192 ESP_Autohold_Standby 0 "Autohold_nicht_im_Standby" 1 "Autohold_im_Standby" ;
VAL_ 1192 BR5_Anhi_Sta 0 "kein_Fehler" 1 "Fehler" ;
VAL_ 1192 BR5_Anhi_akt 0 "nicht_aktiv" 1 "aktiv" ;
VAL_ 1192 BR5_v_Ueberw 0 "nein" 1 "ja" ;
VAL_ 1192 BR5_AnhStabAktiv 0 "keine_Bremslichtanforderung" 1 "Bremslicht_an" ;
VAL_ 1192 BR5_Notbremsung 0 "keine_Notbremsung" 1 "Notbremsung_erk" ;
VAL_ 1192 BR5_Fahrer_tritt_ZBR_Schw 0 "Fahrer_uebertritt_ZBR_Schwelle_nicht" 1 "Fahrer_uebertritt_ZBR_Schwelle" ;
VAL_ 1192 BR5_AWV2_Bremsruck 0 "kein_Bremsruck" 1 "Bremsruck_wird_durchgefuehrt" ;
VAL_ 1192 BR5_AWV2_Fehler 0 "kein_Fehler" 1 "Fehler" ;
VAL_ 1192 BR5_ZT_Rueckk_Umsetz 0 "ZT_wird_nicht_durchgefuehrt" 1 "ZT_wird_durchgefuehrt" ;
VAL_ 1192 BR5_ANB_CM_Rueckk_Umsetz 0 "CM_wird_nicht_durchgefuehrt" 1 "CM_wird_durchgefuehrt" ;
VAL_ 1192 BR5_ECD_Lampe 0 "Aus" 1 "Ein" ;
VAL_ 428 BR8_Sta_ACC_Anf 0 "passiv" 1 "aktiv" ;
VAL_ 428 BR8_Verz_EPB_akt 0 "nicht_aktiviert" 1 "aktiviert" ;
VAL_ 428 BR8_Sta_Br_temp 0 "nicht_ueberhitzt" 1 "ueberhitzt" ;
VAL_ 428 BR8_Sta_Br_Druck 0 "Bremse_drucklos" 1 "mit_Bremsdruck" ;
VAL_ 428 BR8_Istbeschl 511 "Fehler" ;
VAL_ 428 BR8_Sta_HW_BLS 0 "Ausgang_iO" 1 "Ausgang_defekt" ;
VAL_ 428 BR8_QB_LBeschl 0 "gueltiger_Wert" 1 "Ersatz_Init_oder_Fehlerwert" ;
VAL_ 428 BR8_ESC_Mode 0 "ESC_Mode_0" 1 "ESC_Mode_1" 2 "ESC_Mode_2" 3 "ESC_Mode_3" ;
VAL_ 428 BR8_aktBrSyst 0 "nein" 1 "ja" ;
VAL_ 428 BR8_Fa_bremst 0 "Fahrer_bremst_nicht" 1 "Fahrer_bremst" ;
VAL_ 428 BR8_StaBrSyst 0 "System_inaktiv" 1 "System_aktiv" ;
VAL_ 428 BR8_Laengsbeschl 0 "Init" 1023 "Fehler" ;
VAL_ 428 BR8_Sta_ADR_BR 0 "ACC_Botschaft_konsistent" 1 "ACC_Botschaft_nicht_konsistent" ;
VAL_ 428 BR8_Quattro 0 "Front" 1 "Quattro" ;
VAL_ 428 BR8_Sta_VerzReg 0 "funktionsfaehig" 1 "nicht_funktionsfaehig" ;
VAL_ 428 BR8_Sta_BLS 0 "kein_Fehler" 1 "Fehler" ;
VAL_ 428 BR8_Verz_EPB 0 "nicht_verfuegbar" 1 "System_verfuegbar" ;
VAL_ 428 BR8_Check_EPB 0 "nicht_plausibel" 1 "plausibel" ;
VAL_ 174 BR9_Sta_ESP_PLA 0 "ESP_PLA_Deaktiv" 1 "EPS_PLA_Init" 2 "Fehler" 4 "ESP_PLA_Aktivierbar" 6 "ESP_PLA_Bremse_aktiv" 8 "ESP_PLA_funktionsbereit" 9 "ESP_PLA_Neustart" 10 "ESP_PLA_Abbruch" ;
VAL_ 174 BR9_LMOffSign 0 "positives_Vorzeichen" 1 "negatives_Vorzeichen" ;
VAL_ 174 BR9_LWOffSign 0 "positives_Vorzeichen" 1 "negatives_Vorzeichen" ;
VAL_ 174 BR9_Sta_DSR 0 "DSR_deaktiviert" 1 "DSR_Anf_nicht_ausfuehrbar" 2 "Kom_ESP_gestoert" 3 "ESP_funktionsbereit" 4 "offen" 5 "ext_Momeingriff_angef" 6 "ext_LWeingriff_angef" 7 "ext_MomLWeingriff_angef" ;
VAL_ 174 BR9_PLA_Abbruch 1 "Geschwindigkeitsueberschreitung" 2 "Falscher_PLA_Status" 3 "Deaktivierung_durch_Abbruch_Lenkung" 4 "PLA_Bremsanforderung_nach_Stillstand" 5 "Abbruch_durch_Kl15_aus" 6 "Abbruch_durch_FT_offen" ;
VAL_ 1524 BCN_AntriebsVar 0 "keine_Variante" 1 "front" 2 "quattro" 3 "reserviert" ;
VAL_ 1091 RKA_Prio1_Warnung 0 "keine_Warnung" 1 "Prio1_Warnung" ;
VAL_ 1091 RKA_Prio2_Warnung 0 "keine_Warnung" 1 "Prio2_Warnung" ;
VAL_ 1091 RKA_Warnungen 0 "keine_Warnung" 1 "RD_pruefen" 2 "RD_vl" 3 "RD_vr" 4 "RD_hl" 5 "RD_hr" 6 "RD_RR" 7 "an_Bel_anpassen" 8 "neue_Druecke_erk" 9 "Systemfehler" 10 "PAX" 11 "PAX_Stop" 14 "Belegung_nicht_moeglich_BY" 15 "Belegung_nicht_moeglich_BY" ;
VAL_ 1091 RKA_FMVSS_138_Warnung 0 "Lampe_aus" 1 "Lampe_ein" ;
VAL_ 1091 RKA_FMVSS_138_MIL 0 "MIL_aus" 1 "MIL_an" ;
VAL_ 1091 RDK_Status 0 "Aus" 1 "Ein" ;
VAL_ 1091 RKA_Ack_IstZu_Solldruecke 0 "keine_Bestaetigung" 1 "Bestaetigung_Soll_gleich_Istdruck" ;
VAL_ 1091 RDK_neue_Solldruecke 0 "keine_neuen_Solldruecke" 1 "es_liegen_neue_Solldruecke_vor" ;
VAL_ 1091 RKA_Menue 0 "Menue_RKA_gefordert" 1 "kein_Menue_RKA" ;
VAL_ 1091 RKA_KD_Fehler 0 "kein_Fehlerspeichereintrag" 1 "Fehlerspeichereintrag" ;
VAL_ 1091 RDK_Sensor_Multiplex 0 "vl" 1 "vr" 2 "hl" 3 "hr" 4 "RR" ;
VAL_ 1091 RDK_xx_Status_Sensor 0 "ungueltig" 1 "gueltig" ;
VAL_ 1091 RDK_xx_Color 0 "gruen" 1 "gelb" 2 "rot" ;
VAL_ 1392 BSL_ZAS_Kl_S 0 "Grundzustand" 1 "S_Kontakt_aktiv" ;
VAL_ 1392 BSL_ZAS_Kl_15 0 "Grundzustand" 1 "Klemme_15_aktiv" ;
VAL_ 1392 BSL_ZAS_Kl_X 0 "Grundzustand" 1 "Klemme_X_aktiv" ;
VAL_ 1392 BSL_ZAS_Kl_50 0 "Grundzustand" 1 "Klemme_50_aktiv" ;
VAL_ 1392 BSL_Parklicht 0 "Grundzustand" 1 "Klemme_P_aktiv" ;
VAL_ 1392 BSL_LL_Anheb2 0 "Grundzustand" 1 "Drehzahlanheb_Stufe2_gefordert" ;
VAL_ 1392 BSL_Kl_15_Motor 0 "Grundzustand" 1 "Klemme_14_aktiv" ;
VAL_ 1392 BSL_Kl_L 0 "Grundzustand" 1 "Klemme_L_aktiv" ;
VAL_ 1392 BSL_LL_Anheb 0 "Grundzustand" 1 "Drehzahlanheb_Stufe1_gefordert" ;
VAL_ 1392 BSL_Sta_UBat 0 "iO" 1 "kritisch" 2 "entladen" 3 "Fehler" ;
VAL_ 1392 BSL_Sta_StBat 0 "iO" 1 "kritisch" 2 "entladen" 3 "Fehler" ;
VAL_ 1392 BSL_Fehlereintr 0 "kein_Fehlerspeichereintrag" 1 "Fehlerspeichereintrag" ;
VAL_ 1392 BSL_Sta_LWR 0 "LWR_i_O" 1 "LWR_Fehler" ;
VAL_ 1392 BSL_Motor_Haube 0 "Haube_geschlossen" 1 "Haube_offen" ;
VAL_ 1392 BSL_UBat 255 "Fehler" ;
VAL_ 1392 BSL_Hecksch 0 "Grundzustand" 1 "Verbraucher_abschalten" ;
VAL_ 1392 BSL_Frontsch 0 "Grundzustand" 1 "Verbraucher_abschalten" ;
VAL_ 1392 BSL_Aussensp 0 "Grundzustand" 1 "Verbraucher_abschalten" ;
VAL_ 1392 BSL_Sitzheiz 0 "Grundzustand" 1 "Verbraucher_abschalten" ;
VAL_ 1392 BSL_Lenkradheiz 0 "Grundzustand" 1 "Verbraucher_abschalten" ;
VAL_ 1392 BSL_Wasserheiz 0 "Grundzustand" 1 "Verbraucher_abschalten" ;
VAL_ 1392 BSL_Sitzbelueft 0 "Grundzustand" 1 "Verbraucher_abschalten" ;
VAL_ 1392 BSL_Clima 0 "Grundzustand" 1 "Verbraucher_abschalten" ;
VAL_ 1392 BSL_BSG_2_alt 0 "aktuell_empfangen" 1 "veraltet" ;
VAL_ 1392 BSL_BSG_3_alt 0 "aktuell_empfangen" 1 "veraltet" ;
VAL_ 1392 BSL_Kuehlerlueft 0 "keine_Anforderung" 1 "einschalten" ;
VAL_ 1392 BSL_Ab_Batterie 0 "Batterie_am_Bordnetz" 1 "Batterie_ab" ;
VAL_ 1392 BSL_Weckursache_ACAN 0 "kein_EKP_Vorlauf" 2 "Weckursache_StHzg" 3 "Weckursache_Tuerkontakt" ;
VAL_ 1392 BSL_Wake_Up_ACAN 0 "kein_Wecken_ACAN" 1 "Wecken_ACAN" ;
VAL_ 1392 BSL_Starterlaubnis 0 "Start_nicht_erlaubt" 1 "Start_erlaubt" ;
VAL_ 1504 CL1_LL_Dz 0 "keine_Anhebung" 1 "Anhebung" ;
VAL_ 1504 CL1_Fa_Zuheiz 0 "Aus" 1 "Ein" ;
VAL_ 1504 CL1_Hecksch 0 "Aus" 1 "Ein" ;
VAL_ 1504 CL1_Frontsch 0 "Aus" 1 "Ein" ;
VAL_ 1504 CL1_Kompressor 0 "Aus" 1 "Ein" ;
VAL_ 1504 CL1_Heizleist 0 "Heizleistung" 1 "keine_Heizleistung" ;
VAL_ 1504 CL1_Sta_Moment 0 "aktuell" 1 "veraltet" ;
VAL_ 1504 CL1_Sta_Druck 0 "aktuell" 1 "veraltet" ;
VAL_ 1504 CL1_Aussentemp 255 "Fehler" ;
VAL_ 1504 CL1_Druck 255 "Fehler" ;
VAL_ 1504 CL1_Kompr_Last 255 "Fehler" ;
VAL_ 1504 CL1_Gebl_last 255 "Fehler" ;
VAL_ 1504 CL1_Luefter 255 "Fehler" ;
VAL_ 1504 CL1_Einheit_Temp 0 "Grad_C" 1 "Fahrenheit" ;
VAL_ 1504 CL1_AC_Schalter 0 "aus" 1 "ein_gedrueckt_oder_an" ;
VAL_ 1504 CL1_WAPU_Zuschaltung 0 "WAPU_EIN" 1 "WAPU_AUS" ;
VAL_ 1504 CL1_Restwaerme 0 "nicht_aktiviert" 1 "aktiviert" ;
VAL_ 1504 CL1_Fehlereintr 0 "kein_Fehlerspeichereintrag" 1 "Fehlerspeichereintrag" ;
VAL_ 1504 KL_Thermomanagement 0 "keine_Freigabe_TMM" 1 "kleine_Freigabe_TMM" 2 "mittlere_Freigabe_TMM" 3 "volle_Freigabe_TMM" ;
VAL_ 1432 DA1_Daempferreg 0 "Init_oder_kein_Wert_verfuegbar" 1 "komfortabel" 2 "normal" 3 "sport_1" 4 "sport_2" 5 "nicht_aktiv" 6 "nicht_definiert" 7 "Notfahrfunktion" ;
VAL_ 1432 DA1_Warnlampe 0 "Lampe_aus" 1 "Lampe_ein" ;
VAL_ 1432 DA1_Taster 0 "Taste_nicht_gedrueckt" 1 "Taste_gedrueckt" ;
VAL_ 1432 DA1_Systemstatus 0 "nicht_funktionsfaehig" 1 "funktionsfaehig" ;
VAL_ 1432 DA1_Fehlereintr 0 "kein_Fehlerspeichereintrag" 1 "Fehlerspeichereintrag" ;
VAL_ 1432 DA1_Textbits 0 "kein_Text" ;
VAL_ 1432 DA1_ESP_Zwang 0 "ESP_nicht_zuschalten" 1 "ESP_zwangszuschalten" ;
VAL_ 1432 DA1_LampPruef 0 "Lampe_nicht_aufpr" 1 "Lampe_aufpruefen" ;
VAL_ 1432 DA1_Charisma 0 "kein_Charisma" 1 "Charisma_aktiv" ;
VAL_ 2000 DI1_VerlernZaehl 255 "Fehler" ;
VAL_ 2000 DI1_Monat 0 "ungueltig" 13 "ungueltig" 14 "relatives_Datum" 15 "Spezialfall" ;
VAL_ 2000 DI1_Stunde 24 "ungueltig" 25 "ungueltig" 26 "ungueltig" 27 "ungueltig" 28 "ungueltig" 29 "ungueltig" 30 "ungueltig" 31 "ungueltig" ;
VAL_ 2000 DI1_Minute 60 "ungueltig" 61 "ungueltig" 62 "ungueltig" 63 "ungueltig" ;
VAL_ 2000 DI1_Sekunde 60 "ungueltig" 61 "ungueltig" 62 "ungueltig" 63 "ungueltig" ;
VAL_ 2000 DI1_KM_Stand_alt 0 "aktuell_empfangen" 1 "veraltet" ;
VAL_ 2000 DI1_Zeit_alt 0 "aktuell_empfangen" 1 "veraltet" ;
VAL_ 1562 Ladestecker_gesteckt 0 "inaktiv" 1 "aktiv" ;
VAL_ 1562 Ladevorgang_aktiv 0 "inaktiv" 1 "aktiv" ;
VAL_ 1562 HV_Bordnetz_aktiv 0 "inaktiv" 1 "aktiv" ;
VAL_ 1562 HV_PTC_LeistRed 0 "keine_LeistBegr" 1 "LeistBegr_75" 2 "LeistBegr_50" 3 "LeistBegr_25" ;
VAL_ 1562 HV_PTC_aus 0 "inaktiv" 1 "aktiv" ;
VAL_ 1562 Ladestecker_verr_Status 0 "entriegelt" 1 "verriegelt" 3 "Fehler" ;
VAL_ 1576 Energieinhalt_HV_Batt 511 "Fehler" ;
VAL_ 1576 Ladezustand_HV_Batterie 255 "Fehler" ;
VAL_ 1576 Stromnetz_vorhanden 0 "inaktiv" 1 "aktiv" ;
VAL_ 1576 BMS_Temperierung_Anf 0 "hoher_Kuehlbedarf" 1 "mittlerer_Kuehlbedarf" 2 "niedriger_Kuehlbedarf" 3 "kein_Temperierungsbedarf_Init" 4 "niedriger_Heizbedarf" 5 "mittlerer_Heizbedarf" 6 "hoher_Heizbedarf" 7 "Umwaelzungsbedarf" ;
